VERSION ""

NS_ :

BS_:

BU_: ARS_FD SHVU_CCS_FD WPC_FD WPC2_FD SCM_FD SHVU_FRNT_FD GW_SAU_DRV_FD ATS_FD PSB_FD GW_PSU_RR_FD SHVU_RL_FD RWPC_FD CGW_CCU OHCL_FD SHVU_REAR_FD BLTN_CAM_FD GW_PSU_DRV_FD FCS_FD GW_PSU_AST_FD GW_PSU_3RD_FD RCS_FD SHVU_3RD_FD GW_PSU_RL_FD SHVU_RR_FD RCM_FD SGU_FD DCM_FD

BO_ 829 SBCM_RR_FD_01_200ms: 24 CGW_CCU
 SG_ SBCM_RR_FD_Crc1Val : 0|16@1+ (1,0) [0|0] "" Vector__XXX
 SG_ USM_RRGhostDoorSta : 100|2@1+ (1,0) [0|0] "" Vector__XXX
 SG_ DoorLock_PDSLkSwSta_RR : 104|2@1+ (1,0) [0|0] "" Vector__XXX
 SG_ PDS_TypeOption_RR : 106|2@1+ (1,0) [0|0] "" Vector__XXX
 SG_ RR_CrashMRActAlarm : 138|2@1+ (1,0) [0|0] "" Vector__XXX
 SG_ PwrDRBuzzerOut_RR : 140|2@1+ (1,0) [0|0] "" Vector__XXX
 SG_ PwrDRClosingRRDrSta : 144|3@1+ (1,0) [0|0] ""  ATS_FD
 SG_ AFH_RR_FldUnfldSta : 150|2@1+ (1,0) [0|0] "" Vector__XXX
 SG_ SBCM_RR_FD_AlvCnt1Val : 16|8@1+ (1,0) [0|0] "" Vector__XXX
 SG_ DoorLock_RrRtLkOutSta_SBCM : 166|2@1+ (1,0) [0|0] "" Vector__XXX
 SG_ RrRt_DrLkRetryFail_SBCM : 171|2@1+ (1,0) [0|0] "" Vector__XXX
 SG_ RR_DetectObj_warn : 24|2@1+ (1,0) [0|0] ""  ATS_FD
 SG_ RRRrDrCurtainPosition : 26|2@1+ (1,0) [0|0] ""  ATS_FD
 SG_ RRRrDrCurtainDownInitState : 28|2@1+ (1,0) [0|0] "" Vector__XXX
 SG_ PwrDrSta_RrRt : 30|2@1+ (1,0) [0|0] ""  ATS_FD
 SG_ PwrDRBuzzerOut_RR_New : 32|3@1+ (1,0) [0|0] "" Vector__XXX
 SG_ SBCM_RR_SlidePosition : 40|8@1+ (1,0) [0|0] "%"  ATS_FD
 SG_ SBCM_RR_DoorAngle : 48|7@1+ (1,0) [0|0] "˚"  ATS_FD
 SG_ RRDoorPushAlarm : 72|2@1+ (1,0) [0|0] "" Vector__XXX
 SG_ RR_CrashUnlockCmd : 74|1@1+ (1,0) [0|0] ""  BLTN_CAM_FD
 SG_ Warn_RrRtDrSwSta_SBCM : 80|2@1+ (1,0) [0|0] ""  ATS_FD,BLTN_CAM_FD,DCM_FD,GW_PSU_AST_FD,GW_PSU_RR_FD,PSB_FD,RWPC_FD,WPC2_FD,WPC_FD
 SG_ DoorLock_RrRtDrUnLkSta_SBCM : 82|2@1+ (1,0) [0|0] ""  ATS_FD,FCS_FD
 SG_ RR_SEAActivated : 84|2@1+ (1,0) [0|0] ""  ATS_FD
 SG_ RR_SEAWarn : 86|2@1+ (1,0) [0|0] ""  ATS_FD
 SG_ RR_SEWWarn : 88|2@1+ (1,0) [0|0] "" Vector__XXX
 SG_ RR_ReleaseWarn : 90|2@1+ (1,0) [0|0] "" Vector__XXX
 SG_ RR_SWFailAlarm : 92|2@1+ (1,0) [0|0] ""  ATS_FD
 SG_ RR_ChildLock_ActnFlSta : 94|2@1+ (1,0) [0|0] "" Vector__XXX
 SG_ RR_MRActivationAlarm : 96|2@1+ (1,0) [0|0] "" Vector__XXX
 SG_ RR_ChildLock_Status : 98|2@1+ (1,0) [0|0] "" Vector__XXX

BO_ 1025 BDC_FD_SMK_02_200ms: 32 CGW_CCU
 SG_ BDC_FD_SMK_Crc2Val : 0|16@1+ (1,0) [0|0] ""  GW_PSU_DRV_FD
 SG_ SMK_RpmLoByteVal : 104|8@1+ (1,0) [0|0] "" Vector__XXX
 SG_ SMK_VehSpdDrctVal : 112|8@1+ (1,0) [0|0] "" Vector__XXX
 SG_ Fob_BattStaInfo : 120|2@1+ (1,0) [0|0] "" Vector__XXX
 SG_ Fob_FoundDrvWlcmArea : 122|2@1+ (1,0) [0|0] "" Vector__XXX
 SG_ Fob_FoundAsstWlcmArea : 124|2@1+ (1,0) [0|0] "" Vector__XXX
 SG_ Fob_FoundExtrnlArea : 126|2@1+ (1,0) [0|0] "" Vector__XXX
 SG_ Fob_FoundIntArea : 128|2@1+ (1,0) [0|0] "" Vector__XXX
 SG_ Fob_LearntSta : 130|2@1+ (1,0) [0|0] "" Vector__XXX
 SG_ RSPA_LearntSta : 132|2@1+ (1,0) [0|0] "" Vector__XXX
 SG_ RSPA_RFSigErrSta : 134|2@1+ (1,0) [0|0] "" Vector__XXX
 SG_ RSPA_CanErrSta : 136|2@1+ (1,0) [0|0] "" Vector__XXX
 SG_ RSPA_ModSta_SMK : 138|3@1+ (1,0) [0|0] ""  GW_PSU_DRV_FD
 SG_ RSPA_FobBattSta : 141|3@1+ (1,0) [0|0] "" Vector__XXX
 SG_ Fob_BtnReleasedSta : 144|2@1+ (1,0) [0|0] "" Vector__XXX
 SG_ Fob_FoundWlcmArea : 146|2@1+ (1,0) [0|0] "" Vector__XXX
 SG_ USM_WALModSta : 148|3@1+ (1,0) [0|0] "" Vector__XXX
 SG_ USM_SmrtTrnkTlgtModSta : 152|3@1+ (1,0) [0|0] "" Vector__XXX
 SG_ USM_SAUModSta : 155|3@1+ (1,0) [0|0] "" Vector__XXX
 SG_ SMK_RLHndLkSnsrSta : 158|2@1+ (1,0) [0|0] "" Vector__XXX
 SG_ BDC_FD_SMK_AlvCnt2Val : 16|8@1+ (1,0) [0|0] ""  GW_PSU_DRV_FD
 SG_ SMK_RLDrHndUnLkSnsrSta : 160|2@1+ (1,0) [0|0] "" Vector__XXX
 SG_ SMK_RRDrHndLkSnsrSta : 162|2@1+ (1,0) [0|0] "" Vector__XXX
 SG_ SMK_RRDrHndUnLkSnsrSta : 164|2@1+ (1,0) [0|0] "" Vector__XXX
 SG_ Fob_FoundCabinArea : 166|2@1+ (1,0) [0|0] "" Vector__XXX
 SG_ SMK_ResultRmtStrt : 168|3@1+ (1,0) [0|0] "" Vector__XXX
 SG_ SMK_EncryptTeleOptSta : 171|2@1+ (1,0) [0|0] "" Vector__XXX
 SG_ Auth_ISKLearnSta2 : 173|3@1+ (1,0) [0|0] "" Vector__XXX
 SG_ Auth_ISKLearnSta : 176|3@1+ (1,0) [0|0] "" Vector__XXX
 SG_ SMK_TlPwrOnSta : 179|2@1+ (1,0) [0|0] "" Vector__XXX
 SG_ Fob_FoundForChargingDoor : 181|2@1+ (1,0) [0|0] "" Vector__XXX
 SG_ SSB_StrtStpBtnSw1Sta : 24|2@1+ (1,0) [0|0] "" Vector__XXX
 SG_ SSB_StrtStpBtnSw2Sta : 26|2@1+ (1,0) [0|0] "" Vector__XXX
 SG_ SMK_AuthSta : 28|3@1+ (1,0) [0|0] ""  GW_PSU_AST_FD,GW_PSU_DRV_FD,PSB_FD
 SG_ SMK_TlPwrOnOpt : 31|1@1+ (1,0) [0|0] "" Vector__XXX
 SG_ SMK_Ign1InSta : 32|2@1+ (1,0) [0|0] "" Vector__XXX
 SG_ SMK_Ign1RlySta : 34|2@1+ (1,0) [0|0] "" Vector__XXX
 SG_ SMK_Ign2InSta : 36|2@1+ (1,0) [0|0] "" Vector__XXX
 SG_ SMK_Ign2RlySta : 38|2@1+ (1,0) [0|0] "" Vector__XXX
 SG_ SMK_StrtFdbckSta : 40|2@1+ (1,0) [0|0] "" Vector__XXX
 SG_ SMK_StrtrRlyOutSta : 42|2@1+ (1,0) [0|0] "" Vector__XXX
 SG_ SMK_AccInSta : 44|2@1+ (1,0) [0|0] "" Vector__XXX
 SG_ SMK_AccRlySta : 46|2@1+ (1,0) [0|0] "" Vector__XXX
 SG_ SMK_CLUAccIndOnReq : 48|2@1+ (1,0) [0|0] "" Vector__XXX
 SG_ SMK_VDModeActSta : 50|2@1+ (1,0) [0|0] "" Vector__XXX
 SG_ SMK_SCULckUnlckSta : 52|2@1+ (1,0) [0|0] "" Vector__XXX
 SG_ SMK_TlEngRunSta : 54|2@1+ (1,0) [0|0] ""  ATS_FD,GW_PSU_3RD_FD,GW_PSU_AST_FD,GW_PSU_DRV_FD,GW_PSU_RL_FD,GW_PSU_RR_FD,GW_SAU_DRV_FD,SHVU_3RD_FD,SHVU_CCS_FD,SHVU_FRNT_FD,SHVU_REAR_FD,SHVU_RL_FD,SHVU_RR_FD
 SG_ SMK_TlCrnkModSta : 56|2@1+ (1,0) [0|0] ""  ATS_FD,GW_PSU_AST_FD,GW_PSU_DRV_FD,GW_SAU_DRV_FD,SCM_FD
 SG_ SMK_RmtKeyEngRunSta : 58|2@1+ (1,0) [0|0] "" Vector__XXX
 SG_ SMK_RmtKeyCrnkModSta : 60|2@1+ (1,0) [0|0] "" Vector__XXX
 SG_ SMK_AsstTgglBtnSta : 62|2@1+ (1,0) [0|0] "" Vector__XXX
 SG_ SMK_DrvTglBtnSta : 64|2@1+ (1,0) [0|0] "" Vector__XXX
 SG_ SMK_RrLftTglBtnSta : 66|2@1+ (1,0) [0|0] "" Vector__XXX
 SG_ SMK_RrRtTglBtnSta : 68|2@1+ (1,0) [0|0] "" Vector__XXX
 SG_ SMK_TgglBtnStuckSta : 70|2@1+ (1,0) [0|0] "" Vector__XXX
 SG_ SMK_AsstDrHndUnLkSnsrSta : 72|2@1+ (1,0) [0|0] "" Vector__XXX
 SG_ SMK_BrkSwSta : 74|2@1+ (1,0) [0|0] "" Vector__XXX
 SG_ SMK_GearPosPSwSta : 76|2@1+ (1,0) [0|0] "" Vector__XXX
 SG_ SMK_CltchIgnLkSwSta : 78|2@1+ (1,0) [0|0] "" Vector__XXX
 SG_ SMK_DrvDrHndLkSnsrSta : 80|2@1+ (1,0) [0|0] "" Vector__XXX
 SG_ SMK_DrvDrHndUnLkSnsrSta : 82|2@1+ (1,0) [0|0] "" Vector__XXX
 SG_ SMK_AsstDrHndLkSnsrSta : 84|2@1+ (1,0) [0|0] "" Vector__XXX
 SG_ LFAnt_FltSta : 86|2@1+ (1,0) [0|0] "" Vector__XXX
 SG_ LFAnt_SrchSta : 88|2@1+ (1,0) [0|0] ""  RWPC_FD,WPC2_FD,WPC_FD
 SG_ Lamp_HzrdBlnkngSta : 90|3@1+ (1,0) [0|0] "" Vector__XXX
 SG_ Lamp_SmrtWlcmLtOnReq : 93|2@1+ (1,0) [0|0] "" Vector__XXX
 SG_ SMK_RpmHiByteVal : 96|8@1+ (1,0) [0|0] "" Vector__XXX

BO_ 830 SBCM_RL_FD_01_200ms: 24 CGW_CCU
 SG_ SBCM_RL_FD_Crc1Val : 0|16@1+ (1,0) [0|0] "" Vector__XXX
 SG_ USM_RLGhostDoorSta : 100|2@1+ (1,0) [0|0] "" Vector__XXX
 SG_ DoorLock_PDSLkSwSta_RL : 104|2@1+ (1,0) [0|0] "" Vector__XXX
 SG_ PDS_TypeOption_RL : 106|2@1+ (1,0) [0|0] "" Vector__XXX
 SG_ RL_CrashMRActAlarm : 138|2@1+ (1,0) [0|0] "" Vector__XXX
 SG_ PwrDRBuzzerOut_RL : 140|2@1+ (1,0) [0|0] "" Vector__XXX
 SG_ PwrDRClosingRLDrSta : 144|3@1+ (1,0) [0|0] ""  ATS_FD
 SG_ AFH_RL_FldUnfldSta : 150|2@1+ (1,0) [0|0] "" Vector__XXX
 SG_ SBCM_RL_FD_AlvCnt1Val : 16|8@1+ (1,0) [0|0] "" Vector__XXX
 SG_ DoorLock_RrLtLkOutSta_SBCM : 166|2@1+ (1,0) [0|0] "" Vector__XXX
 SG_ RrLt_DrLkRetryFail_SBCM : 171|2@1+ (1,0) [0|0] "" Vector__XXX
 SG_ RL_DetectObj_warn : 24|2@1+ (1,0) [0|0] ""  ATS_FD
 SG_ RLRrDrCurtainPosition : 26|2@1+ (1,0) [0|0] ""  ATS_FD
 SG_ RDC_TypeOption : 28|2@1+ (1,0) [0|0] ""  ATS_FD
 SG_ RLRrDrCurtainDownInitState : 30|2@1+ (1,0) [0|0] "" Vector__XXX
 SG_ PwrDRBuzzerOut_RL_New : 32|3@1+ (1,0) [0|0] "" Vector__XXX
 SG_ PwrDrSta_RrLt : 38|2@1+ (1,0) [0|0] ""  ATS_FD
 SG_ SBCM_RL_SlidePosition : 40|8@1+ (1,0) [0|0] "%"  ATS_FD
 SG_ SBCM_RL_DoorAngle : 48|7@1+ (1,0) [0|0] "˚"  ATS_FD
 SG_ RLDoorPushAlarm : 72|2@1+ (1,0) [0|0] "" Vector__XXX
 SG_ RL_CrashUnlockCmd : 74|1@1+ (1,0) [0|0] ""  BLTN_CAM_FD
 SG_ Warn_RrLftDrSwSta_SBCM : 80|2@1+ (1,0) [0|0] ""  ATS_FD,BLTN_CAM_FD,DCM_FD,GW_PSU_AST_FD,PSB_FD,RWPC_FD,WPC2_FD,WPC_FD
 SG_ DoorLock_RrLftDrUnLkSta_SBCM : 82|2@1+ (1,0) [0|0] ""  ATS_FD,FCS_FD
 SG_ RL_SEAActivated : 84|2@1+ (1,0) [0|0] ""  ATS_FD
 SG_ RL_SEAWarn : 86|2@1+ (1,0) [0|0] ""  ATS_FD
 SG_ RL_SEWWarn : 88|2@1+ (1,0) [0|0] "" Vector__XXX
 SG_ RL_ReleaseWarn : 90|2@1+ (1,0) [0|0] "" Vector__XXX
 SG_ RL_SWFailAlarm : 92|2@1+ (1,0) [0|0] ""  ATS_FD
 SG_ RL_ChildLock_ActnFlSta : 94|2@1+ (1,0) [0|0] "" Vector__XXX
 SG_ RL_MRActivationAlarm : 96|2@1+ (1,0) [0|0] "" Vector__XXX
 SG_ RL_ChildLock_Status : 98|2@1+ (1,0) [0|0] "" Vector__XXX

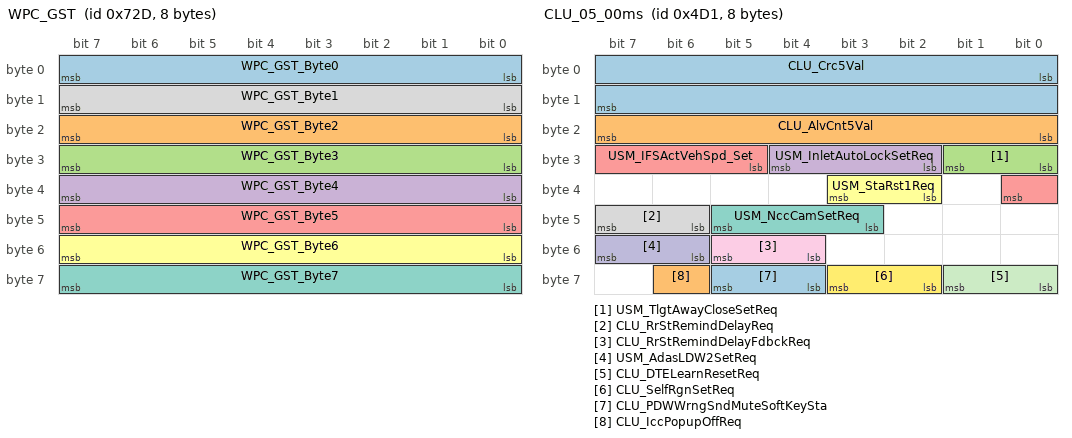
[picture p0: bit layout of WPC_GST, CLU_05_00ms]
BO_ 1837 WPC_GST: 8 WPC_FD
 SG_ WPC_GST_Byte0 : 0|8@1+ (1,0) [0|0] ""  CGW_CCU
 SG_ WPC_GST_Byte2 : 16|8@1+ (1,0) [0|0] ""  CGW_CCU
 SG_ WPC_GST_Byte3 : 24|8@1+ (1,0) [0|0] ""  CGW_CCU
 SG_ WPC_GST_Byte4 : 32|8@1+ (1,0) [0|0] ""  CGW_CCU
 SG_ WPC_GST_Byte5 : 40|8@1+ (1,0) [0|0] ""  CGW_CCU
 SG_ WPC_GST_Byte6 : 48|8@1+ (1,0) [0|0] ""  CGW_CCU
 SG_ WPC_GST_Byte7 : 56|8@1+ (1,0) [0|0] ""  CGW_CCU
 SG_ WPC_GST_Byte1 : 8|8@1+ (1,0) [0|0] ""  CGW_CCU

BO_ 256 EMS_02_10ms: 32 CGW_CCU
 SG_ EMS_Crc2Val : 0|16@1+ (1,0) [0|0] ""  GW_PSU_DRV_FD
 SG_ ACC_CrsMainSwLmpSta : 104|2@1+ (1,0) [0|0] "" Vector__XXX
 SG_ ACC_CrsSetSwLmpSta : 106|2@1+ (1,0) [0|0] "" Vector__XXX
 SG_ ENG_LV_FUP_ENA_THD : 109|1@1+ (1,0) [0|0] "" Vector__XXX
 SG_ ENG_SoakTimeErrSta : 110|2@1+ (1,0) [0|0] "" Vector__XXX
 SG_ ENG_SoakTimeVal : 112|8@1+ (1,0) [0|0] "Min" Vector__XXX
 SG_ ENG_SprkTimeVal : 120|8@1+ (0.375,-35.625) [0|0] "˚" Vector__XXX
 SG_ ENG_MinIndTqVal : 128|12@1- (1,0) [0|0] "Nm" Vector__XXX
 SG_ ENG_TrgtTqVal : 144|12@1- (1,0) [0|0] "Nm" Vector__XXX
 SG_ EMS_AlvCnt2Val : 16|8@1+ (1,0) [0|0] ""  GW_PSU_DRV_FD
 SG_ ENG_MaxIndTqVal : 160|12@1- (1,0) [0|0] "Nm" Vector__XXX
 SG_ ENG_AppAccelPdlSta : 176|2@1+ (1,0) [0|0] "" Vector__XXX
 SG_ ENG_BrkCtrlReq : 178|2@1+ (1,0) [0|0] "" Vector__XXX
 SG_ ACC_DnShftCtrlReq : 180|4@1+ (1,0) [0|0] "" Vector__XXX
 SG_ ENG_DclBrkCntrlReq : 192|12@1+ (0.001,-4.094) [0|0] "m/s^2" Vector__XXX
 SG_ ENG_BstPrsrVal : 204|12@1+ (1.322,0) [0|0] "hPa" Vector__XXX
 SG_ ENG_EngOilTempVal : 216|8@1+ (0.75,-40) [0|0] "℃" Vector__XXX
 SG_ ENG_AmbtTempModelVal : 224|8@1+ (0.5,-41) [0|0] "℃" Vector__XXX
 SG_ ENG_DpfWrngSta : 232|2@1+ (1,0) [0|0] "" Vector__XXX
 SG_ ENG_BattWrngLmpSta : 234|2@1+ (1,0) [0|0] "" Vector__XXX
 SG_ ENG_OilPrsrWrngLmpSta : 236|2@1+ (1,0) [0|0] "" Vector__XXX
 SG_ ENG_IsgInhbtLmpSta : 238|2@1+ (1,0) [0|0] ""  FCS_FD
 SG_ ENG_BrkSwSta : 32|2@1+ (1,0) [0|0] ""  BLTN_CAM_FD
 SG_ ENG_ObdFrzFrmSta : 34|6@1+ (1,0) [0|0] "" Vector__XXX
 SG_ ENG_EngClntTempVal : 40|8@1+ (0.75,-48) [0|0] "℃" Vector__XXX
 SG_ ENG_MafCrctVal : 48|8@1+ (0.00781,0) [0|0] "" Vector__XXX
 SG_ ENG_BattDscnctSta : 56|2@1+ (1,0) [0|0] "" Vector__XXX
 SG_ OBD_MilConfgVal : 58|3@1+ (1,0) [0|0] "" Vector__XXX
 SG_ ENG_EngSta : 61|3@1+ (1,0) [0|0] ""  BLTN_CAM_FD,GW_PSU_3RD_FD,GW_PSU_AST_FD,GW_PSU_DRV_FD,GW_PSU_RL_FD,GW_PSU_RR_FD,GW_SAU_DRV_FD,PSB_FD,RCM_FD,RWPC_FD,SCM_FD,SHVU_3RD_FD,SHVU_CCS_FD,SHVU_FRNT_FD,SHVU_REAR_FD,SHVU_RL_FD,SHVU_RR_FD,WPC2_FD,WPC_FD
 SG_ ENG_Ack4EngStpSta : 64|2@1+ (1,0) [0|0] "" Vector__XXX
 SG_ ENG_OverDrvOffReq : 66|2@1+ (1,0) [0|0] "" Vector__XXX
 SG_ ENG_AccActSta : 68|2@1+ (1,0) [0|0] "" Vector__XXX
 SG_ ENG_CltchOpSta : 70|2@1+ (1,0) [0|0] "" Vector__XXX
 SG_ EMS_BrkReq_Slope : 72|1@1+ (1,0) [0|0] "" Vector__XXX
 SG_ ENG_AccDrvAlertDisp : 74|2@1+ (1,0) [0|0] "" Vector__XXX
 SG_ DSL_GlowCtrlReq : 76|2@1+ (1,0) [0|0] "" Vector__XXX
 SG_ ENG_GlowLmpSta : 78|2@1+ (1,0) [0|0] "" Vector__XXX
 SG_ ENG_ThrPosVal : 80|8@1+ (0.4694836,-15.0234742) [0|0] "%" Vector__XXX
 SG_ ENG_AccelPdlVal : 88|10@1+ (0.09784,0) [0|0] "%"  BLTN_CAM_FD

BO_ 1233 CLU_05_00ms: 8 CGW_CCU
 SG_ CLU_Crc5Val : 0|16@1+ (1,0) [0|0] ""  GW_PSU_DRV_FD
 SG_ CLU_AlvCnt5Val : 16|8@1+ (1,0) [0|0] ""  GW_PSU_DRV_FD
 SG_ USM_TlgtAwayCloseSetReq : 24|2@1+ (1,0) [0|0] "" Vector__XXX
 SG_ USM_InletAutoLockSetReq : 26|3@1+ (1,0) [0|0] "" Vector__XXX
 SG_ USM_IFSActVehSpd_Set : 29|4@1+ (1,0) [0|0] "" Vector__XXX
 SG_ USM_StaRst1Req : 34|2@1+ (1,0) [0|0] ""  GW_PSU_DRV_FD,WPC2_FD,WPC_FD
 SG_ USM_NccCamSetReq : 43|3@1+ (1,0) [0|0] "" Vector__XXX
 SG_ CLU_RrStRemindDelayReq : 46|2@1+ (1,0) [0|0] "" Vector__XXX
 SG_ CLU_RrStRemindDelayFdbckReq : 52|2@1+ (1,0) [0|0] "" Vector__XXX
 SG_ USM_AdasLDW2SetReq : 54|2@1+ (1,0) [0|0] "" Vector__XXX
 SG_ CLU_DTELearnResetReq : 56|2@1+ (1,0) [0|0] "" Vector__XXX
 SG_ CLU_SelfRgnSetReq : 58|2@1+ (1,0) [0|0] "" Vector__XXX
 SG_ CLU_PDWWrngSndMuteSoftKeySta : 60|2@1+ (1,0) [0|0] "" Vector__XXX
 SG_ CLU_IccPopupOffReq : 62|1@1+ (1,0) [0|0] "" Vector__XXX

BO_ 870 HU_GW_03_200ms: 24 CGW_CCU
 SG_ HU_GW_Crc3Val : 0|16@1+ (1,0) [0|0] ""  GW_PSU_DRV_FD
 SG_ AVN_RSPA_Disp_Rdy : 102|2@1+ (1,0) [0|0] "" Vector__XXX
 SG_ CF_AVN_ProfileIDRValue : 104|4@1+ (1,0) [0|0] ""  BLTN_CAM_FD,GW_PSU_DRV_FD,GW_SAU_DRV_FD,RCM_FD,RWPC_FD,SGU_FD,WPC2_FD,WPC_FD
 SG_ HazardFromHUSVM : 108|2@1+ (1,0) [0|0] "" Vector__XXX
 SG_ OMUOSMirCtrl : 110|2@1+ (1,0) [0|0] "" Vector__XXX
 SG_ OTAUIStatus : 120|2@1+ (1,0) [0|0] "" Vector__XXX
 SG_ C_TeleActiveStatus : 122|2@1+ (1,0) [0|0] "" Vector__XXX
 SG_ HU_RTCCheck : 126|2@1+ (1,0) [0|0] ""  GW_PSU_AST_FD
 SG_ HU_GW_AlvCnt3Val : 16|8@1+ (1,0) [0|0] ""  GW_PSU_DRV_FD
 SG_ HU_SWRCWarmerSet : 182|2@1+ (1,0) [0|0] "" Vector__XXX
 SG_ HU_TrModeReq_PE : 24|3@1+ (1,0) [0|0] "" Vector__XXX
 SG_ HU_TrBrakeTypeReq_PE : 27|3@1+ (1,0) [0|0] "" Vector__XXX
 SG_ AVN_MRA_Disp_Rdy : 56|2@1+ (1,0) [0|0] "" Vector__XXX
 SG_ AVN_PRK_Func_Selected : 58|4@1+ (1,0) [0|0] "" Vector__XXX
 SG_ AVN_MRA_CancelInput : 62|2@1+ (1,0) [0|0] "" Vector__XXX
 SG_ HU_DistanceUnit : 64|2@1+ (1,0) [0|0] "" Vector__XXX
 SG_ HU_Scheduled_Setting : 66|4@1+ (1,0) [0|0] "" Vector__XXX
 SG_ HU_AliveStatus : 70|2@1+ (1,0) [0|0] "" Vector__XXX
 SG_ HU_ThemeType : 74|6@1+ (1,0) [0|0] ""  ATS_FD,BLTN_CAM_FD
 SG_ HU_MicActivity : 81|2@1+ (1,0) [0|0] "" Vector__XXX
 SG_ AVN_RSPA_ModeSelect : 84|4@1+ (1,0) [0|0] "" Vector__XXX
 SG_ CF_HU_GPSFlt : 88|2@1+ (1,0) [0|0] "" Vector__XXX
 SG_ AVN_RSPA_CancelInput : 90|2@1+ (1,0) [0|3] "" Vector__XXX

BO_ 261 EMS_07_10ms: 32 CGW_CCU
 SG_ EMS_Crc7Val : 0|16@1+ (1,0) [0|0] "" Vector__XXX
 SG_ HEV_AccelPdlVal : 103|10@1+ (0.09784,0) [0|0] "%"  BLTN_CAM_FD
 SG_ HEV_IndTqTar : 113|8@1+ (0.3906,0) [0|0] "%" Vector__XXX
 SG_ HEV_IndTqVal_Extd : 128|14@1+ (0.1,0) [0|0] "Nm" Vector__XXX
 SG_ EMS_AlvCnt7Val : 16|8@1+ (1,0) [0|0] "" Vector__XXX
 SG_ HEV_IndTqVal : 24|12@1+ (0.1,0) [0|0] "Nm" Vector__XXX
 SG_ HEV_DrvTqVal : 36|12@1+ (0.390625,0) [0|0] "%" Vector__XXX
 SG_ HEV_TqStndVal : 48|6@1+ (10,0) [0|0] "Nm" Vector__XXX
 SG_ HEV_OilDilution_IncICELoad : 54|1@1+ (1,0) [0|0] "" Vector__XXX
 SG_ HEV_OilDilution_ServMode : 56|2@1+ (1,0) [0|0] "" Vector__XXX
 SG_ EMS_TqLmtSta : 58|3@1+ (1,0) [0|0] "" Vector__XXX
 SG_ EMS_EU7 : 61|1@1+ (1,0) [0|0] "" Vector__XXX
 SG_ HEV_FrctTqVal : 64|12@1+ (0.1,0) [0|0] "Nm" Vector__XXX
 SG_ HEV_EngSpdVal : 76|16@1+ (0.25,0) [0|0] "rpm" Vector__XXX
 SG_ HEV_EngOpSta : 92|3@1+ (1,0) [0|0] ""  GW_PSU_3RD_FD,RWPC_FD,WPC2_FD,WPC_FD
 SG_ HEV_IntakeAirTempVal : 95|8@1+ (0.75,-48) [0|0] "℃" Vector__XXX

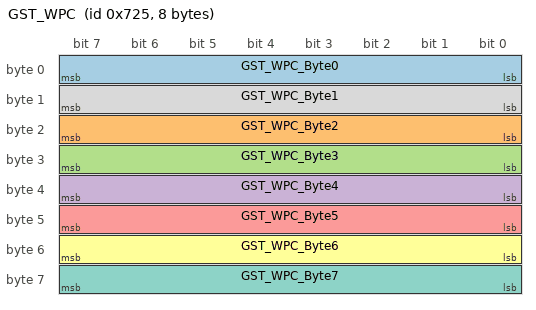
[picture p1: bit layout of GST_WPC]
BO_ 1829 GST_WPC: 8 CGW_CCU
 SG_ GST_WPC_Byte0 : 0|8@1+ (1,0) [0|0] ""  WPC_FD
 SG_ GST_WPC_Byte2 : 16|8@1+ (1,0) [0|0] ""  WPC_FD
 SG_ GST_WPC_Byte3 : 24|8@1+ (1,0) [0|0] ""  WPC_FD
 SG_ GST_WPC_Byte4 : 32|8@1+ (1,0) [0|0] ""  WPC_FD
 SG_ GST_WPC_Byte5 : 40|8@1+ (1,0) [0|0] ""  WPC_FD
 SG_ GST_WPC_Byte6 : 48|8@1+ (1,0) [0|0] ""  WPC_FD
 SG_ GST_WPC_Byte7 : 56|8@1+ (1,0) [0|0] ""  WPC_FD
 SG_ GST_WPC_Byte1 : 8|8@1+ (1,0) [0|0] ""  WPC_FD

CM_ BO_ 829 "[PE] Periodic and On Event";
CM_ SG_ 829 SBCM_RR_FD_Crc1Val "SBCM_RR_FD_CyclicRedundancyCheck1Value";
CM_ SG_ 829 SBCM_RR_FD_AlvCnt1Val "SBCM_RR_FD_AliveCounter1Value";
CM_ SG_ 829 RR_CrashUnlockCmd "Rear Right Crash Unlock Command";
CM_ SG_ 829 Warn_RrRtDrSwSta_SBCM "Warn_RearRightDoorSwitchStatus ##2G## -  - C_RRDrSw,CF_Gway_RRDrSw,Warn_RrRtDrSwSta";
CM_ SG_ 829 DoorLock_RrRtDrUnLkSta_SBCM "DoorLock_RearRightDoorUnLockStatus ##2G## -  - C_RRUnlockState,DoorLock_RrRtDrUnLkSta";
CM_ SG_ 829 RR_SEAActivated "Rear Right SEA Activated";
CM_ SG_ 829 RR_SEAWarn "Rear Righr SEA Warning";
CM_ BO_ 1025 "[PE] Periodic and On Event";
CM_ SG_ 1025 BDC_FD_SMK_Crc2Val "BDC_FD_SMK_CyclicRedundancyCheck2Value";
CM_ SG_ 1025 SMK_RpmLoByteVal "SMK_RpmLowByteValue ##2G##SMK - SMKmsg65 - C_RPMLowByte";
CM_ SG_ 1025 SMK_VehSpdDrctVal "SMK_VehicleSpeedDirectValue ##2G##SMK - SMKmsg65 - C_VehicleSpeedDirect";
CM_ SG_ 1025 Fob_BattStaInfo "Fob_BatteryStatusInformation ##2G##SMK - SMKmsg17 - C_FOBBatteryStatusInfo";
CM_ SG_ 1025 Fob_FoundDrvWlcmArea "Fob_FoundDriverWelcomeArea ##2G##SMK - SMKmsg17 - C_WelcomeFobFoundDrv";
CM_ SG_ 1025 Fob_FoundAsstWlcmArea "Fob_FoundAssistWelcomeArea ##2G##SMK - SMKmsg17 - C_WelcomeFobFoundAst";
CM_ SG_ 1025 Fob_FoundExtrnlArea "Fob_FoundExternalArea ##2G##SMK - SMKmsg18 - C_ExtFobPos";
CM_ SG_ 1025 Fob_FoundIntArea "Fob_FoundInternalArea ##2G##SMK - SMKmsg18 - C_IntFobPos";
CM_ SG_ 1025 Fob_LearntSta "Fob_LearntStatus ##2G##SMK - SMKmsg18 - C_FobLearntState";
CM_ SG_ 1025 RSPA_RFSigErrSta "RSPA_RFSignalErrorState";
CM_ SG_ 1025 RSPA_CanErrSta "RSPA_CANErrorState";
CM_ SG_ 1025 RSPA_ModSta_SMK "RSPA_ModeStatus ##2G##SMK - SMKmsg18 - C_SMKRSPAMode";
CM_ SG_ 1025 RSPA_FobBattSta "RSPA_FobBatteryStatus ##2G##SMK - SMKmsg18 - C_FobBATState";
CM_ SG_ 1025 Fob_FoundWlcmArea "Fob_FoundWlcmArea ##2G##SMK - SMKmsg17 -C_FobFoundWlcmArea";
CM_ SG_ 1025 USM_WALModSta "USM_WalkAwayLockModeStatus ##2G##SMK - SMKmsg20 - C_WALRValue";
CM_ SG_ 1025 USM_SmrtTrnkTlgtModSta "USM_SmartTunkTailgateModeStatus ##2G##SMK - SMKmsg20 - C_HfreeTrunkTgRValue";
CM_ SG_ 1025 BDC_FD_SMK_AlvCnt2Val "BDC_FD_SMK_AliveCounter2Value";
CM_ SG_ 1025 SMK_ResultRmtStrt "This signal is used to check for Tele Engine Running Result.";
CM_ SG_ 1025 SMK_EncryptTeleOptSta "This signal is used to check for option applied Remote Start Encryption.";
CM_ SG_ 1025 Auth_ISKLearnSta2 "This signal is State of IAU Learning for New China BLE";
CM_ SG_ 1025 Auth_ISKLearnSta "Fob_FoundAssistWelcomeArea ##2G##SMK - SMKmsg178 - C_IBUISKLearnState";
CM_ SG_ 1025 SMK_TlPwrOnSta "This signal is state of Tele Power On";
CM_ SG_ 1025 SSB_StrtStpBtnSw1Sta "SSB_StartStopButtonSwitch1Status ##2G##SMK - SMKmsg19 - C_SSBSW1";
CM_ SG_ 1025 SSB_StrtStpBtnSw2Sta "SSB_StartStopButtonSwitch2Status ##2G##SMK - SMKmsg19 - C_SSBSW2";
CM_ SG_ 1025 SMK_AuthSta "SMK_AuthentificationStatus ##2G##SMK - SMKmsg18 - C_AuthState";
CM_ SG_ 1025 SMK_TlPwrOnOpt "This signal is used to check option status of Tele Power On";
CM_ SG_ 1025 SMK_Ign1InSta "SMK_Ign1InputStatus ##2G##SMK - SMKmsg19 - C_Ign1SMK";
CM_ SG_ 1025 SMK_Ign1RlySta "SMK_Ign1RelayStatus ##2G##SMK - SMKmsg19 - C_Ign1RelayState";
CM_ SG_ 1025 SMK_Ign2InSta "SMK_Ign2InputStatus ##2G##SMK - SMKmsg19 - C_Ign2SMK";
CM_ SG_ 1025 SMK_Ign2RlySta "SMK_Ign2RelayStatus ##2G##SMK - SMKmsg19 - C_Ign2RelayState";
CM_ SG_ 1025 SMK_StrtFdbckSta "SMK_StartFeedbackStatus ##2G##SMK - SMKmsg19 - C_StartFeedback";
CM_ SG_ 1025 SMK_StrtrRlyOutSta "SMK_StarterRelayOutputStatus ##2G##SMK - SMKmsg18 - C_StarterRlyState";
CM_ SG_ 1025 SMK_AccInSta "SMK_AccInputStatus ##2G##SMK - SMKmsg19 - C_AccSMK";
CM_ SG_ 1025 SMK_AccRlySta "SMK_AccRelayStatus ##2G##SMK - SMKmsg19 - C_AccRelayStatus";
CM_ SG_ 1025 SMK_CLUAccIndOnReq "SMK_ClusterACCIndicatorOnRequest ##2G##SMK - SMKmsg19 - C_AccINDforCLU";
CM_ SG_ 1025 SMK_VDModeActSta "SMK_VirtualDriverModeActState";
CM_ SG_ 1025 SMK_SCULckUnlckSta "SCU Lock/Unlock Status";
CM_ SG_ 1025 SMK_TlEngRunSta "SMK_TeleEngineRunStatus ##2G##SMK - SMKmsg18 - C_SMKTeleEngineRunning";
CM_ SG_ 1025 SMK_TlCrnkModSta "SMK_TeleCrankingModeStatus ##2G##SMK - SMKmsg18 - C_SMKTeleCrankingState";
CM_ SG_ 1025 SMK_RmtKeyEngRunSta "SMK_RemoteKeyEngineRunStatus";
CM_ SG_ 1025 SMK_RmtKeyCrnkModSta "SMK_RemoteKeyCrankingModeStatus";
CM_ SG_ 1025 SMK_AsstTgglBtnSta "SMK_AssistToggleButtonStatus ##2G##SMK - SMKmsg19 - C_AstToggleButton";
CM_ SG_ 1025 SMK_DrvTglBtnSta "SMK_DriverToggleButtonStatus ##2G##SMK - SMKmsg19 - C_DrvToggleButton";
CM_ SG_ 1025 SMK_RrLftTglBtnSta "SMK_RearLeftToggleButtonStatus ##2G##SMK - SMKmsg19 - C_RRDRVToggleButton";
CM_ SG_ 1025 SMK_RrRtTglBtnSta "SMK_RearRightToggleButtonStatus ##2G##SMK - SMKmsg19 - C_RRASTToggleButton";
CM_ SG_ 1025 SMK_TgglBtnStuckSta "SMK_ToggleButtonStuckStatus ##2G##SMK - SMKmsg18 - C_ToggleButtonStuck";
CM_ SG_ 1025 SMK_AsstDrHndUnLkSnsrSta "SMK_AssistToggleButtonStatus ##2G##SMK - SMKmsg19 - C_ASTDoorUnLock";
CM_ SG_ 1025 SMK_BrkSwSta "SMK_BrakeSwitchStatus ##2G##SMK - SMKmsg19 - C_BrakeSW";
CM_ SG_ 1025 SMK_GearPosPSwSta "SMK_GearPositionPSwitchStatus ##2G##SMK - SMKmsg19 - C_PpositionClutch";
CM_ SG_ 1025 SMK_CltchIgnLkSwSta "SMK_ClutchIgnLockSwitchStatus ##2G##SMK - SMKmsg19 - C_ClutchIgnLockSW";
CM_ SG_ 1025 SMK_DrvDrHndLkSnsrSta "SMK_DriverToggleButtonStatus ##2G##SMK - SMKmsg19 - C_DRVDoorLock";
CM_ SG_ 1025 SMK_DrvDrHndUnLkSnsrSta "SMK_AssistToggleButtonStatus ##2G##SMK - SMKmsg19 - C_DRVDoorUnlock";
CM_ SG_ 1025 SMK_AsstDrHndLkSnsrSta "SMK_AssistToggleButtonStatus ##2G##SMK - SMKmsg19 - C_ASTDoorLock";
CM_ SG_ 1025 LFAnt_FltSta "LFAntenna_FaultSatus ##2G##SMK - SMKmsg18 - C_LFANTState";
CM_ SG_ 1025 LFAnt_SrchSta "LFAntenna_SearchingStatus ##2G##SMK - SMKmsg19 - C_LFSearchingOn";
CM_ SG_ 1025 Lamp_HzrdBlnkngSta "Lamp_HazardBlinkingStatus ##2G##SMK - SMKmsg17 - C_HazardFromSMK";
CM_ SG_ 1025 Lamp_SmrtWlcmLtOnReq "Lamp_SmartWelcomeLightOnRequest ##2G##SMK - SMKmsg17 - C_WlightOn";
CM_ SG_ 1025 SMK_RpmHiByteVal "SMK_RpmHighByteValue ##2G##SMK - SMKmsg65 - C_RPMHighByte";
CM_ BO_ 830 "[PE] Periodic and On Event";
CM_ SG_ 830 SBCM_RL_FD_Crc1Val "SBCM_RL_FD_CyclicRedundancyCheck1Value";
CM_ SG_ 830 SBCM_RL_FD_AlvCnt1Val "SBCM_RL_FD_AliveCounter1Value";
CM_ SG_ 830 RL_CrashUnlockCmd "Rear Lefr Crash Unlock Command";
CM_ SG_ 830 Warn_RrLftDrSwSta_SBCM "Warn_RearLeftDoorSwitchStatus ##2G## -  - C_RLDrSw,CF_Gway_RLDrSw,Warn_RrLftDrSwSta";
CM_ SG_ 830 DoorLock_RrLftDrUnLkSta_SBCM "DoorLock_RearLeftDoorUnLockStatus ##2G## -  - C_RLUnlockState,DoorLock_RrLftDrUnLkSta";
CM_ SG_ 830 RL_SEAActivated "RearLeftSEAActivated";
CM_ SG_ 830 RL_SEAWarn "Rear Left SEA Warning";
CM_ BO_ 1837 "[TP] Transport Protocol";
CM_ BO_ 256 "[P] Periodic";
CM_ SG_ 256 EMS_Crc2Val "EMS_CyclicRedundancyCheck2Value";
CM_ SG_ 256 ACC_CrsMainSwLmpSta "ACC_CruiseMainSwLampStatus ##2G##EMS - EMS16 - CRUISE_LAMP_M";
CM_ SG_ 256 ACC_CrsSetSwLmpSta "ACC_CruiseSetSwLampStatus ##2G##EMS - EMS16 - CRUISE_LAMP_S";
CM_ SG_ 256 ENG_LV_FUP_ENA_THD "Fuel prsssure state ##2G##EMS - LPI11 - LV_FUP_ENA_THD";
CM_ SG_ 256 ENG_SoakTimeErrSta "ENG_SoakTimeErrorStatus ##2G##EMS - EMS16 - SOAK_TIME_ERROR";
CM_ SG_ 256 ENG_SoakTimeVal "ENG_SoakTimeValue ##2G##EMS - EMS16 - SOAK_TIME";
CM_ SG_ 256 ENG_SprkTimeVal "ENG_SparkTimeValue ##2G##EMS - EMS16 - SPK_TIME_CUR";
CM_ SG_ 256 ENG_MinIndTqVal "ENG_MinimumIndicatedTorqueValue ##2G##EMS - EMS16 - TQI_MIN";
CM_ SG_ 256 ENG_TrgtTqVal "ENG_TargetTorqueValue ##2G##EMS - EMS16 - TQI_TARGET";
CM_ SG_ 256 EMS_AlvCnt2Val "EMS_AliveCounter2Value";
CM_ SG_ 256 ENG_MaxIndTqVal "ENG_MaximumIndicatedTorqueValue ##2G##EMS - EMS16 - TQI_MAX";
CM_ SG_ 256 ENG_AppAccelPdlSta "ENG_AppliedAcceleratorPedalStatus ##2G##EMS - EMS16 - CF_Ems_AclAct";
CM_ SG_ 256 ENG_BrkCtrlReq "ENG_BrakeControlRequest ##2G##EMS - EMS19 - CF_Ems_BrkReq";
CM_ SG_ 256 ACC_DnShftCtrlReq "ACC_DownShiftControlRequest ##2G##EMS - EMS19 - CF_Ems_DnShftReq";
CM_ SG_ 256 ENG_DclBrkCntrlReq "ENG_DecelerationBrakeControlRequest ##2G##EMS - EMS19 - CF_Ems_DecelReq";
CM_ SG_ 256 ENG_BstPrsrVal "ENG_BoostPressureValue ##2G##EMS - EMS19 - CR_Ems_BstPre";
CM_ SG_ 256 ENG_EngOilTempVal "ENG_EngineOilTemperatureValue ##2G##EMS - EMS19 - CR_Ems_EngOilTemp";
CM_ SG_ 256 ENG_AmbtTempModelVal "ENG_AmbientTemperatureModelValue ##2G##EMS - EMS19 - CF_Ems_ModeledAmbTemp";
CM_ SG_ 256 ENG_DpfWrngSta "ENG_DpfWarningStatus ##2G##EMS - EMS19 - DPF_LAMP_STAT";
CM_ SG_ 256 ENG_BattWrngLmpSta "ENG_BatteryWarningLampStatus ##2G##EMS - EMS19 - BAT_LAMP_STAT";
CM_ SG_ 256 ENG_OilPrsrWrngLmpSta "ENG_OilPressureWarningLampStatus ##2G##EMS - EMS19 - CF_Ems_OPSFail";
CM_ SG_ 256 ENG_IsgInhbtLmpSta "ENG_IsgInhibitLampStatus ##2G##EMS - EMS19 - ISG_INHIBIT_LAMP_STAT";
CM_ SG_ 256 ENG_BrkSwSta "ENG_BrakeSwitchStatus ##2G##EMS - EMS12 - BRAKE_ACT";
CM_ SG_ 256 ENG_ObdFrzFrmSta "ENG_ObdFreezeFrameStatus ##2G##EMS - EMS12 - OBD_FRF_ACK";
CM_ SG_ 256 ENG_EngClntTempVal "ENG_EngineCoolantTemperatureValue ##2G##EMS - EMS12 - TEMP_ENG";
CM_ SG_ 256 ENG_MafCrctVal "ENG_MassAirFlowCorrectionValue ##2G##EMS - EMS12 - MAF_FAC_ALTI_MMV";
CM_ SG_ 256 ENG_BattDscnctSta "ENG_BatteryDisconnectStatus ##2G##EMS - EMS12 - VB_OFF_ACT";
CM_ SG_ 256 OBD_MilConfgVal "OBD_MalfunctionIndicationLampConfigurationValue ##2G##EMS - EMS12 - CONF_MIL_FMY";
CM_ SG_ 256 ENG_EngSta "ENG_EngineStatus ##2G##EMS - EMS16 - ENG_STAT";
CM_ SG_ 256 ENG_Ack4EngStpSta "ENG_AcknowledgeForEngineStopStatus ##2G##EMS - EMS12 - ACK_ES";
CM_ SG_ 256 ENG_OverDrvOffReq "ENG_OverDriveOffRequest ##2G##EMS - EMS12 - OD_OFF_REQ";
CM_ SG_ 256 ENG_AccActSta "ENG_AutoCruiseControlActiveStatus ##2G##EMS - EMS12 - ACC_ACT";
CM_ SG_ 256 ENG_CltchOpSta "ENG_ClutchStatus ##2G##EMS - EMS12 - CLU_ACK";
CM_ SG_ 256 EMS_BrkReq_Slope "Brake request at slope for anti-stall";
CM_ SG_ 256 ENG_AccDrvAlertDisp "The status of No Auto cruise Engaged or Auto cruise Disengaged.";
CM_ SG_ 256 DSL_GlowCtrlReq "DSL_GlowControlRequest ##2G##EMS - EMS12 - GP_CTL";
CM_ SG_ 256 ENG_GlowLmpSta "ENG_GlowLampStatus ##2G##EMS - EMS16 - GLOW_STAT";
CM_ SG_ 256 ENG_ThrPosVal "ENG_ThrottlePositionValue ##2G##EMS - EMS12 - TPS";
CM_ SG_ 256 ENG_AccelPdlVal "ENG_AcceleratorPedalValue ##2G##EMS - EMS12 - PV_AV_CAN";
CM_ BO_ 1233 "[EC] On Event and On Change";
CM_ SG_ 1233 CLU_Crc5Val "CLU_CyclicRedundancyCheck5Value";
CM_ SG_ 1233 CLU_AlvCnt5Val "CLU_AliveCounter5Value";
CM_ SG_ 1233 USM_TlgtAwayCloseSetReq "USM for Tailgate Away Close system";
CM_ SG_ 1233 USM_InletAutoLockSetReq "2nd General Signal: CLU22/CF_Clu_InletAutoLockNValueSet";
CM_ SG_ 1233 USM_IFSActVehSpd_Set "IFS 진입 속도 설정 메뉴";
CM_ SG_ 1233 USM_StaRst1Req "USM_StatusReset1Request";
CM_ SG_ 1233 USM_NccCamSetReq "USM_NccCameraSetRequest";
CM_ SG_ 1233 CLU_RrStRemindDelayReq "This singal is the delay request for ROA";
CM_ SG_ 1233 CLU_RrStRemindDelayFdbckReq "user input feedback for Rear Seat Reminder";
CM_ SG_ 1233 USM_AdasLDW2SetReq "This signal is used for a request to set the value of USM Menus. This signal requests to change status of LDW Mode.";
CM_ SG_ 1233 CLU_SelfRgnSetReq "on/off request for self regenerative system";
CM_ SG_ 1233 CLU_PDWWrngSndMuteSoftKeySta "To mute the PDW warning sound";
CM_ SG_ 1233 CLU_IccPopupOffReq "It is a signal for request to Icc pop-up off.";
CM_ BO_ 870 "[PE] Periodic and On Event";
CM_ SG_ 870 HU_GW_Crc3Val "HU_GW_CyclicRedundancyCheck3Value";
CM_ SG_ 870 AVN_RSPA_Disp_Rdy "Signal to inform RSPA of AVN's display ready status
(RSPA 화면 표시 가능/불가능 상태를 알리기 위한 신호)";
CM_ SG_ 870 CF_AVN_ProfileIDRValue "This signal is User ID value in H/Unit.";
CM_ SG_ 870 HazardFromHUSVM "This signal is for Hazard control";
CM_ SG_ 870 OMUOSMirCtrl "This signal is for the OutSide Mirror Control (Fold or Unfold)";
CM_ SG_ 870 OTAUIStatus "Information of the status of Head Unit";
CM_ SG_ 870 C_TeleActiveStatus "This signal is for check TMS active status";
CM_ SG_ 870 HU_RTCCheck "Checking whether RTC of AVN and HCU is operationg normally.";
CM_ SG_ 870 HU_GW_AlvCnt3Val "HU_GW_AliveCounter3Value";
CM_ SG_ 870 HU_SWRCWarmerSet "HU SW button touch command for SWRC Warmer";
CM_ SG_ 870 HU_TrModeReq_PE "Trailer/Carrier Mode On/Off request";
CM_ SG_ 870 HU_TrBrakeTypeReq_PE "Trailer Brake Type request";
CM_ SG_ 870 HU_DistanceUnit "Request to set CLU Distance Unit";
CM_ SG_ 870 HU_AliveStatus "Information of the status of Head Unit
0x00 : Headunit is booting so, Headunit cant display any state
0x01 : Headunit is normal state, Headunit could display according to MM CAN  command.
0x02 : Headunit is doing their internal process, so Headunit cant communicate with other node.
For CLU/SCC/eCall
-AVN System transmission signal";
CM_ SG_ 870 HU_MicActivity "HU send this signal to eCall for MIC using status.
eCall unit stop the diagonosis when received 0x1:Activated from HU
Otherwise, eCall unit keep diagnosis every 1 sec. and HU can not use MIC";
CM_ SG_ 870 CF_HU_GPSFlt "Information of GPS Fault 

0x0: Normal
0x1 : Fault operation
0x2 : RESERVED
0x3:Invalid";
CM_ SG_ 870 AVN_RSPA_CancelInput "Request Signal to cancel RSPA function";
CM_ BO_ 261 "[P] Periodic";
CM_ SG_ 261 EMS_Crc7Val "EMS_CyclicRedundancyCheck7Value";
CM_ SG_ 261 HEV_AccelPdlVal "HEV_AcceleratorPedalValue";
CM_ SG_ 261 HEV_IndTqTar "HEV_IndicatedTorqueTarget";
CM_ SG_ 261 HEV_IndTqVal_Extd "HEV_IndicatedTorqueValue_Extended";
CM_ SG_ 261 EMS_AlvCnt7Val "EMS_AliveCounter7Value";
CM_ SG_ 261 HEV_IndTqVal "HEV_IndicatedTorqueValue";
CM_ SG_ 261 HEV_DrvTqVal "HEV_DriverTorqueValue";
CM_ SG_ 261 HEV_TqStndVal "HEV_TorqueStandardValue";
CM_ SG_ 261 HEV_OilDilution_IncICELoad "HEV Oil Dilution Increase ICE Load";
CM_ SG_ 261 HEV_OilDilution_ServMode "HEV Oil Dilution Service Mode";
CM_ SG_ 261 EMS_TqLmtSta "Status of Torque Limit. Reference for TMS Cooperative control and Cluster notification";
CM_ SG_ 261 EMS_EU7 "Whether the vehicle is EU7 or not";
CM_ SG_ 261 HEV_FrctTqVal "HEV_FrictionTorqueValue";
CM_ SG_ 261 HEV_EngSpdVal "HEV_EngineSpeedValue";
CM_ SG_ 261 HEV_EngOpSta "HEV_EngineOperatingStatus";
CM_ SG_ 261 HEV_IntakeAirTempVal "HEV_IntakeAirTemperatureValue";
CM_ BO_ 1829 "[TP] Transport Protocol";
BA_DEF_ BO_  "CANFD_BRS" ENUM  "0","1";
BA_DEF_ BO_  "GenMsgEVName" STRING ;
BA_DEF_ BO_  "NmAsrMessage" ENUM  "No","Yes";
BA_DEF_ BO_  "DiagState" ENUM  "No","Yes";
BA_DEF_ BO_  "DiagResponse" ENUM  "No","Yes";
BA_DEF_ BO_  "DiagRequest" ENUM  "No","Yes";
BA_DEF_ BO_  "TpMessage" ENUM  "No","Yes";
BA_DEF_ BO_  "UsrMsgIDSforwardDeviation" INT 0 100;
BA_DEF_ BO_  "UsrMsgIDSbackwardDeviation" INT 50 1000;
BA_DEF_ BO_  "GenMsgCycleTime" INT 0 2000;
BA_DEF_ BO_  "GenMsgStartDelayTime" INT 0 2000;
BA_DEF_ BO_  "GenMsgSendType" ENUM  "Cyclic","NoMsgSendType";
BA_DEF_ BO_  "GenMsgCycleTimeFast" INT 0 500;
BA_DEF_ BO_  "GenMsgDelayTime" INT 0 20;
BA_DEF_ BO_  "GenMsgILSupport" ENUM  "No","Yes";
BA_DEF_ BO_  "GenMsgNrOfRepetition" INT 0 3;
BA_DEF_ BO_  "TpTxIndex" INT 0 65535;
BA_DEF_ BO_  "VFrameFormat" ENUM  "StandardCAN","ExtendedCAN","reserved","reserved","reserved","reserved","reserved","reserved","reserved","reserved","reserved","reserved","reserved","reserved","StandardCAN_FD","ExtendedCAN_FD";
BA_DEF_ SG_  "UserSigValidity" ENUM  "B+","ACC","IG","IG1","IG2","IG3","IG1 or IG2","IG1 or IG3","Undef";
BA_DEF_ SG_  "TimeoutValue" STRING ;
BA_DEF_ SG_  "UsrSigPurpose" ENUM  "Undef","FN","DIAG","DIAG(Req)","DIAG(Res)","DIAG(Func)","DEV","CCP","NM","TP";
BA_DEF_ SG_  "GenSigStartValue" INT 0 1215752192;
BA_DEF_ SG_  "NetworkRequest" ENUM  "Yes","No";
BA_DEF_ SG_  "NetworkRequestHoldingTime" INT 0 65535;
BA_DEF_ SG_  "Description" STRING ;
BA_DEF_ SG_  "Version" STRING ;
BA_DEF_ SG_  "GenSigEnvVarType" ENUM  "Int","Float","Undef";
BA_DEF_ SG_  "GenSigSendType" ENUM  "Cyclic","OnWrite","OnWriteWithRepetition","OnChange","OnChangeWithRepetition","IfActive","IfActiveWithRepetition","NoSigSendType","OnChangeAndIfActive","OnChangeAndIfActiveWithRepetition";
BA_DEF_ SG_  "GwSigLatencyTime" INT 0 65536;
BA_DEF_ SG_  "GwSigMissingSourceType" ENUM  "Undef","OldValue","DefaultValue","InitialValue";
BA_DEF_ SG_  "NWM-WakeupAllowed" ENUM  "<n.a.>";
BA_DEF_ SG_  "RoutingFactor" INT 1 1215752192;
BA_DEF_ SG_  "SystemSignalLongSymbol" STRING ;
BA_DEF_REL_ BU_SG_REL_  "GenSigTimeoutTime" INT 0 7000;
BA_DEF_DEF_  "CANFD_BRS" "1";
BA_DEF_DEF_  "GenMsgEVName" "@Signame";
BA_DEF_DEF_  "NmAsrMessage" "No";
BA_DEF_DEF_  "DiagState" "No";
BA_DEF_DEF_  "DiagResponse" "No";
BA_DEF_DEF_  "DiagRequest" "No";
BA_DEF_DEF_  "TpMessage" "No";
BA_DEF_DEF_  "UsrMsgIDSforwardDeviation" 10;
BA_DEF_DEF_  "UsrMsgIDSbackwardDeviation" 100;
BA_DEF_DEF_  "GenMsgCycleTime" 200;
BA_DEF_DEF_  "GenMsgStartDelayTime" 0;
BA_DEF_DEF_  "GenMsgSendType" "NoMsgSendType";
BA_DEF_DEF_  "GenMsgCycleTimeFast" 40;
BA_DEF_DEF_  "GenMsgDelayTime" 20;
BA_DEF_DEF_  "GenMsgILSupport" "Yes";
BA_DEF_DEF_  "GenMsgNrOfRepetition" 3;
BA_DEF_DEF_  "TpTxIndex" 0;
BA_DEF_DEF_  "VFrameFormat" "StandardCAN";
BA_DEF_DEF_  "UserSigValidity" "IG";
BA_DEF_DEF_  "TimeoutValue" "";
BA_DEF_DEF_  "UsrSigPurpose" "FN";
BA_DEF_DEF_  "GenSigStartValue" 0;
BA_DEF_DEF_  "NetworkRequest" "No";
BA_DEF_DEF_  "NetworkRequestHoldingTime" 0;
BA_DEF_DEF_  "Description" "";
BA_DEF_DEF_  "Version" "";
BA_DEF_DEF_  "GenSigEnvVarType" "Undef";
BA_DEF_DEF_  "GenSigSendType" "NoSigSendType";
BA_DEF_DEF_  "GwSigLatencyTime" 40;
BA_DEF_DEF_  "GwSigMissingSourceType" "Undef";
BA_DEF_DEF_  "NWM-WakeupAllowed" "<n.a.>";
BA_DEF_DEF_  "RoutingFactor" 1;
BA_DEF_DEF_REL_ "GenSigTimeoutTime" 500;
BA_DEF_DEF_  "SystemSignalLongSymbol" "";
BA_ "GenMsgSendType" BO_ 829 0;
BA_ "VFrameFormat" BO_ 829 14;
BA_ "GenMsgSendType" BO_ 1025 0;
BA_ "GenMsgStartDelayTime" BO_ 1025 30;
BA_ "VFrameFormat" BO_ 1025 14;
BA_ "GenMsgSendType" BO_ 830 0;
BA_ "VFrameFormat" BO_ 830 14;
BA_ "GenMsgCycleTime" BO_ 1837 0;
BA_ "GenMsgCycleTimeFast" BO_ 1837 0;
BA_ "GenMsgNrOfRepetition" BO_ 1837 0;
BA_ "DiagResponse" BO_ 1837 1;
BA_ "GenMsgILSupport" BO_ 1837 0;
BA_ "TpMessage" BO_ 1837 1;
BA_ "TpTxIndex" BO_ 1837 180;
BA_ "VFrameFormat" BO_ 1837 14;
BA_ "GenMsgSendType" BO_ 256 0;
BA_ "GenMsgCycleTime" BO_ 256 50;
BA_ "GenMsgCycleTimeFast" BO_ 256 0;
BA_ "GenMsgNrOfRepetition" BO_ 256 0;
BA_ "VFrameFormat" BO_ 256 14;
BA_ "GenMsgCycleTime" BO_ 1233 0;
BA_ "VFrameFormat" BO_ 1233 14;
BA_ "GenMsgSendType" BO_ 870 0;
BA_ "GenMsgStartDelayTime" BO_ 870 50;
BA_ "VFrameFormat" BO_ 870 14;
BA_ "GenMsgSendType" BO_ 261 0;
BA_ "GenMsgCycleTime" BO_ 261 50;
BA_ "GenMsgCycleTimeFast" BO_ 261 0;
BA_ "GenMsgNrOfRepetition" BO_ 261 0;
BA_ "VFrameFormat" BO_ 261 14;
BA_ "GenMsgCycleTime" BO_ 1829 0;
BA_ "GenMsgCycleTimeFast" BO_ 1829 0;
BA_ "GenMsgNrOfRepetition" BO_ 1829 0;
BA_ "DiagRequest" BO_ 1829 1;
BA_ "GenMsgILSupport" BO_ 1829 0;
BA_ "TpMessage" BO_ 1829 1;
BA_ "TpTxIndex" BO_ 1829 180;
BA_ "VFrameFormat" BO_ 1829 14;
BA_ "Description" SG_ 829 SBCM_RR_FD_Crc1Val "The data area for CRC calculation is based on the data length (DLC) of the message DB.

The CRC shall be calculated over the entire data block (excluding the CRC bytes) including the user data, alive counter and Data ID



- CRC Polynomial (0x1021) , Ini";
BA_ "GenSigSendType" SG_ 829 SBCM_RR_FD_Crc1Val 4;
BA_ "GenSigStartValue" SG_ 829 SBCM_RR_FD_Crc1Val 65535;
BA_ "UserSigValidity" SG_ 829 SBCM_RR_FD_Crc1Val 3;
BA_ "Version" SG_ 829 SBCM_RR_FD_Crc1Val "22.10.20";
BA_ "GenSigSendType" SG_ 829 USM_RRGhostDoorSta 4;
BA_ "UserSigValidity" SG_ 829 USM_RRGhostDoorSta 0;
BA_ "NetworkRequest" SG_ 829 USM_RRGhostDoorSta 0;
BA_ "NetworkRequestHoldingTime" SG_ 829 USM_RRGhostDoorSta 5000;
BA_ "Version" SG_ 829 USM_RRGhostDoorSta "21.07.07";
BA_ "GenSigSendType" SG_ 829 DoorLock_PDSLkSwSta_RR 4;
BA_ "UserSigValidity" SG_ 829 DoorLock_PDSLkSwSta_RR 0;
BA_ "NetworkRequest" SG_ 829 DoorLock_PDSLkSwSta_RR 0;
BA_ "Version" SG_ 829 DoorLock_PDSLkSwSta_RR "21.09.05";
BA_ "GenSigSendType" SG_ 829 PDS_TypeOption_RR 4;
BA_ "UserSigValidity" SG_ 829 PDS_TypeOption_RR 0;
BA_ "NetworkRequest" SG_ 829 PDS_TypeOption_RR 0;
BA_ "Version" SG_ 829 PDS_TypeOption_RR "21.07.07";
BA_ "GenSigSendType" SG_ 829 RR_CrashMRActAlarm 4;
BA_ "UserSigValidity" SG_ 829 RR_CrashMRActAlarm 0;
BA_ "NetworkRequest" SG_ 829 RR_CrashMRActAlarm 0;
BA_ "NetworkRequestHoldingTime" SG_ 829 RR_CrashMRActAlarm 5000;
BA_ "Version" SG_ 829 RR_CrashMRActAlarm "21.07.07";
BA_ "GenSigSendType" SG_ 829 PwrDRBuzzerOut_RR 4;
BA_ "UserSigValidity" SG_ 829 PwrDRBuzzerOut_RR 0;
BA_ "NetworkRequest" SG_ 829 PwrDRBuzzerOut_RR 0;
BA_ "NetworkRequestHoldingTime" SG_ 829 PwrDRBuzzerOut_RR 5000;
BA_ "Version" SG_ 829 PwrDRBuzzerOut_RR "21.07.07";
BA_ "GenSigSendType" SG_ 829 PwrDRClosingRRDrSta 4;
BA_ "UserSigValidity" SG_ 829 PwrDRClosingRRDrSta 0;
BA_ "NetworkRequest" SG_ 829 PwrDRClosingRRDrSta 0;
BA_ "NetworkRequestHoldingTime" SG_ 829 PwrDRClosingRRDrSta 5000;
BA_ "Version" SG_ 829 PwrDRClosingRRDrSta "23.07.06";
BA_ "GenSigSendType" SG_ 829 AFH_RR_FldUnfldSta 4;
BA_ "UserSigValidity" SG_ 829 AFH_RR_FldUnfldSta 0;
BA_ "NetworkRequest" SG_ 829 AFH_RR_FldUnfldSta 0;
BA_ "NetworkRequestHoldingTime" SG_ 829 AFH_RR_FldUnfldSta 5000;
BA_ "Version" SG_ 829 AFH_RR_FldUnfldSta "24.07.06";
BA_ "Description" SG_ 829 SBCM_RR_FD_AlvCnt1Val "For the first transmission request for a data element the counter shall be initialized with 0 and shall be incremented by 1 for every subsequent send request. 

When the counter reaches the maximum value(0xFF), then it shall restart with 0 for the next s";
BA_ "GenSigSendType" SG_ 829 SBCM_RR_FD_AlvCnt1Val 4;
BA_ "UserSigValidity" SG_ 829 SBCM_RR_FD_AlvCnt1Val 3;
BA_ "Version" SG_ 829 SBCM_RR_FD_AlvCnt1Val "22.10.20";
BA_ "Description" SG_ 829 DoorLock_RrRtLkOutSta_SBCM "- Door Lock or Unlock Output State 

0x0 : Off (Door lock/unlock output Off state)

0x1 : On (Door lock/unlock output On state)";
BA_ "GenSigSendType" SG_ 829 DoorLock_RrRtLkOutSta_SBCM 4;
BA_ "UserSigValidity" SG_ 829 DoorLock_RrRtLkOutSta_SBCM 0;
BA_ "NetworkRequest" SG_ 829 DoorLock_RrRtLkOutSta_SBCM 0;
BA_ "NetworkRequestHoldingTime" SG_ 829 DoorLock_RrRtLkOutSta_SBCM 5000;
BA_ "Version" SG_ 829 DoorLock_RrRtLkOutSta_SBCM "23.02.09";
BA_ "GenSigSendType" SG_ 829 RrRt_DrLkRetryFail_SBCM 4;
BA_ "TimeoutValue" SG_ 829 RrRt_DrLkRetryFail_SBCM "0x0";
BA_ "UserSigValidity" SG_ 829 RrRt_DrLkRetryFail_SBCM 0;
BA_ "NetworkRequest" SG_ 829 RrRt_DrLkRetryFail_SBCM 0;
BA_ "NetworkRequestHoldingTime" SG_ 829 RrRt_DrLkRetryFail_SBCM 5000;
BA_ "Version" SG_ 829 RrRt_DrLkRetryFail_SBCM "23.03.00";
BA_ "GenSigSendType" SG_ 829 RR_DetectObj_warn 4;
BA_ "UserSigValidity" SG_ 829 RR_DetectObj_warn 0;
BA_ "NetworkRequest" SG_ 829 RR_DetectObj_warn 0;
BA_ "NetworkRequestHoldingTime" SG_ 829 RR_DetectObj_warn 5000;
BA_ "Version" SG_ 829 RR_DetectObj_warn "23.10.11";
BA_ "GenSigSendType" SG_ 829 RRRrDrCurtainPosition 4;
BA_ "UserSigValidity" SG_ 829 RRRrDrCurtainPosition 0;
BA_ "NetworkRequest" SG_ 829 RRRrDrCurtainPosition 0;
BA_ "NetworkRequestHoldingTime" SG_ 829 RRRrDrCurtainPosition 5000;
BA_ "Version" SG_ 829 RRRrDrCurtainPosition "23.08.00";
BA_ "GenSigSendType" SG_ 829 RRRrDrCurtainDownInitState 4;
BA_ "UserSigValidity" SG_ 829 RRRrDrCurtainDownInitState 0;
BA_ "NetworkRequest" SG_ 829 RRRrDrCurtainDownInitState 0;
BA_ "NetworkRequestHoldingTime" SG_ 829 RRRrDrCurtainDownInitState 5000;
BA_ "Version" SG_ 829 RRRrDrCurtainDownInitState "24.01.05";
BA_ "GenSigSendType" SG_ 829 PwrDrSta_RrRt 4;
BA_ "UserSigValidity" SG_ 829 PwrDrSta_RrRt 0;
BA_ "NetworkRequest" SG_ 829 PwrDrSta_RrRt 0;
BA_ "NetworkRequestHoldingTime" SG_ 829 PwrDrSta_RrRt 5000;
BA_ "Version" SG_ 829 PwrDrSta_RrRt "24.01.05";
BA_ "GenSigSendType" SG_ 829 PwrDRBuzzerOut_RR_New 4;
BA_ "UserSigValidity" SG_ 829 PwrDRBuzzerOut_RR_New 0;
BA_ "NetworkRequest" SG_ 829 PwrDRBuzzerOut_RR_New 0;
BA_ "NetworkRequestHoldingTime" SG_ 829 PwrDRBuzzerOut_RR_New 5000;
BA_ "Version" SG_ 829 PwrDRBuzzerOut_RR_New "24.01.05";
BA_ "Description" SG_ 829 SBCM_RR_SlidePosition "DHMC_RR_SlidePosition";
BA_ "GenSigSendType" SG_ 829 SBCM_RR_SlidePosition 4;
BA_ "GenSigStartValue" SG_ 829 SBCM_RR_SlidePosition 255;
BA_ "UserSigValidity" SG_ 829 SBCM_RR_SlidePosition 0;
BA_ "NetworkRequest" SG_ 829 SBCM_RR_SlidePosition 0;
BA_ "NetworkRequestHoldingTime" SG_ 829 SBCM_RR_SlidePosition 5000;
BA_ "Version" SG_ 829 SBCM_RR_SlidePosition "24.01.05";
BA_ "Description" SG_ 829 SBCM_RR_DoorAngle "PDSM_RR_DoorAngle";
BA_ "GenSigSendType" SG_ 829 SBCM_RR_DoorAngle 4;
BA_ "GenSigStartValue" SG_ 829 SBCM_RR_DoorAngle 100;
BA_ "UserSigValidity" SG_ 829 SBCM_RR_DoorAngle 0;
BA_ "NetworkRequest" SG_ 829 SBCM_RR_DoorAngle 0;
BA_ "NetworkRequestHoldingTime" SG_ 829 SBCM_RR_DoorAngle 5000;
BA_ "Version" SG_ 829 SBCM_RR_DoorAngle "24.01.05";
BA_ "GenSigSendType" SG_ 829 RRDoorPushAlarm 4;
BA_ "UserSigValidity" SG_ 829 RRDoorPushAlarm 0;
BA_ "NetworkRequest" SG_ 829 RRDoorPushAlarm 0;
BA_ "NetworkRequestHoldingTime" SG_ 829 RRDoorPushAlarm 5000;
BA_ "Version" SG_ 829 RRDoorPushAlarm "21.07.07";
BA_ "Description" SG_ 829 RR_CrashUnlockCmd "RearRightCrashUnlockCommand";
BA_ "GenSigSendType" SG_ 829 RR_CrashUnlockCmd 4;
BA_ "UserSigValidity" SG_ 829 RR_CrashUnlockCmd 0;
BA_ "NetworkRequest" SG_ 829 RR_CrashUnlockCmd 0;
BA_ "Version" SG_ 829 RR_CrashUnlockCmd "21.07.07";
BA_ "Description" SG_ 829 Warn_RrRtDrSwSta_SBCM "Warning Rear Right Door Switch Status";
BA_ "GenSigSendType" SG_ 829 Warn_RrRtDrSwSta_SBCM 4;
BA_ "UserSigValidity" SG_ 829 Warn_RrRtDrSwSta_SBCM 0;
BA_ "NetworkRequest" SG_ 829 Warn_RrRtDrSwSta_SBCM 0;
BA_ "Version" SG_ 829 Warn_RrRtDrSwSta_SBCM "21.09.05";
BA_ "Description" SG_ 829 DoorLock_RrRtDrUnLkSta_SBCM "Rear Right Door Unlock Status";
BA_ "GenSigSendType" SG_ 829 DoorLock_RrRtDrUnLkSta_SBCM 4;
BA_ "UserSigValidity" SG_ 829 DoorLock_RrRtDrUnLkSta_SBCM 0;
BA_ "NetworkRequest" SG_ 829 DoorLock_RrRtDrUnLkSta_SBCM 0;
BA_ "Version" SG_ 829 DoorLock_RrRtDrUnLkSta_SBCM "21.07.07";
BA_ "Description" SG_ 829 RR_SEAActivated "RearRightSEAActivated";
BA_ "GenSigSendType" SG_ 829 RR_SEAActivated 4;
BA_ "UserSigValidity" SG_ 829 RR_SEAActivated 0;
BA_ "NetworkRequest" SG_ 829 RR_SEAActivated 0;
BA_ "Version" SG_ 829 RR_SEAActivated "21.07.07";
BA_ "Description" SG_ 829 RR_SEAWarn "RearRighrSEAWarning";
BA_ "GenSigSendType" SG_ 829 RR_SEAWarn 4;
BA_ "UserSigValidity" SG_ 829 RR_SEAWarn 0;
BA_ "NetworkRequest" SG_ 829 RR_SEAWarn 0;
BA_ "Version" SG_ 829 RR_SEAWarn "21.07.07";
BA_ "GenSigSendType" SG_ 829 RR_SEWWarn 4;
BA_ "UserSigValidity" SG_ 829 RR_SEWWarn 0;
BA_ "NetworkRequest" SG_ 829 RR_SEWWarn 0;
BA_ "Version" SG_ 829 RR_SEWWarn "21.07.07";
BA_ "GenSigSendType" SG_ 829 RR_ReleaseWarn 4;
BA_ "UserSigValidity" SG_ 829 RR_ReleaseWarn 0;
BA_ "NetworkRequest" SG_ 829 RR_ReleaseWarn 0;
BA_ "NetworkRequestHoldingTime" SG_ 829 RR_ReleaseWarn 5000;
BA_ "Version" SG_ 829 RR_ReleaseWarn "21.09.05";
BA_ "GenSigSendType" SG_ 829 RR_SWFailAlarm 4;
BA_ "UserSigValidity" SG_ 829 RR_SWFailAlarm 0;
BA_ "NetworkRequest" SG_ 829 RR_SWFailAlarm 0;
BA_ "NetworkRequestHoldingTime" SG_ 829 RR_SWFailAlarm 5000;
BA_ "Version" SG_ 829 RR_SWFailAlarm "21.07.07";
BA_ "GenSigSendType" SG_ 829 RR_ChildLock_ActnFlSta 4;
BA_ "UserSigValidity" SG_ 829 RR_ChildLock_ActnFlSta 0;
BA_ "NetworkRequest" SG_ 829 RR_ChildLock_ActnFlSta 0;
BA_ "NetworkRequestHoldingTime" SG_ 829 RR_ChildLock_ActnFlSta 5000;
BA_ "Version" SG_ 829 RR_ChildLock_ActnFlSta "21.07.07";
BA_ "GenSigSendType" SG_ 829 RR_MRActivationAlarm 4;
BA_ "UserSigValidity" SG_ 829 RR_MRActivationAlarm 0;
BA_ "NetworkRequest" SG_ 829 RR_MRActivationAlarm 0;
BA_ "NetworkRequestHoldingTime" SG_ 829 RR_MRActivationAlarm 5000;
BA_ "Version" SG_ 829 RR_MRActivationAlarm "21.07.07";
BA_ "GenSigSendType" SG_ 829 RR_ChildLock_Status 4;
BA_ "UserSigValidity" SG_ 829 RR_ChildLock_Status 0;
BA_ "NetworkRequest" SG_ 829 RR_ChildLock_Status 0;
BA_ "NetworkRequestHoldingTime" SG_ 829 RR_ChildLock_Status 5000;
BA_ "Version" SG_ 829 RR_ChildLock_Status "21.07.07";
BA_ "Description" SG_ 1025 BDC_FD_SMK_Crc2Val "The data area for CRC calculation is based on the data length (DLC) of the message DB.

The CRC shall be calculated over the entire data block (excluding the CRC bytes) including the user data, alive counter and Data ID



- CRC Polynomial (0x1021) , Ini";
BA_ "GenSigSendType" SG_ 1025 BDC_FD_SMK_Crc2Val 4;
BA_ "GenSigStartValue" SG_ 1025 BDC_FD_SMK_Crc2Val 65535;
BA_ "UserSigValidity" SG_ 1025 BDC_FD_SMK_Crc2Val 0;
BA_ "Version" SG_ 1025 BDC_FD_SMK_Crc2Val "22.11.04";
BA_ "GenSigSendType" SG_ 1025 SMK_RpmLoByteVal 4;
BA_ "UserSigValidity" SG_ 1025 SMK_RpmLoByteVal 0;
BA_ "Version" SG_ 1025 SMK_RpmLoByteVal "21.07.05";
BA_ "GenSigSendType" SG_ 1025 SMK_VehSpdDrctVal 4;
BA_ "UserSigValidity" SG_ 1025 SMK_VehSpdDrctVal 0;
BA_ "Version" SG_ 1025 SMK_VehSpdDrctVal "21.07.05";
BA_ "Description" SG_ 1025 Fob_BattStaInfo "Received Fob Battery Status for Telematics Vehicle Information Service";
BA_ "GenSigSendType" SG_ 1025 Fob_BattStaInfo 4;
BA_ "UserSigValidity" SG_ 1025 Fob_BattStaInfo 0;
BA_ "Version" SG_ 1025 Fob_BattStaInfo "17.12.00";
BA_ "Description" SG_ 1025 Fob_FoundDrvWlcmArea "This Signal Indicates direction of user approach to vehicle.

If User Approach to vehicle Driver direction, This signal set On.";
BA_ "GenSigSendType" SG_ 1025 Fob_FoundDrvWlcmArea 4;
BA_ "UserSigValidity" SG_ 1025 Fob_FoundDrvWlcmArea 0;
BA_ "Version" SG_ 1025 Fob_FoundDrvWlcmArea "17.12.00";
BA_ "Description" SG_ 1025 Fob_FoundAsstWlcmArea "This Signal Indicates direction of user approach to vehicle.

If User Approach to vehicle Assistant direction, This signal set On.";
BA_ "GenSigSendType" SG_ 1025 Fob_FoundAsstWlcmArea 4;
BA_ "UserSigValidity" SG_ 1025 Fob_FoundAsstWlcmArea 0;
BA_ "Version" SG_ 1025 Fob_FoundAsstWlcmArea "17.12.00";
BA_ "Description" SG_ 1025 Fob_FoundExtrnlArea "Exterior FOB Position recognize";
BA_ "GenSigSendType" SG_ 1025 Fob_FoundExtrnlArea 4;
BA_ "UserSigValidity" SG_ 1025 Fob_FoundExtrnlArea 0;
BA_ "Version" SG_ 1025 Fob_FoundExtrnlArea "17.12.00";
BA_ "Description" SG_ 1025 Fob_FoundIntArea "Interior FOB Position recognize";
BA_ "GenSigSendType" SG_ 1025 Fob_FoundIntArea 4;
BA_ "UserSigValidity" SG_ 1025 Fob_FoundIntArea 0;
BA_ "Version" SG_ 1025 Fob_FoundIntArea "17.12.00";
BA_ "Description" SG_ 1025 Fob_LearntSta "Fob key registration status information";
BA_ "GenSigSendType" SG_ 1025 Fob_LearntSta 4;
BA_ "GenSigStartValue" SG_ 1025 Fob_LearntSta 1;
BA_ "UserSigValidity" SG_ 1025 Fob_LearntSta 0;
BA_ "NetworkRequest" SG_ 1025 Fob_LearntSta 0;
BA_ "NetworkRequestHoldingTime" SG_ 1025 Fob_LearntSta 5000;
BA_ "Version" SG_ 1025 Fob_LearntSta "17.12.00";
BA_ "Description" SG_ 1025 RSPA_LearntSta "IBU RSPA learnt state signal.

This signal is used only for ADAS_PRK.";
BA_ "GenSigSendType" SG_ 1025 RSPA_LearntSta 4;
BA_ "UserSigValidity" SG_ 1025 RSPA_LearntSta 0;
BA_ "Version" SG_ 1025 RSPA_LearntSta "19.07.01";
BA_ "Description" SG_ 1025 RSPA_RFSigErrSta "Error status of RKE_BtnReq signal.



If RF frame data from FOB defferent with CAN signal data(RKE_BtnReq), 

RSPA_RFSigErrSta signal send 0x1 Signal Invalid.";
BA_ "GenSigSendType" SG_ 1025 RSPA_RFSigErrSta 4;
BA_ "UserSigValidity" SG_ 1025 RSPA_RFSigErrSta 0;
BA_ "NetworkRequest" SG_ 1025 RSPA_RFSigErrSta 0;
BA_ "NetworkRequestHoldingTime" SG_ 1025 RSPA_RFSigErrSta 5000;
BA_ "Version" SG_ 1025 RSPA_RFSigErrSta "18.05.02";
BA_ "Description" SG_ 1025 RSPA_CanErrSta "Error status of RSPA control signals.(From ADAS_PRK)";
BA_ "GenSigSendType" SG_ 1025 RSPA_CanErrSta 4;
BA_ "UserSigValidity" SG_ 1025 RSPA_CanErrSta 0;
BA_ "Version" SG_ 1025 RSPA_CanErrSta "18.05.02";
BA_ "Description" SG_ 1025 RSPA_ModSta_SMK "State of RSPA system operate";
BA_ "GenSigSendType" SG_ 1025 RSPA_ModSta_SMK 4;
BA_ "UserSigValidity" SG_ 1025 RSPA_ModSta_SMK 0;
BA_ "Version" SG_ 1025 RSPA_ModSta_SMK "19.03.08";
BA_ "Description" SG_ 1025 RSPA_FobBattSta "FOB Battery's Low Battery(discharge) state.

Low Battery condition is same with 'C_KeyBATDischargeWarn' Signal";
BA_ "GenSigSendType" SG_ 1025 RSPA_FobBattSta 4;
BA_ "UserSigValidity" SG_ 1025 RSPA_FobBattSta 0;
BA_ "Version" SG_ 1025 RSPA_FobBattSta "17.12.00";
BA_ "Description" SG_ 1025 Fob_BtnReleasedSta "this signal indicate fob butten released state during RSPA mode. 

##2G##IBU##SMK18##C_FobButtenReleased";
BA_ "GenSigSendType" SG_ 1025 Fob_BtnReleasedSta 4;
BA_ "UserSigValidity" SG_ 1025 Fob_BtnReleasedSta 0;
BA_ "Version" SG_ 1025 Fob_BtnReleasedSta "18.10.09";
BA_ "Description" SG_ 1025 Fob_FoundWlcmArea "This signal indicates that there is Fob around the welcome area. 

 -to inform the door handle (Lock/Unlock touch sensor)";
BA_ "GenSigSendType" SG_ 1025 Fob_FoundWlcmArea 4;
BA_ "UserSigValidity" SG_ 1025 Fob_FoundWlcmArea 0;
BA_ "Version" SG_ 1025 Fob_FoundWlcmArea "19.03.09";
BA_ "Description" SG_ 1025 USM_WALModSta "Current USM Setting value of Walk Away Lock(WAL) mode";
BA_ "GenSigSendType" SG_ 1025 USM_WALModSta 4;
BA_ "UserSigValidity" SG_ 1025 USM_WALModSta 0;
BA_ "Version" SG_ 1025 USM_WALModSta "17.12.00";
BA_ "GenSigSendType" SG_ 1025 USM_SmrtTrnkTlgtModSta 4;
BA_ "UserSigValidity" SG_ 1025 USM_SmrtTrnkTlgtModSta 0;
BA_ "Version" SG_ 1025 USM_SmrtTrnkTlgtModSta "18.05.01";
BA_ "GenSigSendType" SG_ 1025 USM_SAUModSta 4;
BA_ "UserSigValidity" SG_ 1025 USM_SAUModSta 0;
BA_ "NetworkRequest" SG_ 1025 USM_SAUModSta 0;
BA_ "NetworkRequestHoldingTime" SG_ 1025 USM_SAUModSta 5000;
BA_ "Version" SG_ 1025 USM_SAUModSta "22.11.07";
BA_ "Description" SG_ 1025 SMK_RLHndLkSnsrSta "Development for SMK

Rear Left Door Handle Lock Touch Sensor Signal";
BA_ "GenSigSendType" SG_ 1025 SMK_RLHndLkSnsrSta 4;
BA_ "UserSigValidity" SG_ 1025 SMK_RLHndLkSnsrSta 0;
BA_ "Version" SG_ 1025 SMK_RLHndLkSnsrSta "23.07.00";
BA_ "Description" SG_ 1025 BDC_FD_SMK_AlvCnt2Val "For the first transmission request for a data element the counter shall be initialized with 0 and shall be incremented by 1 for every subsequent send request. 

When the counter reaches the maximum value(0xFF), then it shall restart with 0 for the next s";
BA_ "GenSigSendType" SG_ 1025 BDC_FD_SMK_AlvCnt2Val 4;
BA_ "UserSigValidity" SG_ 1025 BDC_FD_SMK_AlvCnt2Val 0;
BA_ "Version" SG_ 1025 BDC_FD_SMK_AlvCnt2Val "22.11.04";
BA_ "Description" SG_ 1025 SMK_RLDrHndUnLkSnsrSta "Development for SMK

Rear Left  Door Handle Unlock Touch Sensor Signal";
BA_ "GenSigSendType" SG_ 1025 SMK_RLDrHndUnLkSnsrSta 4;
BA_ "UserSigValidity" SG_ 1025 SMK_RLDrHndUnLkSnsrSta 0;
BA_ "Version" SG_ 1025 SMK_RLDrHndUnLkSnsrSta "23.07.00";
BA_ "Description" SG_ 1025 SMK_RRDrHndLkSnsrSta "Development for SMK

Rear Right Door Handle Lock Touch Sensor Signal";
BA_ "GenSigSendType" SG_ 1025 SMK_RRDrHndLkSnsrSta 4;
BA_ "UserSigValidity" SG_ 1025 SMK_RRDrHndLkSnsrSta 0;
BA_ "Version" SG_ 1025 SMK_RRDrHndLkSnsrSta "23.07.00";
BA_ "Description" SG_ 1025 SMK_RRDrHndUnLkSnsrSta "Development for SMK

Rear Right Door Handle Unlock Touch Sensor Signal";
BA_ "GenSigSendType" SG_ 1025 SMK_RRDrHndUnLkSnsrSta 4;
BA_ "UserSigValidity" SG_ 1025 SMK_RRDrHndUnLkSnsrSta 0;
BA_ "Version" SG_ 1025 SMK_RRDrHndUnLkSnsrSta "23.07.00";
BA_ "Description" SG_ 1025 Fob_FoundCabinArea "Fob searching result in cabin area for SWA function

*SWA : Smart Walk Away Lock";
BA_ "GenSigSendType" SG_ 1025 Fob_FoundCabinArea 4;
BA_ "UserSigValidity" SG_ 1025 Fob_FoundCabinArea 0;
BA_ "Version" SG_ 1025 Fob_FoundCabinArea "23.09.04";
BA_ "Description" SG_ 1025 SMK_ResultRmtStrt "1) Control Raw Data OK + Valid code OK

     → Run Tele Engine Running, and If it success, then send 0x1

2) Control Raw Data OK + Valid code NG

     → Don't run Tele Engine Running, and it Fail, then send 0x2

3) Control Raw Data NG + Valid code OK

";
BA_ "GenSigSendType" SG_ 1025 SMK_ResultRmtStrt 4;
BA_ "UserSigValidity" SG_ 1025 SMK_ResultRmtStrt 0;
BA_ "Version" SG_ 1025 SMK_ResultRmtStrt "24.07.06";
BA_ "Description" SG_ 1025 SMK_EncryptTeleOptSta "If applied Remote Start Encryption, then send 0x1";
BA_ "GenSigSendType" SG_ 1025 SMK_EncryptTeleOptSta 4;
BA_ "UserSigValidity" SG_ 1025 SMK_EncryptTeleOptSta 0;
BA_ "Version" SG_ 1025 SMK_EncryptTeleOptSta "24.04.01";
BA_ "GenSigSendType" SG_ 1025 Auth_ISKLearnSta2 4;
BA_ "UserSigValidity" SG_ 1025 Auth_ISKLearnSta2 0;
BA_ "Version" SG_ 1025 Auth_ISKLearnSta2 "24.04.03";
BA_ "Description" SG_ 1025 Auth_ISKLearnSta "This signal is State of IAU Learning";
BA_ "GenSigSendType" SG_ 1025 Auth_ISKLearnSta 4;
BA_ "UserSigValidity" SG_ 1025 Auth_ISKLearnSta 0;
BA_ "Version" SG_ 1025 Auth_ISKLearnSta "19.02.07";
BA_ "GenSigSendType" SG_ 1025 SMK_TlPwrOnSta 4;
BA_ "UserSigValidity" SG_ 1025 SMK_TlPwrOnSta 0;
BA_ "Version" SG_ 1025 SMK_TlPwrOnSta "24.04.03";
BA_ "Description" SG_ 1025 Fob_FoundForChargingDoor "Fob searching result for charging door open";
BA_ "GenSigSendType" SG_ 1025 Fob_FoundForChargingDoor 4;
BA_ "UserSigValidity" SG_ 1025 Fob_FoundForChargingDoor 0;
BA_ "Version" SG_ 1025 Fob_FoundForChargingDoor "24.04.10";
BA_ "Description" SG_ 1025 SSB_StrtStpBtnSw1Sta "StartStop button switch #1 status";
BA_ "GenSigSendType" SG_ 1025 SSB_StrtStpBtnSw1Sta 4;
BA_ "UserSigValidity" SG_ 1025 SSB_StrtStpBtnSw1Sta 0;
BA_ "Version" SG_ 1025 SSB_StrtStpBtnSw1Sta "17.12.00";
BA_ "Description" SG_ 1025 SSB_StrtStpBtnSw2Sta "StartStop button switch #2 status";
BA_ "GenSigSendType" SG_ 1025 SSB_StrtStpBtnSw2Sta 4;
BA_ "UserSigValidity" SG_ 1025 SSB_StrtStpBtnSw2Sta 0;
BA_ "Version" SG_ 1025 SSB_StrtStpBtnSw2Sta "17.12.00";
BA_ "GenSigSendType" SG_ 1025 SMK_AuthSta 4;
BA_ "UserSigValidity" SG_ 1025 SMK_AuthSta 0;
BA_ "Version" SG_ 1025 SMK_AuthSta "17.12.00";
BA_ "GenSigSendType" SG_ 1025 SMK_TlPwrOnOpt 4;
BA_ "UserSigValidity" SG_ 1025 SMK_TlPwrOnOpt 0;
BA_ "Version" SG_ 1025 SMK_TlPwrOnOpt "24.04.09";
BA_ "Description" SG_ 1025 SMK_Ign1InSta "Ignition1 Input Status at SMK";
BA_ "GenSigSendType" SG_ 1025 SMK_Ign1InSta 4;
BA_ "UserSigValidity" SG_ 1025 SMK_Ign1InSta 0;
BA_ "Version" SG_ 1025 SMK_Ign1InSta "17.12.00";
BA_ "Description" SG_ 1025 SMK_Ign1RlySta "Development for SMK";
BA_ "GenSigSendType" SG_ 1025 SMK_Ign1RlySta 4;
BA_ "UserSigValidity" SG_ 1025 SMK_Ign1RlySta 0;
BA_ "Version" SG_ 1025 SMK_Ign1RlySta "17.12.00";
BA_ "Description" SG_ 1025 SMK_Ign2InSta "Ignition2 Input Status at SMK";
BA_ "GenSigSendType" SG_ 1025 SMK_Ign2InSta 4;
BA_ "UserSigValidity" SG_ 1025 SMK_Ign2InSta 0;
BA_ "Version" SG_ 1025 SMK_Ign2InSta "17.12.00";
BA_ "Description" SG_ 1025 SMK_Ign2RlySta "Development for SMK";
BA_ "GenSigSendType" SG_ 1025 SMK_Ign2RlySta 4;
BA_ "UserSigValidity" SG_ 1025 SMK_Ign2RlySta 0;
BA_ "Version" SG_ 1025 SMK_Ign2RlySta "17.12.00";
BA_ "Description" SG_ 1025 SMK_StrtFdbckSta "Mirror value of L_StartFeedback";
BA_ "GenSigSendType" SG_ 1025 SMK_StrtFdbckSta 4;
BA_ "UserSigValidity" SG_ 1025 SMK_StrtFdbckSta 0;
BA_ "Version" SG_ 1025 SMK_StrtFdbckSta "17.12.00";
BA_ "Description" SG_ 1025 SMK_StrtrRlyOutSta "-(Old)C_StarterRelayStatus";
BA_ "GenSigSendType" SG_ 1025 SMK_StrtrRlyOutSta 4;
BA_ "UserSigValidity" SG_ 1025 SMK_StrtrRlyOutSta 0;
BA_ "Version" SG_ 1025 SMK_StrtrRlyOutSta "17.12.00";
BA_ "Description" SG_ 1025 SMK_AccInSta "ACC Input Status at SMK";
BA_ "GenSigSendType" SG_ 1025 SMK_AccInSta 4;
BA_ "UserSigValidity" SG_ 1025 SMK_AccInSta 0;
BA_ "Version" SG_ 1025 SMK_AccInSta "17.12.00";
BA_ "Description" SG_ 1025 SMK_AccRlySta "Development for SMK";
BA_ "GenSigSendType" SG_ 1025 SMK_AccRlySta 4;
BA_ "UserSigValidity" SG_ 1025 SMK_AccRlySta 0;
BA_ "Version" SG_ 1025 SMK_AccRlySta "17.12.00";
BA_ "Description" SG_ 1025 SMK_CLUAccIndOnReq "Request to Cluster ACC Indicator On

(This is only used for CLU)";
BA_ "GenSigSendType" SG_ 1025 SMK_CLUAccIndOnReq 4;
BA_ "UserSigValidity" SG_ 1025 SMK_CLUAccIndOnReq 0;
BA_ "Version" SG_ 1025 SMK_CLUAccIndOnReq "17.12.00";
BA_ "GenSigSendType" SG_ 1025 SMK_VDModeActSta 4;
BA_ "UserSigValidity" SG_ 1025 SMK_VDModeActSta 0;
BA_ "Version" SG_ 1025 SMK_VDModeActSta "20.07.05";
BA_ "Description" SG_ 1025 SMK_SCULckUnlckSta "SCU Lock/Unlock State";
BA_ "GenSigSendType" SG_ 1025 SMK_SCULckUnlckSta 4;
BA_ "UserSigValidity" SG_ 1025 SMK_SCULckUnlckSta 0;
BA_ "Version" SG_ 1025 SMK_SCULckUnlckSta "22.01.06";
BA_ "GenSigSendType" SG_ 1025 SMK_TlEngRunSta 4;
BA_ "UserSigValidity" SG_ 1025 SMK_TlEngRunSta 0;
BA_ "Version" SG_ 1025 SMK_TlEngRunSta "17.12.00";
BA_ "GenSigSendType" SG_ 1025 SMK_TlCrnkModSta 4;
BA_ "UserSigValidity" SG_ 1025 SMK_TlCrnkModSta 0;
BA_ "Version" SG_ 1025 SMK_TlCrnkModSta "17.12.00";
BA_ "GenSigSendType" SG_ 1025 SMK_RmtKeyEngRunSta 4;
BA_ "UserSigValidity" SG_ 1025 SMK_RmtKeyEngRunSta 0;
BA_ "Version" SG_ 1025 SMK_RmtKeyEngRunSta "17.11.00";
BA_ "GenSigSendType" SG_ 1025 SMK_RmtKeyCrnkModSta 4;
BA_ "UserSigValidity" SG_ 1025 SMK_RmtKeyCrnkModSta 0;
BA_ "Version" SG_ 1025 SMK_RmtKeyCrnkModSta "17.11.00";
BA_ "Description" SG_ 1025 SMK_AsstTgglBtnSta "Development for SMK";
BA_ "GenSigSendType" SG_ 1025 SMK_AsstTgglBtnSta 4;
BA_ "UserSigValidity" SG_ 1025 SMK_AsstTgglBtnSta 0;
BA_ "Version" SG_ 1025 SMK_AsstTgglBtnSta "17.12.00";
BA_ "Description" SG_ 1025 SMK_DrvTglBtnSta "Development for SMK";
BA_ "GenSigSendType" SG_ 1025 SMK_DrvTglBtnSta 4;
BA_ "UserSigValidity" SG_ 1025 SMK_DrvTglBtnSta 0;
BA_ "Version" SG_ 1025 SMK_DrvTglBtnSta "17.12.00";
BA_ "Description" SG_ 1025 SMK_RrLftTglBtnSta "Development for SMK";
BA_ "GenSigSendType" SG_ 1025 SMK_RrLftTglBtnSta 4;
BA_ "UserSigValidity" SG_ 1025 SMK_RrLftTglBtnSta 0;
BA_ "Version" SG_ 1025 SMK_RrLftTglBtnSta "17.12.00";
BA_ "Description" SG_ 1025 SMK_RrRtTglBtnSta "Development for SMK";
BA_ "GenSigSendType" SG_ 1025 SMK_RrRtTglBtnSta 4;
BA_ "UserSigValidity" SG_ 1025 SMK_RrRtTglBtnSta 0;
BA_ "Version" SG_ 1025 SMK_RrRtTglBtnSta "17.12.00";
BA_ "Description" SG_ 1025 SMK_TgglBtnStuckSta "This signal represents Toggle Button's Error condition.

If Toggle Button has Fault(ex, Stuck etc..). signal has fault value.";
BA_ "GenSigSendType" SG_ 1025 SMK_TgglBtnStuckSta 4;
BA_ "UserSigValidity" SG_ 1025 SMK_TgglBtnStuckSta 0;
BA_ "Version" SG_ 1025 SMK_TgglBtnStuckSta "17.12.00";
BA_ "Description" SG_ 1025 SMK_AsstDrHndUnLkSnsrSta "Development for SMK";
BA_ "GenSigSendType" SG_ 1025 SMK_AsstDrHndUnLkSnsrSta 4;
BA_ "UserSigValidity" SG_ 1025 SMK_AsstDrHndUnLkSnsrSta 0;
BA_ "Version" SG_ 1025 SMK_AsstDrHndUnLkSnsrSta "18.08.08";
BA_ "Description" SG_ 1025 SMK_BrkSwSta "SMK+ Brake SW input state";
BA_ "GenSigSendType" SG_ 1025 SMK_BrkSwSta 4;
BA_ "UserSigValidity" SG_ 1025 SMK_BrkSwSta 0;
BA_ "Version" SG_ 1025 SMK_BrkSwSta "17.12.00";
BA_ "Description" SG_ 1025 SMK_GearPosPSwSta "Clutch SW (M/T Only)

Shift lever P Postion";
BA_ "GenSigSendType" SG_ 1025 SMK_GearPosPSwSta 4;
BA_ "UserSigValidity" SG_ 1025 SMK_GearPosPSwSta 0;
BA_ "Version" SG_ 1025 SMK_GearPosPSwSta "21.09.05";
BA_ "Description" SG_ 1025 SMK_CltchIgnLkSwSta "This signal indicates that SMK has detected an operation of a Ignition Lock switch. EMS uses this signal for improving drivability of manual trasmission vehicle.







If the SMK does not support this signal the value is 00H



0x0 : SMK determines that";
BA_ "GenSigSendType" SG_ 1025 SMK_CltchIgnLkSwSta 4;
BA_ "UserSigValidity" SG_ 1025 SMK_CltchIgnLkSwSta 0;
BA_ "Version" SG_ 1025 SMK_CltchIgnLkSwSta "20.12.04";
BA_ "Description" SG_ 1025 SMK_DrvDrHndLkSnsrSta "Development for SMK";
BA_ "GenSigSendType" SG_ 1025 SMK_DrvDrHndLkSnsrSta 4;
BA_ "UserSigValidity" SG_ 1025 SMK_DrvDrHndLkSnsrSta 0;
BA_ "Version" SG_ 1025 SMK_DrvDrHndLkSnsrSta "18.08.07";
BA_ "Description" SG_ 1025 SMK_DrvDrHndUnLkSnsrSta "Development for SMK";
BA_ "GenSigSendType" SG_ 1025 SMK_DrvDrHndUnLkSnsrSta 4;
BA_ "UserSigValidity" SG_ 1025 SMK_DrvDrHndUnLkSnsrSta 0;
BA_ "Version" SG_ 1025 SMK_DrvDrHndUnLkSnsrSta "18.08.07";
BA_ "Description" SG_ 1025 SMK_AsstDrHndLkSnsrSta "Development for SMK";
BA_ "GenSigSendType" SG_ 1025 SMK_AsstDrHndLkSnsrSta 4;
BA_ "UserSigValidity" SG_ 1025 SMK_AsstDrHndLkSnsrSta 0;
BA_ "Version" SG_ 1025 SMK_AsstDrHndLkSnsrSta "18.08.07";
BA_ "Description" SG_ 1025 LFAnt_FltSta "This signal represents LF ANT's Error condition. 

If one of LF ANT has Fault(ex, timeout), signal has fault value.";
BA_ "GenSigSendType" SG_ 1025 LFAnt_FltSta 4;
BA_ "UserSigValidity" SG_ 1025 LFAnt_FltSta 0;
BA_ "Version" SG_ 1025 LFAnt_FltSta "17.12.00";
BA_ "Description" SG_ 1025 LFAnt_SrchSta "SMK LF Searching Status



This signal indicates that SMK operates LF searching for finding FOB.

WPC uses this signal for suspending wirless charging.";
BA_ "GenSigSendType" SG_ 1025 LFAnt_SrchSta 4;
BA_ "UserSigValidity" SG_ 1025 LFAnt_SrchSta 0;
BA_ "Version" SG_ 1025 LFAnt_SrchSta "17.12.00";
BA_ "Description" SG_ 1025 Lamp_HzrdBlnkngSta "Hazard Signal for Hands Free Trunk/Tailgate";
BA_ "GenSigSendType" SG_ 1025 Lamp_HzrdBlnkngSta 4;
BA_ "UserSigValidity" SG_ 1025 Lamp_HzrdBlnkngSta 0;
BA_ "Version" SG_ 1025 Lamp_HzrdBlnkngSta "17.12.00";
BA_ "Description" SG_ 1025 Lamp_SmrtWlcmLtOnReq "Smart Key welcome light on request.";
BA_ "GenSigSendType" SG_ 1025 Lamp_SmrtWlcmLtOnReq 4;
BA_ "UserSigValidity" SG_ 1025 Lamp_SmrtWlcmLtOnReq 0;
BA_ "NetworkRequest" SG_ 1025 Lamp_SmrtWlcmLtOnReq 0;
BA_ "NetworkRequestHoldingTime" SG_ 1025 Lamp_SmrtWlcmLtOnReq 5000;
BA_ "Version" SG_ 1025 Lamp_SmrtWlcmLtOnReq "17.12.00";
BA_ "GenSigSendType" SG_ 1025 SMK_RpmHiByteVal 4;
BA_ "UserSigValidity" SG_ 1025 SMK_RpmHiByteVal 0;
BA_ "Version" SG_ 1025 SMK_RpmHiByteVal "21.07.05";
BA_ "Description" SG_ 830 SBCM_RL_FD_Crc1Val "The data area for CRC calculation is based on the data length (DLC) of the message DB.

The CRC shall be calculated over the entire data block (excluding the CRC bytes) including the user data, alive counter and Data ID



- CRC Polynomial (0x1021) , Ini";
BA_ "GenSigSendType" SG_ 830 SBCM_RL_FD_Crc1Val 4;
BA_ "GenSigStartValue" SG_ 830 SBCM_RL_FD_Crc1Val 65535;
BA_ "UserSigValidity" SG_ 830 SBCM_RL_FD_Crc1Val 3;
BA_ "Version" SG_ 830 SBCM_RL_FD_Crc1Val "22.10.20";
BA_ "GenSigSendType" SG_ 830 USM_RLGhostDoorSta 4;
BA_ "UserSigValidity" SG_ 830 USM_RLGhostDoorSta 0;
BA_ "NetworkRequest" SG_ 830 USM_RLGhostDoorSta 0;
BA_ "NetworkRequestHoldingTime" SG_ 830 USM_RLGhostDoorSta 5000;
BA_ "Version" SG_ 830 USM_RLGhostDoorSta "21.07.07";
BA_ "GenSigSendType" SG_ 830 DoorLock_PDSLkSwSta_RL 4;
BA_ "UserSigValidity" SG_ 830 DoorLock_PDSLkSwSta_RL 0;
BA_ "NetworkRequest" SG_ 830 DoorLock_PDSLkSwSta_RL 0;
BA_ "Version" SG_ 830 DoorLock_PDSLkSwSta_RL "21.09.05";
BA_ "GenSigSendType" SG_ 830 PDS_TypeOption_RL 4;
BA_ "UserSigValidity" SG_ 830 PDS_TypeOption_RL 0;
BA_ "NetworkRequest" SG_ 830 PDS_TypeOption_RL 0;
BA_ "Version" SG_ 830 PDS_TypeOption_RL "21.07.07";
BA_ "GenSigSendType" SG_ 830 RL_CrashMRActAlarm 4;
BA_ "UserSigValidity" SG_ 830 RL_CrashMRActAlarm 0;
BA_ "NetworkRequest" SG_ 830 RL_CrashMRActAlarm 0;
BA_ "NetworkRequestHoldingTime" SG_ 830 RL_CrashMRActAlarm 5000;
BA_ "Version" SG_ 830 RL_CrashMRActAlarm "21.07.07";
BA_ "GenSigSendType" SG_ 830 PwrDRBuzzerOut_RL 4;
BA_ "UserSigValidity" SG_ 830 PwrDRBuzzerOut_RL 0;
BA_ "NetworkRequest" SG_ 830 PwrDRBuzzerOut_RL 0;
BA_ "NetworkRequestHoldingTime" SG_ 830 PwrDRBuzzerOut_RL 5000;
BA_ "Version" SG_ 830 PwrDRBuzzerOut_RL "21.07.07";
BA_ "GenSigSendType" SG_ 830 PwrDRClosingRLDrSta 4;
BA_ "UserSigValidity" SG_ 830 PwrDRClosingRLDrSta 0;
BA_ "NetworkRequest" SG_ 830 PwrDRClosingRLDrSta 0;
BA_ "NetworkRequestHoldingTime" SG_ 830 PwrDRClosingRLDrSta 5000;
BA_ "Version" SG_ 830 PwrDRClosingRLDrSta "23.07.06";
BA_ "GenSigSendType" SG_ 830 AFH_RL_FldUnfldSta 4;
BA_ "UserSigValidity" SG_ 830 AFH_RL_FldUnfldSta 0;
BA_ "NetworkRequest" SG_ 830 AFH_RL_FldUnfldSta 0;
BA_ "NetworkRequestHoldingTime" SG_ 830 AFH_RL_FldUnfldSta 5000;
BA_ "Version" SG_ 830 AFH_RL_FldUnfldSta "24.07.06";
BA_ "Description" SG_ 830 SBCM_RL_FD_AlvCnt1Val "For the first transmission request for a data element the counter shall be initialized with 0 and shall be incremented by 1 for every subsequent send request. 

When the counter reaches the maximum value(0xFF), then it shall restart with 0 for the next s";
BA_ "GenSigSendType" SG_ 830 SBCM_RL_FD_AlvCnt1Val 4;
BA_ "UserSigValidity" SG_ 830 SBCM_RL_FD_AlvCnt1Val 3;
BA_ "Version" SG_ 830 SBCM_RL_FD_AlvCnt1Val "22.10.20";
BA_ "Description" SG_ 830 DoorLock_RrLtLkOutSta_SBCM "- Door Lock or Unlock Output State 

0x0 : Off (Door lock/unlock output Off state)

0x1 : On (Door lock/unlock output On state)";
BA_ "GenSigSendType" SG_ 830 DoorLock_RrLtLkOutSta_SBCM 4;
BA_ "UserSigValidity" SG_ 830 DoorLock_RrLtLkOutSta_SBCM 0;
BA_ "NetworkRequest" SG_ 830 DoorLock_RrLtLkOutSta_SBCM 0;
BA_ "NetworkRequestHoldingTime" SG_ 830 DoorLock_RrLtLkOutSta_SBCM 5000;
BA_ "Version" SG_ 830 DoorLock_RrLtLkOutSta_SBCM "23.02.09";
BA_ "GenSigSendType" SG_ 830 RrLt_DrLkRetryFail_SBCM 4;
BA_ "TimeoutValue" SG_ 830 RrLt_DrLkRetryFail_SBCM "0x0";
BA_ "UserSigValidity" SG_ 830 RrLt_DrLkRetryFail_SBCM 0;
BA_ "NetworkRequest" SG_ 830 RrLt_DrLkRetryFail_SBCM 0;
BA_ "NetworkRequestHoldingTime" SG_ 830 RrLt_DrLkRetryFail_SBCM 5000;
BA_ "Version" SG_ 830 RrLt_DrLkRetryFail_SBCM "23.03.00";
BA_ "GenSigSendType" SG_ 830 RL_DetectObj_warn 4;
BA_ "UserSigValidity" SG_ 830 RL_DetectObj_warn 0;
BA_ "NetworkRequest" SG_ 830 RL_DetectObj_warn 0;
BA_ "NetworkRequestHoldingTime" SG_ 830 RL_DetectObj_warn 5000;
BA_ "Version" SG_ 830 RL_DetectObj_warn "23.10.11";
BA_ "GenSigSendType" SG_ 830 RLRrDrCurtainPosition 4;
BA_ "UserSigValidity" SG_ 830 RLRrDrCurtainPosition 0;
BA_ "NetworkRequest" SG_ 830 RLRrDrCurtainPosition 0;
BA_ "NetworkRequestHoldingTime" SG_ 830 RLRrDrCurtainPosition 5000;
BA_ "Version" SG_ 830 RLRrDrCurtainPosition "23.07.06";
BA_ "GenSigSendType" SG_ 830 RDC_TypeOption 4;
BA_ "UserSigValidity" SG_ 830 RDC_TypeOption 0;
BA_ "NetworkRequest" SG_ 830 RDC_TypeOption 0;
BA_ "NetworkRequestHoldingTime" SG_ 830 RDC_TypeOption 5000;
BA_ "Version" SG_ 830 RDC_TypeOption "23.07.06";
BA_ "GenSigSendType" SG_ 830 RLRrDrCurtainDownInitState 4;
BA_ "UserSigValidity" SG_ 830 RLRrDrCurtainDownInitState 0;
BA_ "NetworkRequest" SG_ 830 RLRrDrCurtainDownInitState 0;
BA_ "NetworkRequestHoldingTime" SG_ 830 RLRrDrCurtainDownInitState 5000;
BA_ "Version" SG_ 830 RLRrDrCurtainDownInitState "24.01.05";
BA_ "Description" SG_ 830 PwrDRBuzzerOut_RL_New "JG~";
BA_ "GenSigSendType" SG_ 830 PwrDRBuzzerOut_RL_New 4;
BA_ "UserSigValidity" SG_ 830 PwrDRBuzzerOut_RL_New 0;
BA_ "NetworkRequest" SG_ 830 PwrDRBuzzerOut_RL_New 0;
BA_ "NetworkRequestHoldingTime" SG_ 830 PwrDRBuzzerOut_RL_New 5000;
BA_ "Version" SG_ 830 PwrDRBuzzerOut_RL_New "24.01.05";
BA_ "Description" SG_ 830 PwrDrSta_RrLt "JG~";
BA_ "GenSigSendType" SG_ 830 PwrDrSta_RrLt 4;
BA_ "UserSigValidity" SG_ 830 PwrDrSta_RrLt 0;
BA_ "NetworkRequest" SG_ 830 PwrDrSta_RrLt 0;
BA_ "NetworkRequestHoldingTime" SG_ 830 PwrDrSta_RrLt 5000;
BA_ "Version" SG_ 830 PwrDrSta_RrLt "24.01.05";
BA_ "Description" SG_ 830 SBCM_RL_SlidePosition "DHMC_RL_SlidePosition";
BA_ "GenSigSendType" SG_ 830 SBCM_RL_SlidePosition 4;
BA_ "GenSigStartValue" SG_ 830 SBCM_RL_SlidePosition 255;
BA_ "UserSigValidity" SG_ 830 SBCM_RL_SlidePosition 0;
BA_ "NetworkRequest" SG_ 830 SBCM_RL_SlidePosition 0;
BA_ "NetworkRequestHoldingTime" SG_ 830 SBCM_RL_SlidePosition 5000;
BA_ "Version" SG_ 830 SBCM_RL_SlidePosition "24.01.05";
BA_ "Description" SG_ 830 SBCM_RL_DoorAngle "PDSM_RL_DoorAngle";
BA_ "GenSigSendType" SG_ 830 SBCM_RL_DoorAngle 4;
BA_ "GenSigStartValue" SG_ 830 SBCM_RL_DoorAngle 100;
BA_ "UserSigValidity" SG_ 830 SBCM_RL_DoorAngle 0;
BA_ "NetworkRequest" SG_ 830 SBCM_RL_DoorAngle 0;
BA_ "NetworkRequestHoldingTime" SG_ 830 SBCM_RL_DoorAngle 5000;
BA_ "Version" SG_ 830 SBCM_RL_DoorAngle "24.01.05";
BA_ "GenSigSendType" SG_ 830 RLDoorPushAlarm 4;
BA_ "UserSigValidity" SG_ 830 RLDoorPushAlarm 0;
BA_ "NetworkRequest" SG_ 830 RLDoorPushAlarm 0;
BA_ "NetworkRequestHoldingTime" SG_ 830 RLDoorPushAlarm 5000;
BA_ "Version" SG_ 830 RLDoorPushAlarm "21.07.07";
BA_ "Description" SG_ 830 RL_CrashUnlockCmd "RearLefrCrashUnlockCommand";
BA_ "GenSigSendType" SG_ 830 RL_CrashUnlockCmd 4;
BA_ "UserSigValidity" SG_ 830 RL_CrashUnlockCmd 0;
BA_ "NetworkRequest" SG_ 830 RL_CrashUnlockCmd 0;
BA_ "Version" SG_ 830 RL_CrashUnlockCmd "21.07.07";
BA_ "Description" SG_ 830 Warn_RrLftDrSwSta_SBCM "Warning Rear Left Door Switch Status";
BA_ "GenSigSendType" SG_ 830 Warn_RrLftDrSwSta_SBCM 4;
BA_ "UserSigValidity" SG_ 830 Warn_RrLftDrSwSta_SBCM 0;
BA_ "NetworkRequest" SG_ 830 Warn_RrLftDrSwSta_SBCM 0;
BA_ "Version" SG_ 830 Warn_RrLftDrSwSta_SBCM "21.09.05";
BA_ "Description" SG_ 830 DoorLock_RrLftDrUnLkSta_SBCM "Rear Left Door Unlock Status";
BA_ "GenSigSendType" SG_ 830 DoorLock_RrLftDrUnLkSta_SBCM 4;
BA_ "UserSigValidity" SG_ 830 DoorLock_RrLftDrUnLkSta_SBCM 0;
BA_ "NetworkRequest" SG_ 830 DoorLock_RrLftDrUnLkSta_SBCM 0;
BA_ "Version" SG_ 830 DoorLock_RrLftDrUnLkSta_SBCM "21.07.07";
BA_ "Description" SG_ 830 RL_SEAActivated "Rear Left SEA Activated";
BA_ "GenSigSendType" SG_ 830 RL_SEAActivated 4;
BA_ "UserSigValidity" SG_ 830 RL_SEAActivated 0;
BA_ "NetworkRequest" SG_ 830 RL_SEAActivated 0;
BA_ "Version" SG_ 830 RL_SEAActivated "21.07.07";
BA_ "Description" SG_ 830 RL_SEAWarn "RearLeftSEAWarning";
BA_ "GenSigSendType" SG_ 830 RL_SEAWarn 4;
BA_ "UserSigValidity" SG_ 830 RL_SEAWarn 0;
BA_ "NetworkRequest" SG_ 830 RL_SEAWarn 0;
BA_ "Version" SG_ 830 RL_SEAWarn "21.07.07";
BA_ "GenSigSendType" SG_ 830 RL_SEWWarn 4;
BA_ "UserSigValidity" SG_ 830 RL_SEWWarn 0;
BA_ "NetworkRequest" SG_ 830 RL_SEWWarn 0;
BA_ "Version" SG_ 830 RL_SEWWarn "21.07.07";
BA_ "GenSigSendType" SG_ 830 RL_ReleaseWarn 4;
BA_ "UserSigValidity" SG_ 830 RL_ReleaseWarn 0;
BA_ "NetworkRequest" SG_ 830 RL_ReleaseWarn 0;
BA_ "NetworkRequestHoldingTime" SG_ 830 RL_ReleaseWarn 5000;
BA_ "Version" SG_ 830 RL_ReleaseWarn "21.09.05";
BA_ "GenSigSendType" SG_ 830 RL_SWFailAlarm 4;
BA_ "UserSigValidity" SG_ 830 RL_SWFailAlarm 0;
BA_ "NetworkRequest" SG_ 830 RL_SWFailAlarm 0;
BA_ "NetworkRequestHoldingTime" SG_ 830 RL_SWFailAlarm 5000;
BA_ "Version" SG_ 830 RL_SWFailAlarm "21.07.07";
BA_ "GenSigSendType" SG_ 830 RL_ChildLock_ActnFlSta 4;
BA_ "UserSigValidity" SG_ 830 RL_ChildLock_ActnFlSta 0;
BA_ "NetworkRequest" SG_ 830 RL_ChildLock_ActnFlSta 0;
BA_ "NetworkRequestHoldingTime" SG_ 830 RL_ChildLock_ActnFlSta 5000;
BA_ "Version" SG_ 830 RL_ChildLock_ActnFlSta "21.07.07";
BA_ "GenSigSendType" SG_ 830 RL_MRActivationAlarm 4;
BA_ "UserSigValidity" SG_ 830 RL_MRActivationAlarm 0;
BA_ "NetworkRequest" SG_ 830 RL_MRActivationAlarm 0;
BA_ "NetworkRequestHoldingTime" SG_ 830 RL_MRActivationAlarm 5000;
BA_ "Version" SG_ 830 RL_MRActivationAlarm "21.07.07";
BA_ "GenSigSendType" SG_ 830 RL_ChildLock_Status 4;
BA_ "UserSigValidity" SG_ 830 RL_ChildLock_Status 0;
BA_ "NetworkRequest" SG_ 830 RL_ChildLock_Status 0;
BA_ "NetworkRequestHoldingTime" SG_ 830 RL_ChildLock_Status 5000;
BA_ "Version" SG_ 830 RL_ChildLock_Status "21.07.07";
BA_ "Description" SG_ 1837 WPC_GST_Byte0 "TP Index : 180";
BA_ "UsrSigPurpose" SG_ 1837 WPC_GST_Byte0 4;
BA_ "UserSigValidity" SG_ 1837 WPC_GST_Byte0 0;
BA_ "NetworkRequest" SG_ 1837 WPC_GST_Byte0 0;
BA_ "NetworkRequestHoldingTime" SG_ 1837 WPC_GST_Byte0 5000;
BA_ "Version" SG_ 1837 WPC_GST_Byte0 "22.07.01";
BA_ "Description" SG_ 1837 WPC_GST_Byte2 "TP Index : 180";
BA_ "UsrSigPurpose" SG_ 1837 WPC_GST_Byte2 4;
BA_ "UserSigValidity" SG_ 1837 WPC_GST_Byte2 0;
BA_ "NetworkRequest" SG_ 1837 WPC_GST_Byte2 0;
BA_ "NetworkRequestHoldingTime" SG_ 1837 WPC_GST_Byte2 5000;
BA_ "Version" SG_ 1837 WPC_GST_Byte2 "22.07.01";
BA_ "Description" SG_ 1837 WPC_GST_Byte3 "TP Index : 180";
BA_ "UsrSigPurpose" SG_ 1837 WPC_GST_Byte3 4;
BA_ "UserSigValidity" SG_ 1837 WPC_GST_Byte3 0;
BA_ "NetworkRequest" SG_ 1837 WPC_GST_Byte3 0;
BA_ "NetworkRequestHoldingTime" SG_ 1837 WPC_GST_Byte3 5000;
BA_ "Version" SG_ 1837 WPC_GST_Byte3 "22.07.01";
BA_ "Description" SG_ 1837 WPC_GST_Byte4 "TP Index : 180";
BA_ "UsrSigPurpose" SG_ 1837 WPC_GST_Byte4 4;
BA_ "UserSigValidity" SG_ 1837 WPC_GST_Byte4 0;
BA_ "NetworkRequest" SG_ 1837 WPC_GST_Byte4 0;
BA_ "NetworkRequestHoldingTime" SG_ 1837 WPC_GST_Byte4 5000;
BA_ "Version" SG_ 1837 WPC_GST_Byte4 "22.07.01";
BA_ "Description" SG_ 1837 WPC_GST_Byte5 "TP Index : 180";
BA_ "UsrSigPurpose" SG_ 1837 WPC_GST_Byte5 4;
BA_ "UserSigValidity" SG_ 1837 WPC_GST_Byte5 0;
BA_ "NetworkRequest" SG_ 1837 WPC_GST_Byte5 0;
BA_ "NetworkRequestHoldingTime" SG_ 1837 WPC_GST_Byte5 5000;
BA_ "Version" SG_ 1837 WPC_GST_Byte5 "22.07.01";
BA_ "Description" SG_ 1837 WPC_GST_Byte6 "TP Index : 180";
BA_ "UsrSigPurpose" SG_ 1837 WPC_GST_Byte6 4;
BA_ "UserSigValidity" SG_ 1837 WPC_GST_Byte6 0;
BA_ "NetworkRequest" SG_ 1837 WPC_GST_Byte6 0;
BA_ "NetworkRequestHoldingTime" SG_ 1837 WPC_GST_Byte6 5000;
BA_ "Version" SG_ 1837 WPC_GST_Byte6 "22.07.01";
BA_ "Description" SG_ 1837 WPC_GST_Byte7 "TP Index : 180";
BA_ "UsrSigPurpose" SG_ 1837 WPC_GST_Byte7 4;
BA_ "UserSigValidity" SG_ 1837 WPC_GST_Byte7 0;
BA_ "NetworkRequest" SG_ 1837 WPC_GST_Byte7 0;
BA_ "NetworkRequestHoldingTime" SG_ 1837 WPC_GST_Byte7 5000;
BA_ "Version" SG_ 1837 WPC_GST_Byte7 "22.07.01";
BA_ "Description" SG_ 1837 WPC_GST_Byte1 "TP Index : 180";
BA_ "UsrSigPurpose" SG_ 1837 WPC_GST_Byte1 4;
BA_ "UserSigValidity" SG_ 1837 WPC_GST_Byte1 0;
BA_ "NetworkRequest" SG_ 1837 WPC_GST_Byte1 0;
BA_ "NetworkRequestHoldingTime" SG_ 1837 WPC_GST_Byte1 5000;
BA_ "Version" SG_ 1837 WPC_GST_Byte1 "22.07.01";
BA_ "Description" SG_ 256 EMS_Crc2Val "The data area for CRC calculation is based on the data length (DLC) of the message DB.

The CRC shall be calculated over the entire data block (excluding the CRC bytes) including the user data, alive counter and Data ID



- CRC Polynomial (0x1021) , Ini";
BA_ "GenSigStartValue" SG_ 256 EMS_Crc2Val 65535;
BA_ "UserSigValidity" SG_ 256 EMS_Crc2Val 3;
BA_ "RoutingFactor" SG_ 256 EMS_Crc2Val 5;
BA_ "Version" SG_ 256 EMS_Crc2Val "21.09.03";
BA_ "Description" SG_ 256 ACC_CrsMainSwLmpSta "This signal indicates that an ECU requests cluster to turn on/off auto-cruise control “MAIN” switch indication lamp.



This signal is for the CAN-type cluster installed vehicled only.";
BA_ "UserSigValidity" SG_ 256 ACC_CrsMainSwLmpSta 3;
BA_ "RoutingFactor" SG_ 256 ACC_CrsMainSwLmpSta 5;
BA_ "Version" SG_ 256 ACC_CrsMainSwLmpSta "17.12.00";
BA_ "Description" SG_ 256 ACC_CrsSetSwLmpSta "This signal indicates that an ECU requests cluster to turn on/off auto-cruise control “SET” switch indication lamp.



This signal is for the CAN-type cluster installed vehicled only.";
BA_ "UserSigValidity" SG_ 256 ACC_CrsSetSwLmpSta 3;
BA_ "RoutingFactor" SG_ 256 ACC_CrsSetSwLmpSta 5;
BA_ "Version" SG_ 256 ACC_CrsSetSwLmpSta "17.12.00";
BA_ "Description" SG_ 256 ENG_LV_FUP_ENA_THD "The signal indicates that the status of the pressure on fuel rail is enough high to start engine.

(LPI)";
BA_ "UserSigValidity" SG_ 256 ENG_LV_FUP_ENA_THD 3;
BA_ "RoutingFactor" SG_ 256 ENG_LV_FUP_ENA_THD 5;
BA_ "Version" SG_ 256 ENG_LV_FUP_ENA_THD "18.12.01";
BA_ "Description" SG_ 256 ENG_SoakTimeErrSta "This signal indicates that information on soak time error.";
BA_ "UserSigValidity" SG_ 256 ENG_SoakTimeErrSta 3;
BA_ "RoutingFactor" SG_ 256 ENG_SoakTimeErrSta 5;
BA_ "Version" SG_ 256 ENG_SoakTimeErrSta "17.12.00";
BA_ "Description" SG_ 256 ENG_SoakTimeVal "The Signal SOAK_TIME means the duration from Engine Ignition Off to Ignition On.";
BA_ "UserSigValidity" SG_ 256 ENG_SoakTimeVal 3;
BA_ "RoutingFactor" SG_ 256 ENG_SoakTimeVal 5;
BA_ "Version" SG_ 256 ENG_SoakTimeVal "17.12.00";
BA_ "Description" SG_ 256 ENG_SprkTimeVal "This signal indicates output value of final spark timing from ECU which reflects torque intervention requests by ESC(TCS), SCC and TCU.



Physical range:

-35.625˚ … 0˚  =  00H .. 5FH (Retard)

0.375˚ … 60˚  =  60H .. FFH (Advance) 



Conversion:";
BA_ "UserSigValidity" SG_ 256 ENG_SprkTimeVal 3;
BA_ "RoutingFactor" SG_ 256 ENG_SprkTimeVal 5;
BA_ "Version" SG_ 256 ENG_SprkTimeVal "17.12.00";
BA_ "Description" SG_ 256 ENG_MinIndTqVal "The signal TQI_MIN is the minimum engine torque (minimum air charging rate) which can be fired without misfire including compensation factors such as atmospheric pressure and temperature.

It is not enough to keep the engine running without external powe";
BA_ "UserSigValidity" SG_ 256 ENG_MinIndTqVal 3;
BA_ "RoutingFactor" SG_ 256 ENG_MinIndTqVal 5;
BA_ "Version" SG_ 256 ENG_MinIndTqVal "18.01.01";
BA_ "Description" SG_ 256 ENG_TrgtTqVal "The signal TQI_TARGET is determined by an engine torque map with input which consists of  acceleration pedal value, MAF sensor, current RPM and etc. This signal reflects driver’s demand directly. 

But it does not depend on torque interventions realised";
BA_ "UserSigValidity" SG_ 256 ENG_TrgtTqVal 3;
BA_ "RoutingFactor" SG_ 256 ENG_TrgtTqVal 5;
BA_ "Version" SG_ 256 ENG_TrgtTqVal "18.01.01";
BA_ "Description" SG_ 256 EMS_AlvCnt2Val "For the first transmission request for a data element the counter shall be initialized with 0 and shall be incremented by 1 for every subsequent send request. 

When the counter reaches the maximum value(0xFF), then it shall restart with 0 for the next s";
BA_ "UserSigValidity" SG_ 256 EMS_AlvCnt2Val 3;
BA_ "RoutingFactor" SG_ 256 EMS_AlvCnt2Val 5;
BA_ "Version" SG_ 256 EMS_AlvCnt2Val "21.09.03";
BA_ "Description" SG_ 256 ENG_MaxIndTqVal "The signal TQI_MAX is the current maximum indicated engine torque. This signal reflects the maximum engine torque under current conditions (engine speed, etc…).



Note : TQI_MAX must be transmitted actual engine torque including COT, thermal/spark effi";
BA_ "UserSigValidity" SG_ 256 ENG_MaxIndTqVal 3;
BA_ "RoutingFactor" SG_ 256 ENG_MaxIndTqVal 5;
BA_ "Version" SG_ 256 ENG_MaxIndTqVal "18.01.01";
BA_ "Description" SG_ 256 ENG_AppAccelPdlSta "This signal indicates if the driver applies the accelerator pedal. 

The signal always indicates the actual operation of the accelerator pedal, independent from SCC mode.";
BA_ "UserSigValidity" SG_ 256 ENG_AppAccelPdlSta 3;
BA_ "RoutingFactor" SG_ 256 ENG_AppAccelPdlSta 5;
BA_ "Version" SG_ 256 ENG_AppAccelPdlSta "17.12.00";
BA_ "Description" SG_ 256 ENG_BrkCtrlReq "This signal indicates that if brake control request during cruise control or speed limiter is active or not. This signal is for prevention of unwanted vehicle speed increase during cruise control or speed limiter control mode.";
BA_ "UserSigValidity" SG_ 256 ENG_BrkCtrlReq 3;
BA_ "RoutingFactor" SG_ 256 ENG_BrkCtrlReq 5;
BA_ "Version" SG_ 256 ENG_BrkCtrlReq "17.12.00";
BA_ "Description" SG_ 256 ACC_DnShftCtrlReq "This signal indicates target gear for downshift control request during cruise control or speed limiter is active or not. This signal is for prevention of unwanted vehicle speed increase during cruise control or speed limiter control mode.";
BA_ "UserSigValidity" SG_ 256 ACC_DnShftCtrlReq 3;
BA_ "RoutingFactor" SG_ 256 ACC_DnShftCtrlReq 5;
BA_ "Version" SG_ 256 ACC_DnShftCtrlReq "17.12.00";
BA_ "Description" SG_ 256 ENG_DclBrkCntrlReq "When current vehicle speed goes over set vehicle speed in the downhill during cruise control or speed limiter, ECU requests brake control to TCS with target deceleration. This is function of (Current vehicle speed - Set vehicle speed).";
BA_ "GenSigStartValue" SG_ 256 ENG_DclBrkCntrlReq 4094;
BA_ "UserSigValidity" SG_ 256 ENG_DclBrkCntrlReq 3;
BA_ "RoutingFactor" SG_ 256 ENG_DclBrkCntrlReq 5;
BA_ "Version" SG_ 256 ENG_DclBrkCntrlReq "17.12.00";
BA_ "Description" SG_ 256 ENG_BstPrsrVal "Boost pressure for Turbo engine";
BA_ "UserSigValidity" SG_ 256 ENG_BstPrsrVal 3;
BA_ "RoutingFactor" SG_ 256 ENG_BstPrsrVal 5;
BA_ "Version" SG_ 256 ENG_BstPrsrVal "17.12.00";
BA_ "Description" SG_ 256 ENG_EngOilTempVal "engine oil temperature";
BA_ "GenSigStartValue" SG_ 256 ENG_EngOilTempVal 53;
BA_ "UserSigValidity" SG_ 256 ENG_EngOilTempVal 3;
BA_ "RoutingFactor" SG_ 256 ENG_EngOilTempVal 5;
BA_ "Version" SG_ 256 ENG_EngOilTempVal "17.12.00";
BA_ "Description" SG_ 256 ENG_AmbtTempModelVal "Modeled Ambient temperature";
BA_ "GenSigStartValue" SG_ 256 ENG_AmbtTempModelVal 164;
BA_ "UserSigValidity" SG_ 256 ENG_AmbtTempModelVal 3;
BA_ "RoutingFactor" SG_ 256 ENG_AmbtTempModelVal 5;
BA_ "Version" SG_ 256 ENG_AmbtTempModelVal "17.12.00";
BA_ "Description" SG_ 256 ENG_DpfWrngSta "The signal indicates the status of the 'DPF Warning Level'";
BA_ "UserSigValidity" SG_ 256 ENG_DpfWrngSta 3;
BA_ "RoutingFactor" SG_ 256 ENG_DpfWrngSta 5;
BA_ "Version" SG_ 256 ENG_DpfWrngSta "17.12.00";
BA_ "Description" SG_ 256 ENG_BattWrngLmpSta "The signal indicates the status of the 'Battery Warning Lamp'";
BA_ "UserSigValidity" SG_ 256 ENG_BattWrngLmpSta 3;
BA_ "RoutingFactor" SG_ 256 ENG_BattWrngLmpSta 5;
BA_ "Version" SG_ 256 ENG_BattWrngLmpSta "17.12.00";
BA_ "Description" SG_ 256 ENG_OilPrsrWrngLmpSta "The signal indicates the status of the 'Oil Pressure Warning Lamp'";
BA_ "UserSigValidity" SG_ 256 ENG_OilPrsrWrngLmpSta 3;
BA_ "RoutingFactor" SG_ 256 ENG_OilPrsrWrngLmpSta 5;
BA_ "Version" SG_ 256 ENG_OilPrsrWrngLmpSta "17.12.00";
BA_ "Description" SG_ 256 ENG_IsgInhbtLmpSta "The signal indicates the status of the 'ISG Inhibit Lamp'";
BA_ "UserSigValidity" SG_ 256 ENG_IsgInhbtLmpSta 3;
BA_ "RoutingFactor" SG_ 256 ENG_IsgInhbtLmpSta 5;
BA_ "Version" SG_ 256 ENG_IsgInhbtLmpSta "17.12.00";
BA_ "Description" SG_ 256 ENG_BrkSwSta "This signal indicates that a brake switch is activated or not. When the brake switch is activated(pressed) its value is 01H otherwise its value is 00H.

If the EMS does not support this signal the value is 02H.



Physical range : 0 ... 100

Conversion :";
BA_ "GenSigStartValue" SG_ 256 ENG_BrkSwSta 1;
BA_ "UserSigValidity" SG_ 256 ENG_BrkSwSta 3;
BA_ "RoutingFactor" SG_ 256 ENG_BrkSwSta 5;
BA_ "Version" SG_ 256 ENG_BrkSwSta "18.11.00";
BA_ "Description" SG_ 256 ENG_ObdFrzFrmSta "An ECU which detects an OBD fault, requires the EMS to store a set of environmental conditions

(freeze frame). If the EMS follows this requirement it is acknowledged in OBD_FRF_ACK. Also the synchronization of OBD relevant ECUs is made by this signal:

";
BA_ "UserSigValidity" SG_ 256 ENG_ObdFrzFrmSta 3;
BA_ "RoutingFactor" SG_ 256 ENG_ObdFrzFrmSta 5;
BA_ "Version" SG_ 256 ENG_ObdFrzFrmSta "17.12.00";
BA_ "Description" SG_ 256 ENG_EngClntTempVal "Engine coolant temperature in EMS sensed via an A/D converter; converted into degrees centigrade (°C).";
BA_ "GenSigStartValue" SG_ 256 ENG_EngClntTempVal 255;
BA_ "UserSigValidity" SG_ 256 ENG_EngClntTempVal 3;
BA_ "RoutingFactor" SG_ 256 ENG_EngClntTempVal 5;
BA_ "Version" SG_ 256 ENG_EngClntTempVal "17.12.00";
BA_ "Description" SG_ 256 ENG_MafCrctVal "The altitude correction factor MAF_FAC_ALTI_MMV is calculated from division of MAF by MAF_SUB_DIAG (=limp home-value for MAF) or from AMP_AD by 1013 mbar in order to take into account different atmospheric pressures at different altitudes.



The Initial";
BA_ "GenSigStartValue" SG_ 256 ENG_MafCrctVal 128;
BA_ "UserSigValidity" SG_ 256 ENG_MafCrctVal 3;
BA_ "RoutingFactor" SG_ 256 ENG_MafCrctVal 5;
BA_ "Version" SG_ 256 ENG_MafCrctVal "17.12.00";
BA_ "Description" SG_ 256 ENG_BattDscnctSta "The signal specifies that ECU has detected a disconnection of the battery since last driving cycle, and therefore has reset the adaptive values and failure memory.

If the EMS does not support this signal the value is 00H



The failure memory erasure is";
BA_ "UserSigValidity" SG_ 256 ENG_BattDscnctSta 3;
BA_ "RoutingFactor" SG_ 256 ENG_BattDscnctSta 5;
BA_ "Version" SG_ 256 ENG_BattDscnctSta "17.12.00";
BA_ "Description" SG_ 256 OBD_MilConfgVal "The signal specifies the Configuration of the MIL Handling and Failure Memory Management by ECU.";
BA_ "GenSigStartValue" SG_ 256 OBD_MilConfgVal 3;
BA_ "UserSigValidity" SG_ 256 OBD_MilConfgVal 3;
BA_ "RoutingFactor" SG_ 256 OBD_MilConfgVal 5;
BA_ "Version" SG_ 256 OBD_MilConfgVal "17.12.00";
BA_ "Description" SG_ 256 ENG_EngSta "This signal indicates that a status of engine.";
BA_ "UserSigValidity" SG_ 256 ENG_EngSta 3;
BA_ "RoutingFactor" SG_ 256 ENG_EngSta 5;
BA_ "Version" SG_ 256 ENG_EngSta "17.12.00";
BA_ "Description" SG_ 256 ENG_Ack4EngStpSta "The signal specifies the acknowledgement of the request for the operating state 'engine stopped'.";
BA_ "UserSigValidity" SG_ 256 ENG_Ack4EngStpSta 3;
BA_ "RoutingFactor" SG_ 256 ENG_Ack4EngStpSta 5;
BA_ "Version" SG_ 256 ENG_Ack4EngStpSta "17.12.00";
BA_ "Description" SG_ 256 ENG_OverDrvOffReq "This signal indicates that auto cruise control function requests over drive off of TCU. 

In general, the over drive off request is done by hardware. (i.e. line-to-line signal between an EMS and a TCU). However, some systems may not have external over dr";
BA_ "UserSigValidity" SG_ 256 ENG_OverDrvOffReq 3;
BA_ "RoutingFactor" SG_ 256 ENG_OverDrvOffReq 5;
BA_ "Version" SG_ 256 ENG_OverDrvOffReq "17.12.00";
BA_ "Description" SG_ 256 ENG_AccActSta "EMS sends the state of the cruise control via the signal ACC_ACT. 

If the EMS does not support this signal the value is 00H



If the cruise control is activated then ACC_ACT = 1. In this period, vehicle speed control (cruise control) is performed by th";
BA_ "UserSigValidity" SG_ 256 ENG_AccActSta 3;
BA_ "RoutingFactor" SG_ 256 ENG_AccActSta 5;
BA_ "Version" SG_ 256 ENG_AccActSta "17.12.00";
BA_ "Description" SG_ 256 ENG_CltchOpSta "This signal indicates that ECU has detected an operation of a clutch. Using this signal an ISG (Idle Stop & Go) system acts as an alternator or a starter.



If the EMS does not support this signal the value is 00H";
BA_ "UserSigValidity" SG_ 256 ENG_CltchOpSta 3;
BA_ "RoutingFactor" SG_ 256 ENG_CltchOpSta 5;
BA_ "Version" SG_ 256 ENG_CltchOpSta "17.12.00";
BA_ "Description" SG_ 256 EMS_BrkReq_Slope "Brake request at slope for anti-stall";
BA_ "UserSigValidity" SG_ 256 EMS_BrkReq_Slope 3;
BA_ "RoutingFactor" SG_ 256 EMS_BrkReq_Slope 5;
BA_ "Version" SG_ 256 EMS_BrkReq_Slope "20.04.06";
BA_ "Description" SG_ 256 ENG_AccDrvAlertDisp "If EMS sends the No Auto cruise engaged status or Auto cruise Disengaged status, 

Cluster shall display the status of Auto cruise.";
BA_ "TimeoutValue" SG_ 256 ENG_AccDrvAlertDisp "0x0";
BA_ "UserSigValidity" SG_ 256 ENG_AccDrvAlertDisp 3;
BA_ "RoutingFactor" SG_ 256 ENG_AccDrvAlertDisp 5;
BA_ "Version" SG_ 256 ENG_AccDrvAlertDisp "19.12.08";
BA_ "Description" SG_ 256 DSL_GlowCtrlReq "This signal indicates that a diesel ECU requests ISS system to control glow plugs. 



If the EMS does not support this signal the value is 00H";
BA_ "UserSigValidity" SG_ 256 DSL_GlowCtrlReq 3;
BA_ "RoutingFactor" SG_ 256 DSL_GlowCtrlReq 5;
BA_ "Version" SG_ 256 DSL_GlowCtrlReq "17.12.00";
BA_ "Description" SG_ 256 ENG_GlowLmpSta "This signal indicates that a status of glow lamp.



This signal is used for a Diesel or LPI Engine alternatively.";
BA_ "GenSigStartValue" SG_ 256 ENG_GlowLmpSta 1;
BA_ "UserSigValidity" SG_ 256 ENG_GlowLmpSta 3;
BA_ "RoutingFactor" SG_ 256 ENG_GlowLmpSta 5;
BA_ "Version" SG_ 256 ENG_GlowLmpSta "17.12.00";
BA_ "Description" SG_ 256 ENG_ThrPosVal "The signal TPS is a measure of the throttle position.

The throttle position is determined via a potentiometer, which is connected mechanically to the throttle shaft. The voltage value, which is adjusted in the port via the voltage divider, is sensed in ";
BA_ "GenSigStartValue" SG_ 256 ENG_ThrPosVal 32;
BA_ "UserSigValidity" SG_ 256 ENG_ThrPosVal 3;
BA_ "RoutingFactor" SG_ 256 ENG_ThrPosVal 5;
BA_ "Version" SG_ 256 ENG_ThrPosVal "17.12.00";
BA_ "Description" SG_ 256 ENG_AccelPdlVal "The signal PV_AV_CAN is a measure of the Accelerator Pedal value.

The accelerator pedal value is determined via 2 pedal sensors, which are connected mechanically to the

accelerator pedal. If the EMS-ECU recognizes that the accelerator pedal is not acti";
BA_ "UserSigValidity" SG_ 256 ENG_AccelPdlVal 3;
BA_ "RoutingFactor" SG_ 256 ENG_AccelPdlVal 5;
BA_ "Version" SG_ 256 ENG_AccelPdlVal "18.01.01";
BA_ "Description" SG_ 1233 CLU_Crc5Val "The data area for CRC calculation is based on the data length (DLC) of the message DB.

The CRC shall be calculated over the entire data block (excluding the CRC bytes) including the user data, alive counter and Data ID



- CRC Polynomial (0x1021) , Ini";
BA_ "GenSigSendType" SG_ 1233 CLU_Crc5Val 4;
BA_ "GenSigStartValue" SG_ 1233 CLU_Crc5Val 65535;
BA_ "UserSigValidity" SG_ 1233 CLU_Crc5Val 3;
BA_ "Version" SG_ 1233 CLU_Crc5Val "21.09.03";
BA_ "Description" SG_ 1233 CLU_AlvCnt5Val "For the first transmission request for a data element the counter shall be initialized with 0 and shall be incremented by 1 for every subsequent send request. 

When the counter reaches the maximum value(0xFF), then it shall restart with 0 for the next s";
BA_ "GenSigSendType" SG_ 1233 CLU_AlvCnt5Val 4;
BA_ "UserSigValidity" SG_ 1233 CLU_AlvCnt5Val 3;
BA_ "Version" SG_ 1233 CLU_AlvCnt5Val "21.09.03";
BA_ "Description" SG_ 1233 USM_TlgtAwayCloseSetReq "This signal is used for a request to set the value of USM Menus. 

This signal requests to set Tailgate Away close system On/Off

When this signal change, the message is sent 3 times.";
BA_ "GenSigSendType" SG_ 1233 USM_TlgtAwayCloseSetReq 4;
BA_ "UserSigValidity" SG_ 1233 USM_TlgtAwayCloseSetReq 3;
BA_ "Version" SG_ 1233 USM_TlgtAwayCloseSetReq "20.03.02";
BA_ "Description" SG_ 1233 USM_InletAutoLockSetReq "This signal is used for a request to set the value of USM Menus. This signal requests to change status of Charging Connector Locking Mode.";
BA_ "GenSigSendType" SG_ 1233 USM_InletAutoLockSetReq 4;
BA_ "UserSigValidity" SG_ 1233 USM_InletAutoLockSetReq 3;
BA_ "Version" SG_ 1233 USM_InletAutoLockSetReq "19.01.10";
BA_ "Description" SG_ 1233 USM_IFSActVehSpd_Set "IFS 진입 속도 설정 메뉴";
BA_ "GenSigSendType" SG_ 1233 USM_IFSActVehSpd_Set 4;
BA_ "UserSigValidity" SG_ 1233 USM_IFSActVehSpd_Set 3;
BA_ "Version" SG_ 1233 USM_IFSActVehSpd_Set "21.09.05";
BA_ "Description" SG_ 1233 USM_StaRst1Req "This signal is used for a request to reset the value of USM menus.

When this signal change, the message (CLU16) is sent 3 times.";
BA_ "GenSigSendType" SG_ 1233 USM_StaRst1Req 4;
BA_ "UserSigValidity" SG_ 1233 USM_StaRst1Req 3;
BA_ "Version" SG_ 1233 USM_StaRst1Req "17.11.00";
BA_ "Description" SG_ 1233 USM_NccCamSetReq "This signal describes the status of CC with Navigation function.(speed camera control) - User Setting Menu for the cluster";
BA_ "GenSigSendType" SG_ 1233 USM_NccCamSetReq 4;
BA_ "UserSigValidity" SG_ 1233 USM_NccCamSetReq 3;
BA_ "Version" SG_ 1233 USM_NccCamSetReq "17.11.00";
BA_ "Description" SG_ 1233 CLU_RrStRemindDelayReq "This singal is the delay request for ROA";
BA_ "GenSigSendType" SG_ 1233 CLU_RrStRemindDelayReq 4;
BA_ "UserSigValidity" SG_ 1233 CLU_RrStRemindDelayReq 0;
BA_ "Version" SG_ 1233 CLU_RrStRemindDelayReq "22.05.02";
BA_ "Description" SG_ 1233 CLU_RrStRemindDelayFdbckReq "This signal is user input feedback for Rear Seat Reminder";
BA_ "GenSigSendType" SG_ 1233 CLU_RrStRemindDelayFdbckReq 4;
BA_ "UserSigValidity" SG_ 1233 CLU_RrStRemindDelayFdbckReq 0;
BA_ "Version" SG_ 1233 CLU_RrStRemindDelayFdbckReq "22.05.02";
BA_ "GenSigSendType" SG_ 1233 USM_AdasLDW2SetReq 4;
BA_ "UserSigValidity" SG_ 1233 USM_AdasLDW2SetReq 3;
BA_ "Version" SG_ 1233 USM_AdasLDW2SetReq "22.09.02";
BA_ "Description" SG_ 1233 CLU_DTELearnResetReq "This signal is used for a request to reset learning data for DTE display";
BA_ "GenSigSendType" SG_ 1233 CLU_DTELearnResetReq 4;
BA_ "UserSigValidity" SG_ 1233 CLU_DTELearnResetReq 3;
BA_ "Version" SG_ 1233 CLU_DTELearnResetReq "22.11.03";
BA_ "Description" SG_ 1233 CLU_SelfRgnSetReq "This signal is for self regenerative system.

this signal is sent to EMS

 -  0x2 : when request to operating self regenerative system

 -  0x1 : when request to stop self regenerative system";
BA_ "GenSigSendType" SG_ 1233 CLU_SelfRgnSetReq 4;
BA_ "UserSigValidity" SG_ 1233 CLU_SelfRgnSetReq 3;
BA_ "Version" SG_ 1233 CLU_SelfRgnSetReq "23.12.01";
BA_ "Description" SG_ 1233 CLU_PDWWrngSndMuteSoftKeySta "When the PDW warning mute button is pressed on the cluster, KEY ON signal(0x1) is transmitted to ADAS_PRK/BDC_FD.";
BA_ "GenSigSendType" SG_ 1233 CLU_PDWWrngSndMuteSoftKeySta 4;
BA_ "UserSigValidity" SG_ 1233 CLU_PDWWrngSndMuteSoftKeySta 3;
BA_ "Version" SG_ 1233 CLU_PDWWrngSndMuteSoftKeySta "24.06.00";
BA_ "Description" SG_ 1233 CLU_IccPopupOffReq "When ICC Drowsiness warning pop-up is displaying and press the OK button,

Cluster sends signal(0x1) to Adas.";
BA_ "GenSigSendType" SG_ 1233 CLU_IccPopupOffReq 4;
BA_ "UserSigValidity" SG_ 1233 CLU_IccPopupOffReq 3;
BA_ "Version" SG_ 1233 CLU_IccPopupOffReq "24.07.03";
BA_ "Description" SG_ 870 HU_GW_Crc3Val "The data area for CRC calculation is based on the data length (DLC) of the message DB.

The CRC shall be calculated over the entire data block (excluding the CRC bytes) including the user data, alive counter and Data ID



- CRC Polynomial (0x1021) , Ini";
BA_ "GenSigSendType" SG_ 870 HU_GW_Crc3Val 4;
BA_ "GenSigStartValue" SG_ 870 HU_GW_Crc3Val 65535;
BA_ "UserSigValidity" SG_ 870 HU_GW_Crc3Val 3;
BA_ "Version" SG_ 870 HU_GW_Crc3Val "22.10.20";
BA_ "GenSigSendType" SG_ 870 AVN_RSPA_Disp_Rdy 4;
BA_ "GenSigStartValue" SG_ 870 AVN_RSPA_Disp_Rdy 3;
BA_ "UserSigValidity" SG_ 870 AVN_RSPA_Disp_Rdy 0;
BA_ "Version" SG_ 870 AVN_RSPA_Disp_Rdy "22.06.01";
BA_ "Description" SG_ 870 CF_AVN_ProfileIDRValue "Profile 3~Profile9 value is only used from Vehicle Architecture 2.0 (STD_DB_CAR_R2, SV 24.6~) vehicle models

Vehicle Architecture 1.0 (STD_DB_CAR) vehicle models can use Guest, Profile1, Profile 2 only.";
BA_ "GenSigSendType" SG_ 870 CF_AVN_ProfileIDRValue 4;
BA_ "GenSigStartValue" SG_ 870 CF_AVN_ProfileIDRValue 15;
BA_ "UserSigValidity" SG_ 870 CF_AVN_ProfileIDRValue 0;
BA_ "Version" SG_ 870 CF_AVN_ProfileIDRValue "22.11.24";
BA_ "GenSigSendType" SG_ 870 HazardFromHUSVM 4;
BA_ "GenSigStartValue" SG_ 870 HazardFromHUSVM 3;
BA_ "UserSigValidity" SG_ 870 HazardFromHUSVM 0;
BA_ "Version" SG_ 870 HazardFromHUSVM "22.06.01";
BA_ "GenSigSendType" SG_ 870 OMUOSMirCtrl 4;
BA_ "GenSigStartValue" SG_ 870 OMUOSMirCtrl 3;
BA_ "UserSigValidity" SG_ 870 OMUOSMirCtrl 0;
BA_ "Version" SG_ 870 OMUOSMirCtrl "22.06.01";
BA_ "Description" SG_ 870 OTAUIStatus "0x00 : Headunit is booting so, Headunit can't display any state

0x01 : Headunit is normal state, Headunit could display according to CCU command.";
BA_ "GenSigSendType" SG_ 870 OTAUIStatus 4;
BA_ "UserSigValidity" SG_ 870 OTAUIStatus 0;
BA_ "Version" SG_ 870 OTAUIStatus "22.06.01";
BA_ "GenSigSendType" SG_ 870 C_TeleActiveStatus 4;
BA_ "GenSigStartValue" SG_ 870 C_TeleActiveStatus 3;
BA_ "UserSigValidity" SG_ 870 C_TeleActiveStatus 0;
BA_ "Version" SG_ 870 C_TeleActiveStatus "22.06.01";
BA_ "GenSigSendType" SG_ 870 HU_RTCCheck 4;
BA_ "GenSigStartValue" SG_ 870 HU_RTCCheck 3;
BA_ "TimeoutValue" SG_ 870 HU_RTCCheck "0x3";
BA_ "UserSigValidity" SG_ 870 HU_RTCCheck 3;
BA_ "Version" SG_ 870 HU_RTCCheck "22.06.01";
BA_ "Description" SG_ 870 HU_GW_AlvCnt3Val "For the first transmission request for a data element the counter shall be initialized with 0 and shall be incremented by 1 for every subsequent send request. 

When the counter reaches the maximum value(0xFF), then it shall restart with 0 for the next s";
BA_ "GenSigSendType" SG_ 870 HU_GW_AlvCnt3Val 4;
BA_ "UserSigValidity" SG_ 870 HU_GW_AlvCnt3Val 3;
BA_ "Version" SG_ 870 HU_GW_AlvCnt3Val "22.10.20";
BA_ "Description" SG_ 870 HU_SWRCWarmerSet "send 0x1(On) value while button press to ICU";
BA_ "GenSigSendType" SG_ 870 HU_SWRCWarmerSet 4;
BA_ "UserSigValidity" SG_ 870 HU_SWRCWarmerSet 3;
BA_ "Version" SG_ 870 HU_SWRCWarmerSet "22.06.01";
BA_ "Description" SG_ 870 HU_TrModeReq_PE "Trailer/Carrier Mode On/Off request";
BA_ "GenSigSendType" SG_ 870 HU_TrModeReq_PE 4;
BA_ "GenSigStartValue" SG_ 870 HU_TrModeReq_PE 7;
BA_ "UserSigValidity" SG_ 870 HU_TrModeReq_PE 3;
BA_ "Version" SG_ 870 HU_TrModeReq_PE "24.07.06";
BA_ "Description" SG_ 870 HU_TrBrakeTypeReq_PE "Trailer Brake Type request";
BA_ "GenSigSendType" SG_ 870 HU_TrBrakeTypeReq_PE 4;
BA_ "GenSigStartValue" SG_ 870 HU_TrBrakeTypeReq_PE 7;
BA_ "UserSigValidity" SG_ 870 HU_TrBrakeTypeReq_PE 3;
BA_ "Version" SG_ 870 HU_TrBrakeTypeReq_PE "24.07.06";
BA_ "Description" SG_ 870 AVN_MRA_Disp_Rdy "AVN status notification for ADAS_PRK

- status notification whether AVN can display on the navigation screen";
BA_ "GenSigSendType" SG_ 870 AVN_MRA_Disp_Rdy 4;
BA_ "UserSigValidity" SG_ 870 AVN_MRA_Disp_Rdy 0;
BA_ "Version" SG_ 870 AVN_MRA_Disp_Rdy "24.01.04";
BA_ "Description" SG_ 870 AVN_PRK_Func_Selected "MRA function activation button selection result feedback";
BA_ "GenSigSendType" SG_ 870 AVN_PRK_Func_Selected 4;
BA_ "UserSigValidity" SG_ 870 AVN_PRK_Func_Selected 3;
BA_ "Version" SG_ 870 AVN_PRK_Func_Selected "24.07.03";
BA_ "Description" SG_ 870 AVN_MRA_CancelInput "Information of exit button input on the navigation screen from MRA activation to control stage";
BA_ "GenSigSendType" SG_ 870 AVN_MRA_CancelInput 4;
BA_ "UserSigValidity" SG_ 870 AVN_MRA_CancelInput 0;
BA_ "Version" SG_ 870 AVN_MRA_CancelInput "24.01.04";
BA_ "GenSigSendType" SG_ 870 HU_DistanceUnit 4;
BA_ "GenSigStartValue" SG_ 870 HU_DistanceUnit 3;
BA_ "UserSigValidity" SG_ 870 HU_DistanceUnit 1;
BA_ "NetworkRequest" SG_ 870 HU_DistanceUnit 0;
BA_ "Version" SG_ 870 HU_DistanceUnit "22.06.01";
BA_ "Description" SG_ 870 HU_Scheduled_Setting "Information of scheduled update charge setting

The signal means that scheduled update charaging information send to BMS for BMS SOC control";
BA_ "GenSigSendType" SG_ 870 HU_Scheduled_Setting 4;
BA_ "UserSigValidity" SG_ 870 HU_Scheduled_Setting 3;
BA_ "Version" SG_ 870 HU_Scheduled_Setting "22.06.01";
BA_ "GenSigSendType" SG_ 870 HU_AliveStatus 4;
BA_ "GenSigStartValue" SG_ 870 HU_AliveStatus 3;
BA_ "UserSigValidity" SG_ 870 HU_AliveStatus 0;
BA_ "NetworkRequest" SG_ 870 HU_AliveStatus 0;
BA_ "Version" SG_ 870 HU_AliveStatus "22.06.01";
BA_ "Description" SG_ 870 HU_ThemeType "This signal indicates current H/Unit GUI theme value. 

 

Detail value -GUI Theme matching table, refer to attachement and ES SPEC";
BA_ "GenSigSendType" SG_ 870 HU_ThemeType 4;
BA_ "GenSigStartValue" SG_ 870 HU_ThemeType 15;
BA_ "UserSigValidity" SG_ 870 HU_ThemeType 0;
BA_ "Version" SG_ 870 HU_ThemeType "22.06.01";
BA_ "GenSigSendType" SG_ 870 HU_MicActivity 4;
BA_ "GenSigStartValue" SG_ 870 HU_MicActivity 3;
BA_ "UserSigValidity" SG_ 870 HU_MicActivity 0;
BA_ "Version" SG_ 870 HU_MicActivity "22.06.01";
BA_ "Description" SG_ 870 AVN_RSPA_ModeSelect "Signal for User's RSPAⅡ mode setting

RSPAⅡ 모드 선택 메뉴 CCP Focus 및 CCP Confirm or Touch 결과";
BA_ "GenSigSendType" SG_ 870 AVN_RSPA_ModeSelect 4;
BA_ "GenSigStartValue" SG_ 870 AVN_RSPA_ModeSelect 15;
BA_ "UserSigValidity" SG_ 870 AVN_RSPA_ModeSelect 0;
BA_ "Version" SG_ 870 AVN_RSPA_ModeSelect "23.10.01";
BA_ "GenSigSendType" SG_ 870 CF_HU_GPSFlt 4;
BA_ "GenSigStartValue" SG_ 870 CF_HU_GPSFlt 2;
BA_ "TimeoutValue" SG_ 870 CF_HU_GPSFlt "0x2";
BA_ "UserSigValidity" SG_ 870 CF_HU_GPSFlt 0;
BA_ "Version" SG_ 870 CF_HU_GPSFlt "22.06.01";
BA_ "GenSigSendType" SG_ 870 AVN_RSPA_CancelInput 4;
BA_ "UserSigValidity" SG_ 870 AVN_RSPA_CancelInput 0;
BA_ "Version" SG_ 870 AVN_RSPA_CancelInput "22.06.01";
BA_ "Description" SG_ 261 EMS_Crc7Val "The data area for CRC calculation is based on the data length (DLC) of the message DB.

The CRC shall be calculated over the entire data block (excluding the CRC bytes) including the user data, alive counter and Data ID



- CRC Polynomial (0x1021) , Ini";
BA_ "GenSigStartValue" SG_ 261 EMS_Crc7Val 65535;
BA_ "UserSigValidity" SG_ 261 EMS_Crc7Val 3;
BA_ "RoutingFactor" SG_ 261 EMS_Crc7Val 5;
BA_ "Version" SG_ 261 EMS_Crc7Val "21.09.03";
BA_ "Description" SG_ 261 HEV_AccelPdlVal "The signal is a measure of the Accelerator Pedal value.

The accelerator pedal value is determined via 2 pedal sensors, which are connected mechanically to the accelerator pedal. If the EMS-ECU recognizes that the accelerator pedal is not activated, then";
BA_ "UserSigValidity" SG_ 261 HEV_AccelPdlVal 3;
BA_ "RoutingFactor" SG_ 261 HEV_AccelPdlVal 5;
BA_ "Version" SG_ 261 HEV_AccelPdlVal "19.11.11";
BA_ "Description" SG_ 261 HEV_IndTqTar "Indicated Engine (Desired) Torque";
BA_ "UserSigValidity" SG_ 261 HEV_IndTqTar 3;
BA_ "RoutingFactor" SG_ 261 HEV_IndTqTar 5;
BA_ "Version" SG_ 261 HEV_IndTqTar "18.05.04";
BA_ "Description" SG_ 261 HEV_IndTqVal_Extd "Indicated engine torque after torque coordination(intervention)



0x0000 ~ 0x3FFF : Physical Value (0~1638.3Nm)



Depending on the engine specifications, the signals are separated as follows.

HEV Engine Only.

- HEV_IndTqVal : Kappa, Gamma, Nu Engine

";
BA_ "UserSigValidity" SG_ 261 HEV_IndTqVal_Extd 3;
BA_ "RoutingFactor" SG_ 261 HEV_IndTqVal_Extd 5;
BA_ "Version" SG_ 261 HEV_IndTqVal_Extd "23.08.03";
BA_ "Description" SG_ 261 EMS_AlvCnt7Val "For the first transmission request for a data element the counter shall be initialized with 0 and shall be incremented by 1 for every subsequent send request. 

When the counter reaches the maximum value(0xFF), then it shall restart with 0 for the next s";
BA_ "UserSigValidity" SG_ 261 EMS_AlvCnt7Val 3;
BA_ "RoutingFactor" SG_ 261 EMS_AlvCnt7Val 5;
BA_ "Version" SG_ 261 EMS_AlvCnt7Val "21.09.03";
BA_ "Description" SG_ 261 HEV_IndTqVal "Indicated engine torque after torque coordination(intervention)";
BA_ "UserSigValidity" SG_ 261 HEV_IndTqVal 3;
BA_ "RoutingFactor" SG_ 261 HEV_IndTqVal 5;
BA_ "Version" SG_ 261 HEV_IndTqVal "18.10.07";
BA_ "Description" SG_ 261 HEV_DrvTqVal "Driver's demand torque";
BA_ "UserSigValidity" SG_ 261 HEV_DrvTqVal 3;
BA_ "RoutingFactor" SG_ 261 HEV_DrvTqVal 5;
BA_ "Version" SG_ 261 HEV_DrvTqVal "18.05.04";
BA_ "Description" SG_ 261 HEV_TqStndVal "Standard value for torque scaling in torque interface";
BA_ "UserSigValidity" SG_ 261 HEV_TqStndVal 3;
BA_ "RoutingFactor" SG_ 261 HEV_TqStndVal 5;
BA_ "Version" SG_ 261 HEV_TqStndVal "18.05.04";
BA_ "Description" SG_ 261 HEV_OilDilution_IncICELoad "This signal indicates oil dilution ICE load increase mode.";
BA_ "UserSigValidity" SG_ 261 HEV_OilDilution_IncICELoad 3;
BA_ "RoutingFactor" SG_ 261 HEV_OilDilution_IncICELoad 5;
BA_ "Version" SG_ 261 HEV_OilDilution_IncICELoad "22.05.04";
BA_ "Description" SG_ 261 HEV_OilDilution_ServMode "This signal indicates oil dilution service mode.";
BA_ "UserSigValidity" SG_ 261 HEV_OilDilution_ServMode 3;
BA_ "RoutingFactor" SG_ 261 HEV_OilDilution_ServMode 5;
BA_ "Version" SG_ 261 HEV_OilDilution_ServMode "22.05.04";
BA_ "Description" SG_ 261 EMS_TqLmtSta "Status of Torque Limit.";
BA_ "UserSigValidity" SG_ 261 EMS_TqLmtSta 3;
BA_ "RoutingFactor" SG_ 261 EMS_TqLmtSta 5;
BA_ "Version" SG_ 261 EMS_TqLmtSta "23.04.02";
BA_ "Description" SG_ 261 EMS_EU7 "This signal defines if the vehicle is EU7 vehicle.";
BA_ "UserSigValidity" SG_ 261 EMS_EU7 3;
BA_ "RoutingFactor" SG_ 261 EMS_EU7 5;
BA_ "Version" SG_ 261 EMS_EU7 "23.04.02";
BA_ "Description" SG_ 261 HEV_FrctTqVal "Friction Loss Torque";
BA_ "UserSigValidity" SG_ 261 HEV_FrctTqVal 3;
BA_ "RoutingFactor" SG_ 261 HEV_FrctTqVal 5;
BA_ "Version" SG_ 261 HEV_FrctTqVal "18.10.07";
BA_ "Description" SG_ 261 HEV_EngSpdVal "Engine Speed";
BA_ "UserSigValidity" SG_ 261 HEV_EngSpdVal 3;
BA_ "RoutingFactor" SG_ 261 HEV_EngSpdVal 5;
BA_ "Version" SG_ 261 HEV_EngSpdVal "18.05.04";
BA_ "Description" SG_ 261 HEV_EngOpSta "Engine Operating State";
BA_ "UserSigValidity" SG_ 261 HEV_EngOpSta 3;
BA_ "RoutingFactor" SG_ 261 HEV_EngOpSta 5;
BA_ "Version" SG_ 261 HEV_EngOpSta "18.05.04";
BA_ "Description" SG_ 261 HEV_IntakeAirTempVal "Intake air temperature";
BA_ "UserSigValidity" SG_ 261 HEV_IntakeAirTempVal 3;
BA_ "RoutingFactor" SG_ 261 HEV_IntakeAirTempVal 5;
BA_ "Version" SG_ 261 HEV_IntakeAirTempVal "18.05.04";
BA_ "Description" SG_ 1829 GST_WPC_Byte0 "TP Index : 180";
BA_ "UsrSigPurpose" SG_ 1829 GST_WPC_Byte0 3;
BA_ "UserSigValidity" SG_ 1829 GST_WPC_Byte0 0;
BA_ "NetworkRequest" SG_ 1829 GST_WPC_Byte0 0;
BA_ "NetworkRequestHoldingTime" SG_ 1829 GST_WPC_Byte0 5000;
BA_ "Version" SG_ 1829 GST_WPC_Byte0 "21.02.04";
BA_ "Description" SG_ 1829 GST_WPC_Byte2 "TP Index : 180";
BA_ "UsrSigPurpose" SG_ 1829 GST_WPC_Byte2 3;
BA_ "UserSigValidity" SG_ 1829 GST_WPC_Byte2 0;
BA_ "NetworkRequest" SG_ 1829 GST_WPC_Byte2 0;
BA_ "NetworkRequestHoldingTime" SG_ 1829 GST_WPC_Byte2 5000;
BA_ "Version" SG_ 1829 GST_WPC_Byte2 "21.02.04";
BA_ "Description" SG_ 1829 GST_WPC_Byte3 "TP Index : 180";
BA_ "UsrSigPurpose" SG_ 1829 GST_WPC_Byte3 3;
BA_ "UserSigValidity" SG_ 1829 GST_WPC_Byte3 0;
BA_ "NetworkRequest" SG_ 1829 GST_WPC_Byte3 0;
BA_ "NetworkRequestHoldingTime" SG_ 1829 GST_WPC_Byte3 5000;
BA_ "Version" SG_ 1829 GST_WPC_Byte3 "21.02.04";
BA_ "Description" SG_ 1829 GST_WPC_Byte4 "TP Index : 180";
BA_ "UsrSigPurpose" SG_ 1829 GST_WPC_Byte4 3;
BA_ "UserSigValidity" SG_ 1829 GST_WPC_Byte4 0;
BA_ "NetworkRequest" SG_ 1829 GST_WPC_Byte4 0;
BA_ "NetworkRequestHoldingTime" SG_ 1829 GST_WPC_Byte4 5000;
BA_ "Version" SG_ 1829 GST_WPC_Byte4 "21.02.04";
BA_ "Description" SG_ 1829 GST_WPC_Byte5 "TP Index : 180";
BA_ "UsrSigPurpose" SG_ 1829 GST_WPC_Byte5 3;
BA_ "UserSigValidity" SG_ 1829 GST_WPC_Byte5 0;
BA_ "NetworkRequest" SG_ 1829 GST_WPC_Byte5 0;
BA_ "NetworkRequestHoldingTime" SG_ 1829 GST_WPC_Byte5 5000;
BA_ "Version" SG_ 1829 GST_WPC_Byte5 "21.02.04";
BA_ "Description" SG_ 1829 GST_WPC_Byte6 "TP Index : 180";
BA_ "UsrSigPurpose" SG_ 1829 GST_WPC_Byte6 3;
BA_ "UserSigValidity" SG_ 1829 GST_WPC_Byte6 0;
BA_ "NetworkRequest" SG_ 1829 GST_WPC_Byte6 0;
BA_ "NetworkRequestHoldingTime" SG_ 1829 GST_WPC_Byte6 5000;
BA_ "Version" SG_ 1829 GST_WPC_Byte6 "21.02.04";
BA_ "Description" SG_ 1829 GST_WPC_Byte7 "TP Index : 180";
BA_ "UsrSigPurpose" SG_ 1829 GST_WPC_Byte7 3;
BA_ "UserSigValidity" SG_ 1829 GST_WPC_Byte7 0;
BA_ "NetworkRequest" SG_ 1829 GST_WPC_Byte7 0;
BA_ "NetworkRequestHoldingTime" SG_ 1829 GST_WPC_Byte7 5000;
BA_ "Version" SG_ 1829 GST_WPC_Byte7 "21.02.04";
BA_ "Description" SG_ 1829 GST_WPC_Byte1 "TP Index : 180";
BA_ "UsrSigPurpose" SG_ 1829 GST_WPC_Byte1 3;
BA_ "UserSigValidity" SG_ 1829 GST_WPC_Byte1 0;
BA_ "NetworkRequest" SG_ 1829 GST_WPC_Byte1 0;
BA_ "NetworkRequestHoldingTime" SG_ 1829 GST_WPC_Byte1 5000;
BA_ "Version" SG_ 1829 GST_WPC_Byte1 "21.02.04";
BA_REL_ "GenSigTimeoutTime" BU_SG_REL_ ATS_FD SG_ 829 PwrDRClosingRRDrSta 1500;
BA_REL_ "GenSigTimeoutTime" BU_SG_REL_ ATS_FD SG_ 829 RR_DetectObj_warn 1500;
BA_REL_ "GenSigTimeoutTime" BU_SG_REL_ ATS_FD SG_ 829 RRRrDrCurtainPosition 1500;
BA_REL_ "GenSigTimeoutTime" BU_SG_REL_ ATS_FD SG_ 829 PwrDrSta_RrRt 1500;
BA_REL_ "GenSigTimeoutTime" BU_SG_REL_ ATS_FD SG_ 829 SBCM_RR_SlidePosition 1500;
BA_REL_ "GenSigTimeoutTime" BU_SG_REL_ ATS_FD SG_ 829 SBCM_RR_DoorAngle 1500;
BA_REL_ "GenSigTimeoutTime" BU_SG_REL_ BLTN_CAM_FD SG_ 829 RR_CrashUnlockCmd 1500;
BA_REL_ "GenSigTimeoutTime" BU_SG_REL_ ATS_FD SG_ 829 Warn_RrRtDrSwSta_SBCM 1500;
BA_REL_ "GenSigTimeoutTime" BU_SG_REL_ BLTN_CAM_FD SG_ 829 Warn_RrRtDrSwSta_SBCM 1500;
BA_REL_ "GenSigTimeoutTime" BU_SG_REL_ DCM_FD SG_ 829 Warn_RrRtDrSwSta_SBCM 1500;
BA_REL_ "GenSigTimeoutTime" BU_SG_REL_ GW_PSU_AST_FD SG_ 829 Warn_RrRtDrSwSta_SBCM 1500;
BA_REL_ "GenSigTimeoutTime" BU_SG_REL_ GW_PSU_RR_FD SG_ 829 Warn_RrRtDrSwSta_SBCM 1500;
BA_REL_ "GenSigTimeoutTime" BU_SG_REL_ PSB_FD SG_ 829 Warn_RrRtDrSwSta_SBCM 1500;
BA_REL_ "GenSigTimeoutTime" BU_SG_REL_ RWPC_FD SG_ 829 Warn_RrRtDrSwSta_SBCM 1500;
BA_REL_ "GenSigTimeoutTime" BU_SG_REL_ WPC2_FD SG_ 829 Warn_RrRtDrSwSta_SBCM 1500;
BA_REL_ "GenSigTimeoutTime" BU_SG_REL_ WPC_FD SG_ 829 Warn_RrRtDrSwSta_SBCM 1500;
BA_REL_ "GenSigTimeoutTime" BU_SG_REL_ ATS_FD SG_ 829 DoorLock_RrRtDrUnLkSta_SBCM 1500;
BA_REL_ "GenSigTimeoutTime" BU_SG_REL_ FCS_FD SG_ 829 DoorLock_RrRtDrUnLkSta_SBCM 1500;
BA_REL_ "GenSigTimeoutTime" BU_SG_REL_ ATS_FD SG_ 829 RR_SEAActivated 1500;
BA_REL_ "GenSigTimeoutTime" BU_SG_REL_ ATS_FD SG_ 829 RR_SEAWarn 1500;
BA_REL_ "GenSigTimeoutTime" BU_SG_REL_ ATS_FD SG_ 829 RR_SWFailAlarm 1500;
BA_REL_ "GenSigTimeoutTime" BU_SG_REL_ GW_PSU_DRV_FD SG_ 1025 BDC_FD_SMK_Crc2Val 1500;
BA_REL_ "GenSigTimeoutTime" BU_SG_REL_ GW_PSU_DRV_FD SG_ 1025 RSPA_ModSta_SMK 1500;
BA_REL_ "GenSigTimeoutTime" BU_SG_REL_ GW_PSU_DRV_FD SG_ 1025 BDC_FD_SMK_AlvCnt2Val 1500;
BA_REL_ "GenSigTimeoutTime" BU_SG_REL_ GW_PSU_AST_FD SG_ 1025 SMK_AuthSta 1500;
BA_REL_ "GenSigTimeoutTime" BU_SG_REL_ GW_PSU_DRV_FD SG_ 1025 SMK_AuthSta 1500;
BA_REL_ "GenSigTimeoutTime" BU_SG_REL_ PSB_FD SG_ 1025 SMK_AuthSta 1500;
BA_REL_ "GenSigTimeoutTime" BU_SG_REL_ ATS_FD SG_ 1025 SMK_TlEngRunSta 1500;
BA_REL_ "GenSigTimeoutTime" BU_SG_REL_ GW_PSU_3RD_FD SG_ 1025 SMK_TlEngRunSta 1500;
BA_REL_ "GenSigTimeoutTime" BU_SG_REL_ GW_PSU_AST_FD SG_ 1025 SMK_TlEngRunSta 1500;
BA_REL_ "GenSigTimeoutTime" BU_SG_REL_ GW_PSU_DRV_FD SG_ 1025 SMK_TlEngRunSta 1500;
BA_REL_ "GenSigTimeoutTime" BU_SG_REL_ GW_PSU_RL_FD SG_ 1025 SMK_TlEngRunSta 1500;
BA_REL_ "GenSigTimeoutTime" BU_SG_REL_ GW_PSU_RR_FD SG_ 1025 SMK_TlEngRunSta 1500;
BA_REL_ "GenSigTimeoutTime" BU_SG_REL_ GW_SAU_DRV_FD SG_ 1025 SMK_TlEngRunSta 1500;
BA_REL_ "GenSigTimeoutTime" BU_SG_REL_ SHVU_3RD_FD SG_ 1025 SMK_TlEngRunSta 1500;
BA_REL_ "GenSigTimeoutTime" BU_SG_REL_ SHVU_CCS_FD SG_ 1025 SMK_TlEngRunSta 1500;
BA_REL_ "GenSigTimeoutTime" BU_SG_REL_ SHVU_FRNT_FD SG_ 1025 SMK_TlEngRunSta 1500;
BA_REL_ "GenSigTimeoutTime" BU_SG_REL_ SHVU_REAR_FD SG_ 1025 SMK_TlEngRunSta 1500;
BA_REL_ "GenSigTimeoutTime" BU_SG_REL_ SHVU_RL_FD SG_ 1025 SMK_TlEngRunSta 1500;
BA_REL_ "GenSigTimeoutTime" BU_SG_REL_ SHVU_RR_FD SG_ 1025 SMK_TlEngRunSta 1500;
BA_REL_ "GenSigTimeoutTime" BU_SG_REL_ ATS_FD SG_ 1025 SMK_TlCrnkModSta 1500;
BA_REL_ "GenSigTimeoutTime" BU_SG_REL_ GW_PSU_AST_FD SG_ 1025 SMK_TlCrnkModSta 1500;
BA_REL_ "GenSigTimeoutTime" BU_SG_REL_ GW_PSU_DRV_FD SG_ 1025 SMK_TlCrnkModSta 1500;
BA_REL_ "GenSigTimeoutTime" BU_SG_REL_ GW_SAU_DRV_FD SG_ 1025 SMK_TlCrnkModSta 1500;
BA_REL_ "GenSigTimeoutTime" BU_SG_REL_ SCM_FD SG_ 1025 SMK_TlCrnkModSta 1500;
BA_REL_ "GenSigTimeoutTime" BU_SG_REL_ RWPC_FD SG_ 1025 LFAnt_SrchSta 1500;
BA_REL_ "GenSigTimeoutTime" BU_SG_REL_ WPC2_FD SG_ 1025 LFAnt_SrchSta 1500;
BA_REL_ "GenSigTimeoutTime" BU_SG_REL_ WPC_FD SG_ 1025 LFAnt_SrchSta 1500;
BA_REL_ "GenSigTimeoutTime" BU_SG_REL_ ATS_FD SG_ 830 PwrDRClosingRLDrSta 1500;
BA_REL_ "GenSigTimeoutTime" BU_SG_REL_ ATS_FD SG_ 830 RL_DetectObj_warn 1500;
BA_REL_ "GenSigTimeoutTime" BU_SG_REL_ ATS_FD SG_ 830 RLRrDrCurtainPosition 1500;
BA_REL_ "GenSigTimeoutTime" BU_SG_REL_ ATS_FD SG_ 830 RDC_TypeOption 1500;
BA_REL_ "GenSigTimeoutTime" BU_SG_REL_ ATS_FD SG_ 830 PwrDrSta_RrLt 1500;
BA_REL_ "GenSigTimeoutTime" BU_SG_REL_ ATS_FD SG_ 830 SBCM_RL_SlidePosition 1500;
BA_REL_ "GenSigTimeoutTime" BU_SG_REL_ ATS_FD SG_ 830 SBCM_RL_DoorAngle 1500;
BA_REL_ "GenSigTimeoutTime" BU_SG_REL_ BLTN_CAM_FD SG_ 830 RL_CrashUnlockCmd 1500;
BA_REL_ "GenSigTimeoutTime" BU_SG_REL_ ATS_FD SG_ 830 Warn_RrLftDrSwSta_SBCM 1500;
BA_REL_ "GenSigTimeoutTime" BU_SG_REL_ BLTN_CAM_FD SG_ 830 Warn_RrLftDrSwSta_SBCM 1500;
BA_REL_ "GenSigTimeoutTime" BU_SG_REL_ DCM_FD SG_ 830 Warn_RrLftDrSwSta_SBCM 1500;
BA_REL_ "GenSigTimeoutTime" BU_SG_REL_ GW_PSU_AST_FD SG_ 830 Warn_RrLftDrSwSta_SBCM 1500;
BA_REL_ "GenSigTimeoutTime" BU_SG_REL_ PSB_FD SG_ 830 Warn_RrLftDrSwSta_SBCM 1500;
BA_REL_ "GenSigTimeoutTime" BU_SG_REL_ RWPC_FD SG_ 830 Warn_RrLftDrSwSta_SBCM 1500;
BA_REL_ "GenSigTimeoutTime" BU_SG_REL_ WPC2_FD SG_ 830 Warn_RrLftDrSwSta_SBCM 1500;
BA_REL_ "GenSigTimeoutTime" BU_SG_REL_ WPC_FD SG_ 830 Warn_RrLftDrSwSta_SBCM 1500;
BA_REL_ "GenSigTimeoutTime" BU_SG_REL_ ATS_FD SG_ 830 DoorLock_RrLftDrUnLkSta_SBCM 1500;
BA_REL_ "GenSigTimeoutTime" BU_SG_REL_ FCS_FD SG_ 830 DoorLock_RrLftDrUnLkSta_SBCM 1500;
BA_REL_ "GenSigTimeoutTime" BU_SG_REL_ ATS_FD SG_ 830 RL_SEAActivated 1500;
BA_REL_ "GenSigTimeoutTime" BU_SG_REL_ ATS_FD SG_ 830 RL_SEAWarn 1500;
BA_REL_ "GenSigTimeoutTime" BU_SG_REL_ ATS_FD SG_ 830 RL_SWFailAlarm 1500;
BA_REL_ "GenSigTimeoutTime" BU_SG_REL_ CGW_CCU SG_ 1837 WPC_GST_Byte0 0;
BA_REL_ "GenSigTimeoutTime" BU_SG_REL_ CGW_CCU SG_ 1837 WPC_GST_Byte2 0;
BA_REL_ "GenSigTimeoutTime" BU_SG_REL_ CGW_CCU SG_ 1837 WPC_GST_Byte3 0;
BA_REL_ "GenSigTimeoutTime" BU_SG_REL_ CGW_CCU SG_ 1837 WPC_GST_Byte4 0;
BA_REL_ "GenSigTimeoutTime" BU_SG_REL_ CGW_CCU SG_ 1837 WPC_GST_Byte5 0;
BA_REL_ "GenSigTimeoutTime" BU_SG_REL_ CGW_CCU SG_ 1837 WPC_GST_Byte6 0;
BA_REL_ "GenSigTimeoutTime" BU_SG_REL_ CGW_CCU SG_ 1837 WPC_GST_Byte7 0;
BA_REL_ "GenSigTimeoutTime" BU_SG_REL_ CGW_CCU SG_ 1837 WPC_GST_Byte1 0;
BA_REL_ "GenSigTimeoutTime" BU_SG_REL_ GW_PSU_DRV_FD SG_ 1233 CLU_Crc5Val 0;
BA_REL_ "GenSigTimeoutTime" BU_SG_REL_ GW_PSU_DRV_FD SG_ 1233 CLU_AlvCnt5Val 0;
BA_REL_ "GenSigTimeoutTime" BU_SG_REL_ GW_PSU_DRV_FD SG_ 1233 USM_StaRst1Req 0;
BA_REL_ "GenSigTimeoutTime" BU_SG_REL_ WPC2_FD SG_ 1233 USM_StaRst1Req 0;
BA_REL_ "GenSigTimeoutTime" BU_SG_REL_ WPC_FD SG_ 1233 USM_StaRst1Req 0;
BA_REL_ "GenSigTimeoutTime" BU_SG_REL_ GW_PSU_DRV_FD SG_ 870 HU_GW_Crc3Val 1500;
BA_REL_ "GenSigTimeoutTime" BU_SG_REL_ BLTN_CAM_FD SG_ 870 CF_AVN_ProfileIDRValue 1500;
BA_REL_ "GenSigTimeoutTime" BU_SG_REL_ GW_PSU_DRV_FD SG_ 870 CF_AVN_ProfileIDRValue 1500;
BA_REL_ "GenSigTimeoutTime" BU_SG_REL_ GW_SAU_DRV_FD SG_ 870 CF_AVN_ProfileIDRValue 1500;
BA_REL_ "GenSigTimeoutTime" BU_SG_REL_ RCM_FD SG_ 870 CF_AVN_ProfileIDRValue 1500;
BA_REL_ "GenSigTimeoutTime" BU_SG_REL_ RWPC_FD SG_ 870 CF_AVN_ProfileIDRValue 1500;
BA_REL_ "GenSigTimeoutTime" BU_SG_REL_ SGU_FD SG_ 870 CF_AVN_ProfileIDRValue 1500;
BA_REL_ "GenSigTimeoutTime" BU_SG_REL_ WPC2_FD SG_ 870 CF_AVN_ProfileIDRValue 1500;
BA_REL_ "GenSigTimeoutTime" BU_SG_REL_ WPC_FD SG_ 870 CF_AVN_ProfileIDRValue 1500;
BA_REL_ "GenSigTimeoutTime" BU_SG_REL_ GW_PSU_AST_FD SG_ 870 HU_RTCCheck 1500;
BA_REL_ "GenSigTimeoutTime" BU_SG_REL_ GW_PSU_DRV_FD SG_ 870 HU_GW_AlvCnt3Val 1500;
BA_REL_ "GenSigTimeoutTime" BU_SG_REL_ ATS_FD SG_ 870 HU_ThemeType 1500;
BA_REL_ "GenSigTimeoutTime" BU_SG_REL_ BLTN_CAM_FD SG_ 870 HU_ThemeType 1500;
BA_REL_ "GenSigTimeoutTime" BU_SG_REL_ WPC_FD SG_ 1829 GST_WPC_Byte0 0;
BA_REL_ "GenSigTimeoutTime" BU_SG_REL_ WPC_FD SG_ 1829 GST_WPC_Byte2 0;
BA_REL_ "GenSigTimeoutTime" BU_SG_REL_ WPC_FD SG_ 1829 GST_WPC_Byte3 0;
BA_REL_ "GenSigTimeoutTime" BU_SG_REL_ WPC_FD SG_ 1829 GST_WPC_Byte4 0;
BA_REL_ "GenSigTimeoutTime" BU_SG_REL_ WPC_FD SG_ 1829 GST_WPC_Byte5 0;
BA_REL_ "GenSigTimeoutTime" BU_SG_REL_ WPC_FD SG_ 1829 GST_WPC_Byte6 0;
BA_REL_ "GenSigTimeoutTime" BU_SG_REL_ WPC_FD SG_ 1829 GST_WPC_Byte7 0;
BA_REL_ "GenSigTimeoutTime" BU_SG_REL_ WPC_FD SG_ 1829 GST_WPC_Byte1 0;
VAL_ 829 SBCM_RR_FD_Crc1Val 0 "0x0x0~0xFFFF:CRCValue" 65535 "0x0x0~0xFFFF:CRCValue" ;
VAL_ 829 USM_RRGhostDoorSta 0 "Default" 1 "Off" 2 "On" 3 "RESERVED" ;
VAL_ 829 DoorLock_PDSLkSwSta_RR 0 "Lock" 1 "Unlock" 2 "RESERVED" 3 "Error Indicator" ;
VAL_ 829 PDS_TypeOption_RR 0 "Off" 1 "On" 2 "RESERVED" 3 "Error Indicator" ;
VAL_ 829 RR_CrashMRActAlarm 0 "Off" 1 "On" 2 "RESERVED" 3 "Error Indicator" ;
VAL_ 829 PwrDRBuzzerOut_RR 0 "OFF" 1 "Open" 2 "Close" 3 "Warning" ;
VAL_ 829 PwrDRClosingRRDrSta 0 "Default" 1 "Close" 2 "Open" 3 "Stop(during Close)" 4 "Stop(during Open)" 5 "RESERVED" 6 "RESERVED" 7 "Invalid" ;
VAL_ 829 AFH_RR_FldUnfldSta 0 "Invalid" 1 "Fold" 2 "Unfold" 3 "Inprogress" ;
VAL_ 829 SBCM_RR_FD_AlvCnt1Val 0 "0x0x0~0xFF:AlvCntValue" 255 "0x0x0~0xFF:AlvCntValue" ;
VAL_ 829 DoorLock_RrRtLkOutSta_SBCM 0 "Off" 1 "On" 2 "Not Used" 3 "Error Indicator" ;
VAL_ 829 RrRt_DrLkRetryFail_SBCM 0 "Normal" 1 "Fail" 2 "RESERVED" 3 "RESERVED" ;
VAL_ 829 RR_DetectObj_warn 0 "Detect Warning OFF" 1 "Detect Warning ON" 2 "RESERVED" 3 "RESERVED" ;
VAL_ 829 RRRrDrCurtainPosition 0 "Unkown" 1 "Bottom" 2 "Mid" 3 "Top" ;
VAL_ 829 RRRrDrCurtainDownInitState 0 "Decalibrated" 1 "Calibrated" 2 "RESERVED" 3 "Error Indicator" ;
VAL_ 829 PwrDrSta_RrRt 0 "Unavailable" 1 "Available" 2 "RESERVED" 3 "Error Indicator" ;
VAL_ 829 PwrDRBuzzerOut_RR_New 0 "OFF" 1 "Open" 2 "Close" 3 "Warning1" 4 "Warning2" ;
VAL_ 829 SBCM_RR_SlidePosition 0 "0x0x0~0x64:0% - 100%" 100 "0x0x0~0x64:0% - 100%" 101 "0x65~0xFE:RESERVED" 254 "0x65~0xFE:RESERVED" 255 "Unknown" ;
VAL_ 829 SBCM_RR_DoorAngle 0 "0° - 90°" 1 "0° - 90°" 2 "0° - 90°" 3 "0° - 90°" 4 "0° - 90°" 5 "0° - 90°" 6 "0° - 90°" 7 "0° - 90°" 8 "0° - 90°" 9 "0° - 90°" 10 "0° - 90°" 11 "0° - 90°" 12 "0° - 90°" 13 "0° - 90°" 14 "0° - 90°" 15 "0° - 90°" 16 "0° - 90°" 17 "0° - 90°" 18 "0° - 90°" 19 "0° - 90°" 20 "0° - 90°" 21 "0° - 90°" 22 "0° - 90°" 23 "0° - 90°" 24 "0° - 90°" 25 "0° - 90°" 26 "0° - 90°" 27 "0° - 90°" 28 "0° - 90°" 29 "0° - 90°" 30 "0° - 90°" 31 "0° - 90°" 32 "0° - 90°" 33 "0° - 90°" 34 "0° - 90°" 35 "0° - 90°" 36 "0° - 90°" 37 "0° - 90°" 38 "0° - 90°" 39 "0° - 90°" 40 "0° - 90°" 41 "0° - 90°" 42 "0° - 90°" 43 "0° - 90°" 44 "0° - 90°" 45 "0° - 90°" 46 "0° - 90°" 47 "0° - 90°" 48 "0° - 90°" 49 "0° - 90°" 50 "0° - 90°" 51 "0° - 90°" 52 "0° - 90°" 53 "0° - 90°" 54 "0° - 90°" 55 "0° - 90°" 56 "0° - 90°" 57 "0° - 90°" 58 "0° - 90°" 59 "0° - 90°" 60 "0° - 90°" 61 "0° - 90°" 62 "0° - 90°" 63 "0° - 90°" 64 "0° - 90°" 65 "0° - 90°" 66 "0° - 90°" 67 "0° - 90°" 68 "0° - 90°" 69 "0° - 90°" 70 "0° - 90°" 71 "0° - 90°" 72 "0° - 90°" 73 "0° - 90°" 74 "0° - 90°" 75 "0° - 90°" 76 "0° - 90°" 77 "0° - 90°" 78 "0° - 90°" 79 "0° - 90°" 80 "0° - 90°" 81 "0° - 90°" 82 "0° - 90°" 83 "0° - 90°" 84 "0° - 90°" 85 "0° - 90°" 86 "0° - 90°" 87 "0° - 90°" 88 "0° - 90°" 89 "0° - 90°" 90 "0° - 90°" 91 "Invalid" 92 "Invalid" 93 "Invalid" 94 "Invalid" 95 "Invalid" 96 "Invalid" 97 "Invalid" 98 "Invalid" 99 "Invalid" 100 "Unknown" 101 "Invalid" 102 "Invalid" 103 "Invalid" 104 "Invalid" 105 "Invalid" 106 "Invalid" 107 "Invalid" 108 "Invalid" 109 "Invalid" 110 "Invalid" 111 "Invalid" 112 "Invalid" 113 "Invalid" 114 "Invalid" 115 "Invalid" 116 "Invalid" 117 "Invalid" 118 "Invalid" 119 "Invalid" 120 "Invalid" 121 "Invalid" 122 "Invalid" 123 "Invalid" 124 "Invalid" 125 "Invalid" 126 "Invalid" 127 "Invalid" ;
VAL_ 829 RRDoorPushAlarm 0 "Off" 1 "On" 2 "RESERVED" 3 "Error Indicator" ;
VAL_ 829 RR_CrashUnlockCmd 0 "Off" 1 "Unlock (Crash)" ;
VAL_ 829 Warn_RrRtDrSwSta_SBCM 0 "Close" 1 "Open" 2 "RESERVED" 3 "Error Indicator" ;
VAL_ 829 DoorLock_RrRtDrUnLkSta_SBCM 0 "Lock" 1 "Unlock" 2 "RESERVED" 3 "Error Indicator" ;
VAL_ 829 RR_SEAActivated 0 "InActivated" 1 "Activated" 2 "RESERVED" 3 "Error Indicator" ;
VAL_ 829 RR_SEAWarn 0 "SEA Right Warning OFF" 1 "SEA Right Warning ON" 2 "RESERVED" 3 "RESERVED" ;
VAL_ 829 RR_SEWWarn 0 "SEW Right Warning OFF" 1 "SEW Right Warning ON" 2 "RESERVED" 3 "RESERVED" ;
VAL_ 829 RR_ReleaseWarn 0 "Release Warning OFF" 1 "Release Warning ON" 2 "RESERVED" 3 "RESERVED" ;
VAL_ 829 RR_SWFailAlarm 0 "Off" 1 "On" 2 "RESERVED" 3 "Error Indicator" ;
VAL_ 829 RR_ChildLock_ActnFlSta 0 "OK" 1 "Failed" 2 "RESERVED" 3 "Error Indicator" ;
VAL_ 829 RR_MRActivationAlarm 0 "Off" 1 "On" 2 "RESERVED" 3 "Error Indicator" ;
VAL_ 829 RR_ChildLock_Status 0 "ChildLock On" 1 "ChildLock Off" 2 "RESERVED" 3 "RESERVED" ;
VAL_ 1025 BDC_FD_SMK_Crc2Val 0 "0x0x0~0xFFFF:CRCValue" 65535 "0x0x0~0xFFFF:CRCValue" ;
VAL_ 1025 SMK_RpmLoByteVal 0 "0x0x0~0xFF:RPM Low Byte Value" 255 "0x0x0~0xFF:RPM Low Byte Value" ;
VAL_ 1025 SMK_VehSpdDrctVal 0 "0x0x0~0xFF:Vehicle Speed Direct Value" 255 "0x0x0~0xFF:Vehicle Speed Direct Value" ;
VAL_ 1025 Fob_BattStaInfo 0 "Normal or No Information" 1 "Recent used FOB is in discharge warning voltage level" 2 "Not Used" 3 "Error Indicator" ;
VAL_ 1025 Fob_FoundDrvWlcmArea 0 "Default" 1 "Fob Found(Drv)" 2 "Not Used" 3 "Error Indicator" ;
VAL_ 1025 Fob_FoundAsstWlcmArea 0 "Default" 1 "Fob Found(Ast)" 2 "Not Used" 3 "Error Indicator" ;
VAL_ 1025 Fob_FoundExtrnlArea 0 "Default" 1 "Can't recognize" 2 "Fob recognized" 3 "Search in progress" ;
VAL_ 1025 Fob_FoundIntArea 0 "Default" 1 "Can't recognize" 2 "Fob recognized" 3 "Search in progress" ;
VAL_ 1025 Fob_LearntSta 0 "Learnt" 1 "Virgin" 2 "Not Used" 3 "Error Indicator" ;
VAL_ 1025 RSPA_LearntSta 0 "Non-RSPA Learnt" 1 "RSPA Learnt" 2 "Reserved" 3 "Error Indicator" ;
VAL_ 1025 RSPA_RFSigErrSta 0 "Default" 1 "Signal Invalid" 2 "In Progress" 3 "Error Indicator" ;
VAL_ 1025 RSPA_CanErrSta 0 "Default" 1 "RSPA CAN Error" 2 "Not Used" 3 "Error Indicator" ;
VAL_ 1025 RSPA_ModSta_SMK 0 "RSPA Off" 1 "RSPA On" 2 "Reserved" 3 "Reserved" 4 "Reserved" 5 "Reseved" 6 "Not Used" 7 "Error Indicator" ;
VAL_ 1025 RSPA_FobBattSta 0 "Normal" 1 "Low Battery" 2 "Reserved" 3 "Reserved" 4 "Reserved" 5 "Reseved" 6 "Not Used" 7 "Error Indicator" ;
VAL_ 1025 Fob_BtnReleasedSta 0 "Default" 1 "Butten Released" 2 "Not used" 3 "Error Indicator" ;
VAL_ 1025 Fob_FoundWlcmArea 0 "Default (Off)" 1 "Fob Found" 2 "Not Used" 3 "Error Indicator" ;
VAL_ 1025 USM_WALModSta 0 "Default" 1 "WAL Off" 2 "WAL On" 3 "Invalid" 4 "Reserved" 5 "Reseved" 6 "Not Used" 7 "Error Indicator" ;
VAL_ 1025 USM_SmrtTrnkTlgtModSta 0 "Default Value" 1 "HandsFree Off" 2 "HandsFree On" 3 "Reserved" 4 "Invalid" 5 "Reserved" 6 "Not Used" 7 "Error Indicator" ;
VAL_ 1025 USM_SAUModSta 0 "Default" 1 "Approach Unlock Off" 2 "Approach Unlock On" 3 "Invalid" 4 "RESERVED" 5 "RESERVED" 6 "RESERVED" 7 "Error Indicator" ;
VAL_ 1025 SMK_RLHndLkSnsrSta 0 "Off" 1 "On" 2 "Not Used" 3 "Error Indicator" ;
VAL_ 1025 BDC_FD_SMK_AlvCnt2Val 0 "0x0x0~0xFF:AlvCntValue" 255 "0x0x0~0xFF:AlvCntValue" ;
VAL_ 1025 SMK_RLDrHndUnLkSnsrSta 0 "Off" 1 "On" 2 "Not Used" 3 "Error Indicator" ;
VAL_ 1025 SMK_RRDrHndLkSnsrSta 0 "Off" 1 "On" 2 "Not Used" 3 "Error Indicator" ;
VAL_ 1025 SMK_RRDrHndUnLkSnsrSta 0 "Off" 1 "On" 2 "Not Used" 3 "Error Indicator" ;
VAL_ 1025 Fob_FoundCabinArea 0 "Default" 1 "Fob Found" 2 "No Fob Found" 3 "Error Indicator" ;
VAL_ 1025 SMK_ResultRmtStrt 0 "Off" 1 "Decryption Fail" 2 "Tele Engine Running Success" 3 "Tele Engine Running Fail" 4 "Tele Off Success" 5 "Tele Off Fail" 6 "Not Used" 7 "Error Indicator" ;
VAL_ 1025 SMK_EncryptTeleOptSta 0 "Off" 1 "Remote Start Encryption Applied" 2 "Remote Start Encryption Notapplied" 3 "Error Indicator" ;
VAL_ 1025 Auth_ISKLearnSta2 0 "Default(Normal)" 1 "Virgin" 2 "Learning" 3 "Learnt" 4 "Neutralizing" 5 "Neutralized" 6 "RESERVED" 7 "Invalid" ;
VAL_ 1025 Auth_ISKLearnSta 0 "Default(Normal)" 1 "Learning" 2 "Invalid" 3 "Neutral" 4 "Reserved" 5 "Reserved" 6 "Not used" 7 "Error Indicator" ;
VAL_ 1025 SMK_TlPwrOnSta 0 "Default" 1 "Power On" 2 "Not Used" 3 "Error Indicator" ;
VAL_ 1025 Fob_FoundForChargingDoor 0 "Default" 1 "Fob Found" 2 "No Fob Found" 3 "Error Indicator" ;
VAL_ 1025 SSB_StrtStpBtnSw1Sta 0 "Released" 1 "Pressed" 2 "Not Used" 3 "Error Indicator" ;
VAL_ 1025 SSB_StrtStpBtnSw2Sta 0 "Released" 1 "Pressed" 2 "Not Used" 3 "Error Indicator" ;
VAL_ 1025 SMK_AuthSta 0 "No Auth" 1 "Preauthentication" 2 "Authentication" 3 "Fast Restart" 4 "Reserved" 5 "Reseved" 6 "Not Used" 7 "Error Indicator" ;
VAL_ 1025 SMK_TlPwrOnOpt 0 "Not Applied" 1 "Applied" ;
VAL_ 1025 SMK_Ign1InSta 0 "IGN1 Off" 1 "IGN1 On" 2 "Not Used" 3 "Error Indicator" ;
VAL_ 1025 SMK_Ign1RlySta 0 "Off" 1 "On" 2 "Not Used" 3 "Error Indicator" ;
VAL_ 1025 SMK_Ign2InSta 0 "IGN2 Off" 1 "IGN2 On" 2 "Not Used" 3 "Error Indicator" ;
VAL_ 1025 SMK_Ign2RlySta 0 "Off" 1 "On" 2 "Not Used" 3 "Error Indicator" ;
VAL_ 1025 SMK_StrtFdbckSta 0 "Off" 1 "On" 2 "Not Used" 3 "Error Indicator" ;
VAL_ 1025 SMK_StrtrRlyOutSta 0 "Starter Relay Output Off" 1 "Starter Relay Output On" 2 "Not Used" 3 "Error Indicator" ;
VAL_ 1025 SMK_AccInSta 0 "ACC OFF" 1 "ACC ON" 2 "Not Used" 3 "Error Indicator" ;
VAL_ 1025 SMK_AccRlySta 0 "Off" 1 "On" 2 "Not Used" 3 "Error Indicator" ;
VAL_ 1025 SMK_CLUAccIndOnReq 0 "Cluster ACC Indicator Off" 1 "Cluster ACC Indicator On" 2 "Not Used" 3 "Error Indicator" ;
VAL_ 1025 SMK_VDModeActSta 0 "Off" 1 "On" 2 "Not Used" 3 "Error Indicator" ;
VAL_ 1025 SMK_SCULckUnlckSta 0 "Default" 1 "Lock" 2 "Unlock" 3 "Error Indicator" ;
VAL_ 1025 SMK_TlEngRunSta 0 "Off" 1 "Tele Engine Running" 2 "Not Used" 3 "Error Indicator" ;
VAL_ 1025 SMK_TlCrnkModSta 0 "Normal Mode" 1 "Tele Cranking Mode" 2 "Not Used" 3 "Error Indicator" ;
VAL_ 1025 SMK_RmtKeyEngRunSta 0 "Off" 1 "Remote Key Engine Running" 2 "Not Used" 3 "Error Indicator" ;
VAL_ 1025 SMK_RmtKeyCrnkModSta 0 "Normal Mode" 1 "Remote Key Cranking Mode" 2 "Not Used" 3 "Error Indicator" ;
VAL_ 1025 SMK_AsstTgglBtnSta 0 "Off" 1 "On" 2 "Not Used" 3 "Error Indicator" ;
VAL_ 1025 SMK_DrvTglBtnSta 0 "Off" 1 "On" 2 "Not Used" 3 "Error Indicator" ;
VAL_ 1025 SMK_RrLftTglBtnSta 0 "Off" 1 "On" 2 "Not Used" 3 "Error Indicator" ;
VAL_ 1025 SMK_RrRtTglBtnSta 0 "Off" 1 "On" 2 "Not Used" 3 "Error Indicator" ;
VAL_ 1025 SMK_TgglBtnStuckSta 0 "Normal" 1 "Toggle Stuck" 2 "Not Used" 3 "Error Indicator" ;
VAL_ 1025 SMK_AsstDrHndUnLkSnsrSta 0 "Off" 1 "On" 2 "Not Used" 3 "Error Indicator" ;
VAL_ 1025 SMK_BrkSwSta 0 "Off" 1 "On" 2 "Not Used" 3 "Error Indicator" ;
VAL_ 1025 SMK_GearPosPSwSta 0 "Off" 1 "On" 2 "Not Used" 3 "Error Indicator" ;
VAL_ 1025 SMK_CltchIgnLkSwSta 0 "Clutch Ign SW Off" 1 "Clutch Ign SW On(Step on the clutch)" 2 "Not Used" 3 "Error Indicator" ;
VAL_ 1025 SMK_DrvDrHndLkSnsrSta 0 "Off" 1 "On" 2 "Not Used" 3 "Error Indicator" ;
VAL_ 1025 SMK_DrvDrHndUnLkSnsrSta 0 "Off" 1 "On" 2 "Not Used" 3 "Error Indicator" ;
VAL_ 1025 SMK_AsstDrHndLkSnsrSta 0 "Off" 1 "On" 2 "Not Used" 3 "Error Indicator" ;
VAL_ 1025 LFAnt_FltSta 0 "Normal" 1 "Fault" 2 "Not Used" 3 "Error Indicator" ;
VAL_ 1025 LFAnt_SrchSta 0 "Off" 1 "On (LF Searching)" 2 "Not Used" 3 "Error Indicator" ;
VAL_ 1025 Lamp_HzrdBlnkngSta 0 "Off" 1 "Single Blinking" 2 "Double Blinking" 3 "Reserved" 4 "Reserved" 5 "Reseved" 6 "Not Used" 7 "Error Indicator" ;
VAL_ 1025 Lamp_SmrtWlcmLtOnReq 0 "Off" 1 "On" 2 "Not Used" 3 "Error Indicator" ;
VAL_ 1025 SMK_RpmHiByteVal 0 "0x0x0~0xFF:RPM High Byte Value" 255 "0x0x0~0xFF:RPM High Byte Value" ;
VAL_ 830 SBCM_RL_FD_Crc1Val 0 "0x0x0~0xFFFF:CRCValue" 65535 "0x0x0~0xFFFF:CRCValue" ;
VAL_ 830 USM_RLGhostDoorSta 0 "Default" 1 "Off" 2 "On" 3 "RESERVED" ;
VAL_ 830 DoorLock_PDSLkSwSta_RL 0 "Lock" 1 "Unlock" 2 "RESERVED" 3 "Error Indicator" ;
VAL_ 830 PDS_TypeOption_RL 0 "Off" 1 "On" 2 "RESERVED" 3 "Error Indicator" ;
VAL_ 830 RL_CrashMRActAlarm 0 "Off" 1 "On" 2 "RESERVED" 3 "Error Indicator" ;
VAL_ 830 PwrDRBuzzerOut_RL 0 "OFF" 1 "Open" 2 "Close" 3 "Warning" ;
VAL_ 830 PwrDRClosingRLDrSta 0 "Default" 1 "Close" 2 "Open" 3 "Stop(during Close)" 4 "Stop(during Open)" 5 "RESERVED" 6 "RESERVED" 7 "Invalid" ;
VAL_ 830 AFH_RL_FldUnfldSta 0 "Invalid" 1 "Fold" 2 "Unfold" 3 "Inprogress" ;
VAL_ 830 SBCM_RL_FD_AlvCnt1Val 0 "0x0x0~0xFF:AlvCntValue" 255 "0x0x0~0xFF:AlvCntValue" ;
VAL_ 830 DoorLock_RrLtLkOutSta_SBCM 0 "Off" 1 "On" 2 "Not Used" 3 "Error Indicator" ;
VAL_ 830 RrLt_DrLkRetryFail_SBCM 0 "Normal" 1 "Fail" 2 "RESERVED" 3 "RESERVED" ;
VAL_ 830 RL_DetectObj_warn 0 "Detect Warning OFF" 1 "Detect Warning ON" 2 "RESERVED" 3 "RESERVED" ;
VAL_ 830 RLRrDrCurtainPosition 0 "Unkown" 1 "Bottom" 2 "Mid" 3 "Top" ;
VAL_ 830 RDC_TypeOption 0 "Off" 1 "On" 2 "RESERVED" 3 "Error Indicator" ;
VAL_ 830 RLRrDrCurtainDownInitState 0 "Decalibrated" 1 "Calibrated" 2 "RESERVED" 3 "Error Indicator" ;
VAL_ 830 PwrDRBuzzerOut_RL_New 0 "OFF" 1 "Open" 2 "Close" 3 "Warning1" 4 "Warning2" ;
VAL_ 830 PwrDrSta_RrLt 0 "Unavailable" 1 "Available" 2 "RESERVED" 3 "Error Indicator" ;
VAL_ 830 SBCM_RL_SlidePosition 0 "0x0x0~0x64:0% - 100%" 100 "0x0x0~0x64:0% - 100%" 101 "0x65~0xFE:RESERVED" 254 "0x65~0xFE:RESERVED" 255 "Unknown" ;
VAL_ 830 SBCM_RL_DoorAngle 0 "0° - 90°" 1 "0° - 90°" 2 "0° - 90°" 3 "0° - 90°" 4 "0° - 90°" 5 "0° - 90°" 6 "0° - 90°" 7 "0° - 90°" 8 "0° - 90°" 9 "0° - 90°" 10 "0° - 90°" 11 "0° - 90°" 12 "0° - 90°" 13 "0° - 90°" 14 "0° - 90°" 15 "0° - 90°" 16 "0° - 90°" 17 "0° - 90°" 18 "0° - 90°" 19 "0° - 90°" 20 "0° - 90°" 21 "0° - 90°" 22 "0° - 90°" 23 "0° - 90°" 24 "0° - 90°" 25 "0° - 90°" 26 "0° - 90°" 27 "0° - 90°" 28 "0° - 90°" 29 "0° - 90°" 30 "0° - 90°" 31 "0° - 90°" 32 "0° - 90°" 33 "0° - 90°" 34 "0° - 90°" 35 "0° - 90°" 36 "0° - 90°" 37 "0° - 90°" 38 "0° - 90°" 39 "0° - 90°" 40 "0° - 90°" 41 "0° - 90°" 42 "0° - 90°" 43 "0° - 90°" 44 "0° - 90°" 45 "0° - 90°" 46 "0° - 90°" 47 "0° - 90°" 48 "0° - 90°" 49 "0° - 90°" 50 "0° - 90°" 51 "0° - 90°" 52 "0° - 90°" 53 "0° - 90°" 54 "0° - 90°" 55 "0° - 90°" 56 "0° - 90°" 57 "0° - 90°" 58 "0° - 90°" 59 "0° - 90°" 60 "0° - 90°" 61 "0° - 90°" 62 "0° - 90°" 63 "0° - 90°" 64 "0° - 90°" 65 "0° - 90°" 66 "0° - 90°" 67 "0° - 90°" 68 "0° - 90°" 69 "0° - 90°" 70 "0° - 90°" 71 "0° - 90°" 72 "0° - 90°" 73 "0° - 90°" 74 "0° - 90°" 75 "0° - 90°" 76 "0° - 90°" 77 "0° - 90°" 78 "0° - 90°" 79 "0° - 90°" 80 "0° - 90°" 81 "0° - 90°" 82 "0° - 90°" 83 "0° - 90°" 84 "0° - 90°" 85 "0° - 90°" 86 "0° - 90°" 87 "0° - 90°" 88 "0° - 90°" 89 "0° - 90°" 90 "0° - 90°" 91 "Invalid" 92 "Invalid" 93 "Invalid" 94 "Invalid" 95 "Invalid" 96 "Invalid" 97 "Invalid" 98 "Invalid" 99 "Invalid" 100 "Unknown" 101 "Invalid" 102 "Invalid" 103 "Invalid" 104 "Invalid" 105 "Invalid" 106 "Invalid" 107 "Invalid" 108 "Invalid" 109 "Invalid" 110 "Invalid" 111 "Invalid" 112 "Invalid" 113 "Invalid" 114 "Invalid" 115 "Invalid" 116 "Invalid" 117 "Invalid" 118 "Invalid" 119 "Invalid" 120 "Invalid" 121 "Invalid" 122 "Invalid" 123 "Invalid" 124 "Invalid" 125 "Invalid" 126 "Invalid" 127 "Invalid" ;
VAL_ 830 RLDoorPushAlarm 0 "Off" 1 "On" 2 "RESERVED" 3 "Error Indicator" ;
VAL_ 830 RL_CrashUnlockCmd 0 "Off" 1 "Unlock(Crash)" ;
VAL_ 830 Warn_RrLftDrSwSta_SBCM 0 "Close" 1 "Open" 2 "RESERVED" 3 "Error Indicator" ;
VAL_ 830 DoorLock_RrLftDrUnLkSta_SBCM 0 "Lock" 1 "Unlock" 2 "RESERVED" 3 "Error Indicator" ;
VAL_ 830 RL_SEAActivated 0 "InActivated" 1 "Activated" 2 "RESERVED" 3 "Error Indicator" ;
VAL_ 830 RL_SEAWarn 0 "SEA Left Warning OFF" 1 "SEA Left Warning ON" 2 "RESERVED" 3 "RESERVED" ;
VAL_ 830 RL_SEWWarn 0 "SEW Left Warning OFF" 1 "SEW Left Warning ON" 2 "RESERVED" 3 "RESERVED" ;
VAL_ 830 RL_ReleaseWarn 0 "Release Warning OFF" 1 "Release Warning ON" 2 "RESERVED" 3 "RESERVED" ;
VAL_ 830 RL_SWFailAlarm 0 "Off" 1 "On" 2 "RESERVED" 3 "Error Indicator" ;
VAL_ 830 RL_ChildLock_ActnFlSta 0 "OK" 1 "Failed" 2 "RESERVED" 3 "Error Indicator" ;
VAL_ 830 RL_MRActivationAlarm 0 "Off" 1 "On" 2 "RESERVED" 3 "Error Indicator" ;
VAL_ 830 RL_ChildLock_Status 0 "ChildLock On" 1 "ChildLock Off" 2 "RESERVED" 3 "RESERVED" ;
VAL_ 256 EMS_Crc2Val 0 "0x0x0~0xFFFF:CRCValue" 65535 "0x0x0~0xFFFF:CRCValue" ;
VAL_ 256 ACC_CrsMainSwLmpSta 0 "Cruise MAIN switch indication lamp turn OFF" 1 "Cruise MAIN switch indication lamp turn ON" 2 "Not used" 3 "Error indicator" ;
VAL_ 256 ACC_CrsSetSwLmpSta 0 "Cruise SET switch indication lamp turn OFF" 1 "Cruise SET switch indication lamp turn ON" 2 "Not used" 3 "Error indicator" ;
VAL_ 256 ENG_LV_FUP_ENA_THD 0 "The pressure is too low to start engine" 1 "The pressure is enough high to start engine" ;
VAL_ 256 ENG_SoakTimeErrSta 0 "No Failure detected" 1 "Failure detected" 2 "Not used" 3 "Error indicator" ;
VAL_ 256 EMS_AlvCnt2Val 0 "0x0x0~0xFF:AlvCntValue" 255 "0x0x0~0xFF:AlvCntValue" ;
VAL_ 256 ENG_AppAccelPdlSta 0 "Accelerator pedal not pressed" 1 "Accelerator pedal pressed" 2 "Reserved" 3 "Accelerator pedal position sensor failure" ;
VAL_ 256 ENG_BrkCtrlReq 0 "Brake control request is not active" 1 "Brake control request is active" 2 "Not used" 3 "Error indicator" ;
VAL_ 256 ACC_DnShftCtrlReq 0 "Downshift control request is not active" 1 "Downshift request to 1st gear" 2 "Downshift request to 2nd gear" 3 "Downshift request to 3rd gear" 4 "Downshift request to 4th gear" 5 "Downshift request to 5th gear" 6 "Downshift request to 6th gear" 7 "Downshift request to 7th gear" 8 "Downshift request to 8th gear" 9 "Reserved" 10 "Reserved" 11 "Reserved" 12 "Reserved" 13 "Reserved" 14 "Reserved" 15 "Error indicator" ;
VAL_ 256 ENG_DclBrkCntrlReq 4095 "Error indicator" ;
VAL_ 256 ENG_BstPrsrVal 4095 "Error indicator" ;
VAL_ 256 ENG_EngOilTempVal 255 "Error indicator" ;
VAL_ 256 ENG_DpfWrngSta 0 "DPF Normal State" 1 "DPF Warning State Level 1" 2 "DPF Warning State Level 2" 3 "Reserved" ;
VAL_ 256 ENG_BattWrngLmpSta 0 "Battery Warning Lamp OFF" 1 "Battery Warning Lamp ON" 2 "Not used" 3 "Error indicator" ;
VAL_ 256 ENG_OilPrsrWrngLmpSta 0 "Oil Pressure Warning Lamp OFF" 1 "Oil Pressure Warning Lamp ON" 2 "Not used" 3 "Error indicator" ;
VAL_ 256 ENG_IsgInhbtLmpSta 0 "ISG Inhibit Lamp OFF" 1 "ISG Inhibit Lamp ON" 2 "Not used" 3 "Error indicator" ;
VAL_ 256 ENG_BrkSwSta 0 "Brake switch is not pressed (OFF)" 1 "Brake switch is pressed (ON)" 2 "EMS does not support this function." 3 "Brake switch failure" ;
VAL_ 256 ENG_EngClntTempVal 255 "Error indicator" ;
VAL_ 256 ENG_MafCrctVal 128 "Error indicator" ;
VAL_ 256 ENG_BattDscnctSta 0 "no battery disconnection detected" 1 "battery disconnection detected and failure memory erased" 2 "Not used" 3 "Error indicator" ;
VAL_ 256 OBD_MilConfgVal 0 "no MIL, Failure Memory Management OBD-I" 1 "MIL Treatment OBD-I, Failure Memory Management OBD-I" 2 "MIL Treatment OBD-II, Exception" 3 "MIL Treatment OBD-II, Failure Memory Management OBD-II" 4 "MIL Treatment E-OBD, Failure Memory Management E-OBD" 5 "MIL Treatment K-OBD, Failure Memory Management K-OBD" ;
VAL_ 256 ENG_EngSta 0 "Engine Stop" 1 "Cranking" 2 "Stalled" 3 "Running" 4 "Reserved" 5 "Reserved" 6 "Reserved" 7 "Fault" ;
VAL_ 256 ENG_Ack4EngStpSta 0 "No acknowledgement" 1 "Acknowledgement engine stopped" 2 "Not used" 3 "Error indicator" ;
VAL_ 256 ENG_OverDrvOffReq 0 "Normal operation" 1 "Over drive off request to TCU by the cruise control function" 2 "Not used" 3 "Error indicator" ;
VAL_ 256 ENG_AccActSta 0 "Auto cruise control is not active" 1 "Auto cruise control is active" 2 "Not used" 3 "Error indicator" ;
VAL_ 256 ENG_CltchOpSta 0 "Clutch is not operating" 1 "Clutch is operating" 2 "Not used" 3 "Error indicator" ;
VAL_ 256 EMS_BrkReq_Slope 0 "No Request" 1 "Brake Request" ;
VAL_ 256 ENG_AccDrvAlertDisp 0 "Default" 1 "Auto cruise Disengaged" 2 "No Auto cruise Engaged" 3 "Error indicator" ;
VAL_ 256 DSL_GlowCtrlReq 0 "Glow plug off request" 1 "Glow plug on request" 2 "System Error" 3 "Reserved" ;
VAL_ 256 ENG_GlowLmpSta 0 "Lamp Off" 1 "Lamp On" 2 "Not used" 3 "Error indicator" ;
VAL_ 256 ENG_ThrPosVal 32 "Idle (port value is learnt)" 245 "Throttle perpendicular" 255 "Throttle defective" ;
VAL_ 256 ENG_AccelPdlVal 0 "Accelerator Pedal not activated" 1022 "Accelerator Pedal fully activated" 1023 "Accelerator Pedal is defective (fail state) or Non-ETC system (APS is not installed), Error indicator" ;
VAL_ 1233 CLU_Crc5Val 0 "0x0x0~0xFFFF:CRCValue" 65535 "0x0x0~0xFFFF:CRCValue" ;
VAL_ 1233 CLU_AlvCnt5Val 0 "0x0x0~0xFF:AlvCntValue" 255 "0x0x0~0xFF:AlvCntValue" ;
VAL_ 1233 USM_TlgtAwayCloseSetReq 0 "Default(No Display)" 1 "Off" 2 "On" 3 "Invalid" ;
VAL_ 1233 USM_InletAutoLockSetReq 0 "Default" 1 "Auto Mode" 2 "Lock Mode" 3 "Unlock Mode" 4 "Reserved" 5 "Reserved" 6 "Reserved" 7 "Invalid" ;
VAL_ 1233 USM_IFSActVehSpd_Set 0 "Default" 1 "Vehicle Speed Function Off" 2 "10km/h" 3 "20" 4 "30" 5 "40" 6 "50" 7 "60" 8 "70" 9 "80" 10 "90" 11 "100" 12 "RESERVED" 13 "RESERVED" 14 "RESERVED" 15 "Invalid" ;
VAL_ 1233 USM_StaRst1Req 0 "Defualt" 1 "Reset" 2 "Not used" 3 "Error Indicator" ;
VAL_ 1233 USM_NccCamSetReq 0 "Not Applied" 1 "Function Off" 2 "Function On - Manual Resume" 3 "Function On - Automatic Resume" 4 "Reserved" 5 "Reserved" 6 "Reserved" 7 "Invalid" ;
VAL_ 1233 CLU_RrStRemindDelayReq 0 "default" 1 "delay request" 2 "RESERVED" 3 "Invalid" ;
VAL_ 1233 CLU_RrStRemindDelayFdbckReq 0 "Defualt" 1 "Delay" 2 "RESERVED" 3 "Invalid" ;
VAL_ 1233 USM_AdasLDW2SetReq 0 "Default" 1 "OFF" 2 "ON" 3 "INVALID" ;
VAL_ 1233 CLU_DTELearnResetReq 0 "Default" 1 "Reset_Req" 2 "RESERVED" 3 "Invalid" ;
VAL_ 1233 CLU_SelfRgnSetReq 0 "Default" 1 "Off" 2 "Ongoing" 3 "Invalid" ;
VAL_ 1233 CLU_PDWWrngSndMuteSoftKeySta 0 "Key Off" 1 "Key On" 2 "RESERVED" 3 "Invaild" ;
VAL_ 1233 CLU_IccPopupOffReq 0 "Default" 1 "On(Icc Pop-up off Request)" ;
VAL_ 870 HU_GW_Crc3Val 0 "0x0x0~0xFFFF:CRCValue" 65535 "0x0x0~0xFFFF:CRCValue" ;
VAL_ 870 AVN_RSPA_Disp_Rdy 0 "Impossible to display" 1 "Possible to display" 2 "RESERVED" 3 "Invalid" ;
VAL_ 870 CF_AVN_ProfileIDRValue 0 "Default" 1 "Guest" 2 "Profile 1" 3 "Profile 2" 4 "Profile 3" 5 "Profile 4" 6 "Profile 5" 7 "Profile 6" 8 "Profile 7" 9 "Profile 8" 10 "Profile 9" 11 "RESERVED" 12 "RESERVED" 13 "RESERVED" 14 "RESERVED" 15 "Invalid" ;
VAL_ 870 HazardFromHUSVM 0 "inactive" 1 "active" 2 "RESERVED" 3 "invalid" ;
VAL_ 870 OMUOSMirCtrl 0 "Off" 1 "Fold" 2 "Unfold" 3 "invalid" ;
VAL_ 870 OTAUIStatus 0 "Not Ready" 1 "Ready" 2 "RESERVED" 3 "Invalid" ;
VAL_ 870 C_TeleActiveStatus 0 "Active" 1 "Deactive" 2 "RESERVED" 3 "Invalid" ;
VAL_ 870 HU_RTCCheck 0 "Ready" 1 "Checking" 2 "RESERVED" 3 "Invalid" ;
VAL_ 870 HU_GW_AlvCnt3Val 0 "0x0x0~0xFF:AlvCntValue" 255 "0x0x0~0xFF:AlvCntValue" ;
VAL_ 870 HU_SWRCWarmerSet 0 "Off (Release)" 1 "On (Press)" 2 "RESERVED" 3 "Invalid" ;
VAL_ 870 HU_TrModeReq_PE 0 "Default" 1 "Trailer On" 2 "Carrier On" 3 "Off" 4 "RESERVED" 5 "RESERVED" 6 "RESERVED" 7 "Invalid" ;
VAL_ 870 HU_TrBrakeTypeReq_PE 0 "Default" 1 "Off" 2 "Light Electric" 3 "Heavy Electric" 4 "EOH Light" 5 "EOH Heavy" 6 "RESERVED" 7 "Invalid" ;
VAL_ 870 AVN_MRA_Disp_Rdy 0 "Impossible to display" 1 "Possible to display" 2 "RESERVED" 3 "Invalid" ;
VAL_ 870 AVN_PRK_Func_Selected 0 "Init" 1 "No input" 2 "RSPA Soft Button input" 3 "MRA Soft Button input" 4 "MPA Soft Button input" 5 "Add New Route Soft Button input" 6 "Route Management Soft Button input" 7 "Search_Slot_along_way Soft Button input" 8 "SVM Soft Button input" 9 "Remote Forward/Backward Soft Button input" 10 "RESERVED" 11 "RESERVED" 12 "RESERVED" 13 "RESERVED" 14 "RESERVED" 15 "Invalid" ;
VAL_ 870 AVN_MRA_CancelInput 0 "Init" 1 "No input" 2 "Cancel input" 3 "Invalid" ;
VAL_ 870 HU_DistanceUnit 0 "Km" 1 "Mile" 2 "RESERVED" 3 "Invalid" ;
VAL_ 870 HU_Scheduled_Setting 0 "Scheduled not set" 1 "Scheduled set" 2 "RESERVED" 3 "RESERVED" 4 "RESERVED" 5 "RESERVED" 6 "60% SoC Requested" 7 "70% SoC Requested" 8 "80% SoC Requested" 9 "90% SoC Requested" 10 "100% SoC Requested" 11 "RESERVED" 12 "RESERVED" 13 "RESERVED" 14 "RESERVED" 15 "Invalid" ;
VAL_ 870 HU_AliveStatus 0 "Not Ready" 1 "On Mode" 2 "Head Unit Update Mode" 3 "Invalid" ;
VAL_ 870 HU_ThemeType 0 "Default" 1 "Aqua(Hyundai)" 2 "Magenta(Kia)" 3 "Eco White" 4 "Eco Black" 5 "Genesis(IKPE)" 6 "Magenta White" 7 "RESERVED" 8 "RESERVED" 9 "RESERVED" 10 "RESERVED" 11 "RESERVED" 12 "RESERVED" 13 "RESERVED" 14 "RESERVED" 15 "Invalid" 16 "Copper" 17 "Copper Rust" 18 "RESERVED" 19 "RESERVED" 20 "RESERVED" 21 "RESERVED" 22 "RESERVED" 23 "RESERVED" 24 "RESERVED" 25 "RESERVED" 26 "RESERVED" 27 "RESERVED" 28 "RESERVED" 29 "RESERVED" 30 "RESERVED" 31 "RESERVED" 32 "ccIC Light" 33 "ccIC Dark" 34 "RESERVED" 35 "RESERVED" 36 "RESERVED" 37 "RESERVED" 38 "RESERVED" 39 "RESERVED" 40 "RESERVED" 41 "RESERVED" 42 "RESERVED" 43 "RESERVED" 44 "RESERVED" 45 "RESERVED" 46 "RESERVED" 47 "RESERVED" 48 "RESERVED" 49 "RESERVED" 50 "RESERVED" 51 "RESERVED" 52 "RESERVED" 53 "RESERVED" 54 "RESERVED" 55 "RESERVED" 56 "RESERVED" 57 "RESERVED" 58 "RESERVED" 59 "RESERVED" 60 "RESERVED" 61 "RESERVED" 62 "RESERVED" 63 "RESERVED" ;
VAL_ 870 HU_MicActivity 0 "Deactivated" 1 "Activated" 2 "RESERVED" 3 "Invalid" ;
VAL_ 870 AVN_RSPA_ModeSelect 0 "None" 1 "CCP focus (1st menu on the left)" 2 "Touch or CCP confirm (1st menu on the left)" 3 "CCP focus (2nd menu on the left)" 4 "Touch or CCP confirm (2nd menu on the left)" 5 "CCP focus (1st menu on the right)" 6 "Touch or CCP confirm (1st menu on the right)" 7 "CCP focus (2nd menu on the right)" 8 "Touch or CCP confirm (2nd menu on the right)" 9 "Touch or CCP confirm (1st menu Forward perpendicular on the left)" 10 "Touch or CCP confirm (2nd menu Forward perpendicular on the left)" 11 "Touch or CCP confirm (1st menu Forward perpendicular on the right)" 12 "Touch or CCP confirm (2nd menu Forward perpendicular on the right)" 13 "RESERVED" 14 "RESERVED" 15 "Invalid" ;
VAL_ 870 CF_HU_GPSFlt 0 "Normal" 1 "Fault operation" 2 "TimeOut" 3 "Invalid" ;
VAL_ 870 AVN_RSPA_CancelInput 0 "Init" 1 "No Input" 2 "Cancel Input" 3 "Invalid" ;
VAL_ 261 EMS_Crc7Val 0 "0x0x0~0xFFFF:CRCValue" 65535 "0x0x0~0xFFFF:CRCValue" ;
VAL_ 261 HEV_AccelPdlVal 0 "Accelerator Pedal not activated" 1022 "Accelerator Pedal fully activated" 1023 "Accelerator Pedal is defective (fail state) or Non-ETC system (APS is not installed)" ;
VAL_ 261 HEV_IndTqVal_Extd 0 "0x0x0000~0x3FFF:Physical Value (0~1638.3Nm)" 16383 "0x0x0000~0x3FFF:Physical Value (0~1638.3Nm)" ;
VAL_ 261 EMS_AlvCnt7Val 0 "0x0x0~0xFF:AlvCntValue" 255 "0x0x0~0xFF:AlvCntValue" ;
VAL_ 261 HEV_OilDilution_IncICELoad 0 "OFF" 1 "ON" ;
VAL_ 261 HEV_OilDilution_ServMode 0 "OFF" 1 "Healing I" 2 "Healing II" 3 "RESERVED" ;
VAL_ 261 EMS_TqLmtSta 0 "Default/Normal" 1 "O2 Sensor Pre-Heating - To be Started" 2 "O2 Sensor Pre-Heating - Can be Started" 3 "Torque Limit for Low Temperature (Catalyst Heating)" 4 "Torque Ramping" 5 "Warming up" 6 "Torque Limit for High Temperature (Catalyst Overheating Protection)" 7 "Error" ;
VAL_ 261 EMS_EU7 0 "Not EU7 vehicle" 1 "EU7 vehicle" ;
VAL_ 261 HEV_EngOpSta 0 "ES(Engine Stop)" 1 "ST(Start)" 2 "IS(Idle speed)" 3 "PL(Part Load)" 4 "PU(Pull)" 5 "PUC(Fuel Cut off)" ;
